; Merged AEE2010 HS1, HS2, EPS dbc files
VERSION "AEE2010_R3_HS1_HS2_EPS_merge"

NS_ :

BS_:

BU_: UTIL__Traminator CMM___Motor_SG CDS___Fahrdynamikregelung BVA___Automatikgetriebe BSI___Kombiinstrument AR2S_StartStop ABS___Antiblockiersystem AVAS RITCS PASS_HCU2 BVN EBB PASS_VCU BSI AAS PASS_BSI FAMILLE_DSG BV CAPT_ALG CAPT_VOL CMM CSS FSE OUTIL_DIAG PROJ SBW SCDT SUSP UC_DIRA UC_FREIN ASR ARTIV PASS_BSM CMF HCU1 HCU2 ECR MCM Tester PSCM
; #############################################################################
; ############################### HS1 B0 #####################################
; #############################################################################

BO_ 3221225472 VECTOR__INDEPENDENT_SIG_MSG: 0 Vector__XXX
 SG_ CURRENT_TIMER_YEAR : 0|8@0+ (1,0) [0|0] "" Vector__XXX
 # Description: Represents the current year used internally by the system timer.
 SG_ CURRENT_TIMER_DAY : 0|12@0+ (1,0) [0|0] "" Vector__XXX
 # Description: Represents the current day used internally by the system timer.
 SG_ CURRENT_TIMER_SECOND : 0|20@0+ (1,0) [0|0] "" Vector__XXX
 # Description: Represents the current second used internally by the system timer.
 SG_ TRANSMISSION_CHECKSUM : 0|4@1+ (1,0) [0|0] "" Vector__XXX
 # Description: Checksum used for verifying transmission data integrity.
 SG_ ENGINE_OFF_TIME_LSB : 0|16@1+ (1,0) [0|65535] "" Vector__XXX
 # Description: Lower 16 bits of engine-off time counter.
 SG_ ENGINE_OFF_TIME_MSB : 0|16@1+ (1,0) [0|65535] "" Vector__XXX
 # Description: Upper 16 bits of engine-off time counter.
 SG_ WAKEUP_REQUEST : 0|1@1+ (1,0) [0|1] "" Vector__XXX
 # Description: Indicates a request to wake up the vehicle’s electronic modules.
 SG_ IMPULSE_START_REQUEST : 0|2@1+ (1,0) [0|3] "" Vector__XXX
 # Description: Request for an impulse-based engine start.
 SG_ MAJOR_START_REQUEST : 0|2@1+ (1,0) [0|3] "" Vector__XXX
 # Description: Main request to start the engine under normal conditions.
 SG_ STARTER_STOP_REQUEST : 0|1@1+ (1,0) [0|1] "" Vector__XXX
 # Description: Indicates a request to stop the starter operation.
 SG_ EHR_CONTROL_STATUS : 0|1@1- (1,0) [0|1] "" Vector__XXX
 # Description: Status bit for Electric Heater Relay (EHR) control.
 SG_ BVM_CHECKSUM : 0|4@1+ (1,0) [0|15] "" Vector__XXX
 # Description: Checksum for manual gearbox message.
 SG_ BVM_COUNTER : 0|4@1+ (1,0) [0|15] "" Vector__XXX
 # Description: Counter for manual gearbox message transmissions.
 SG_ GEARBOX_TORQUE_REQUEST_STATUS : 0|1@1+ (1,0) [0|1] "" Vector__XXX
 # Description: Indicates if a torque request has been issued by the gearbox.
 SG_ TORQUE_SATURATION_ACTIVE : 0|1@1+ (1,0) [0|1] "-" Vector__XXX
 # Description: Indicates whether torque saturation is currently active.
 SG_ FORCED_GMV_ENGAGEMENT : 0|1@1+ (1,0) [0|1] "-" Vector__XXX
 # Description: Indicates forced engagement of the GMV (motorized valve) system.
 SG_ TOTAL_ADDITIONAL_PUMP_MASS : 0|16@0+ (0.05,0) [0|3276.5] "g" Vector__XXX
 # Description: Total mass of additional fluid pumped, measured in grams.
 SG_ LOCAL_IDENTIFIER : 0|8@1+ (1,0) [0|255] "" Vector__XXX
 # Description: Local identification value for internal usage.
 SG_ DIAGNOSTIC_ON_CAN : 0|8@1+ (1,0) [0|255] "" Vector__XXX
 # Description: Indicates a diagnostic session or request on the CAN bus.
 SG_ EOBD_READINESS : 0|1@1+ (1,0) [0|1] "" Vector__XXX
 # Description: Indicates EOBD (European On-Board Diagnostics) readiness status.
 SG_ MAX_TORQUE_STATUS : 0|1@1+ (1,0) [0|1] "" Vector__XXX
 # Description: Indicates whether the maximum torque status is reached.
 SG_ MAX_ENGINE_SPEED_STATUS : 0|1@1+ (1,0) [0|1] "" Vector__XXX
 # Description: Indicates whether the maximum engine speed status is reached.
 SG_ RTE_FUNCTION_ERROR_STATUS : 0|1@1+ (1,0) [0|1] "" Vector__XXX
 # Description: Indicates an error in the runtime environment function.
 SG_ ADDITIONAL_PUMP_VOLUME_INJECTION_STEP : 0|8@1+ (10,0) [0|255] "" Vector__XXX
 # Description: Represents the additional pump volume per injection step in increments of 10.
 SG_ GEARBOX_INPUT_SPEED_FILTERED : 0|12@0+ (2,0) [0|0] "rpm" Vector__XXX
 # Description: Filtered input speed of the gearbox, in revolutions per minute.
 SG_ CONVERTER_SLIP_REDUCED_TORQUE : 0|8@1- (3,-150) [0|0] "Nm" Vector__XXX
 # Description: Reduced converter torque used for slip control, in Newton-meters.
 SG_ TSC_ENGINE_DEMAND_TYPE : 0|1@1+ (1,0) [0|1] "" Vector__XXX
 # Description: Type of engine demand used by the TSC (Torque Security Calculation).
 SG_ CLUTCH_STATE : 0|2@1+ (1,0) [0|3] "" Vector__XXX
 # Description: Indicates the current clutch state or position.
 SG_ GLOW_AUTHORIZATION_STATUS : 0|1@1+ (1,0) [0|1] "" Vector__XXX
 # Description: Shows whether glow plugs are authorized to operate.
 SG_ AR2S_SYSTEM_STATUS : 0|2@1+ (1,0) [0|3] "" Vector__XXX
 # Description: Status of the AR2S start-stop system.
 SG_ STT_RELAUNCH_STATUS : 0|2@1+ (1,0) [0|3] "" Vector__XXX
 # Description: Indicates start-stop engine relaunch authorization.
 SG_ POWER_GENERATOR_SUPPORT_STATE : 0|1@1+ (1,0) [0|1] "" Vector__XXX
 # Description: Shows if the power generator is in a support state.
 SG_ REQUESTED_GEARBOX_TORQUE : 0|8@1+ (2,-100) [-100|408] "Nm" Vector__XXX
 # Description: Torque request that accounts for gearbox demands, in Nm.
 SG_ ACTUAL_ENGINE_TORQUE_NO_GEARBOX : 0|8@1+ (2,-100) [-100|408] "Nm" Vector__XXX
 # Description: Actual engine torque excluding gearbox influence, in Nm.
 SG_ PRODUCTION_STATUS : 0|3@1+ (1,0) [0|7] "" Vector__XXX
 # Description: Indicates the current production or assembly status of the system.
 SG_ ALTERNATOR_FAULT : 0|1@1+ (1,0) [0|1] "" Vector__XXX
 # Description: Signals a detected fault in the alternator.
 SG_ SECONDARY_START_REQUEST : 0|2@1+ (1,0) [0|3] "" Vector__XXX
 # Description: A secondary engine start request, possibly for backup or redundancy.
 SG_ ADDITIONAL_PUMP_LEVEL_STATUS : 0|2@1+ (1,0) [0|3] "" Vector__XXX
 # Description: Current level status of the additional pump.
 SG_ FAP_AVAILABLE_TEMPERATURE : 0|8@1+ (4,-40) [0|255] "°C" Vector__XXX
 # Description: Temperature measurement related to FAP (Diesel Particulate Filter) availability.
 SG_ RVV_COMMAND : 0|2@1+ (1,0) [0|3] "-" Vector__XXX
 # Description: Command bitfield for the RVV (valve or variable geometry) system.
 SG_ RVV_ACTIVATION : 0|1@1+ (1,0) [0|1] "-" Vector__XXX
 # Description: Indicates whether the RVV system is activated.
 SG_ ABS_DISTANCE : 0|16@0+ (0.1,0) [0|6553.5] "m" Vector__XXX
 # Description: Accumulated or measured distance from the ABS system, in meters.
 SG_ RELAY_2_DIAGNOSTIC_RAW : 0|3@1- (1,0) [-4|3] "" Vector__XXX
 # Description: Raw diagnostic value for relay 2.
 SG_ RELAY_1_DIAGNOSTIC_RAW : 0|3@1- (1,0) [0|7] "" Vector__XXX
 # Description: Raw diagnostic value for relay 1.
 SG_ PARTIAL_BYTE_8_STATUS : 0|4@1+ (1,0) [0|15] "" Vector__XXX
 # Description: 4-bit status stored in byte 8, used for partial checks.
 SG_ RESERVED_1 : 0|16@1+ (1,0) [0|255] "-" Vector__XXX
 # Description: Reserved placeholder for future use or alignment.
 SG_ START_STOP_CABIN_REQUEST_RAW : 0|1@1+ (1,0) [0|1] "" Vector__XXX
 # Description: Indicates a raw cabin request related to start-stop operation.
 SG_ INPUT_4 : 0|1@0+ (1,0) [0|0] "" Vector__XXX
 # Description: Generic input 4 placeholder signal for hardware or software usage.
 SG_ INPUT_3 : 0|1@0+ (1,0) [0|0] "" Vector__XXX
 # Description: Generic input 3 placeholder signal for hardware or software usage.
 SG_ INPUT_2 : 0|1@0+ (1,0) [0|0] "" Vector__XXX
 # Description: Generic input 2 placeholder signal for hardware or software usage.
 SG_ INPUT_1 : 0|1@0+ (1,0) [0|0] "" Vector__XXX
 # Description: Generic input 1 placeholder signal for hardware or software usage.
 SG_ CODE_VALUE : 0|8@0+ (1,0) [0|0] "" Vector__XXX
 # Description: Arbitrary code value used for internal processes.
 SG_ OUTPUT_NUMBER : 0|3@0+ (1,0) [0|0] "" Vector__XXX
 # Description: Indicates which output is currently being referenced.
 SG_ OUTPUT_3 : 0|1@0+ (1,0) [0|0] "" Vector__XXX
 # Description: Generic output 3 placeholder signal for hardware or software usage.
 SG_ OUTPUT_2 : 0|1@0+ (1,0) [0|0] "" Vector__XXX
 # Description: Generic output 2 placeholder signal for hardware or software usage.
 SG_ OUTPUT_1 : 0|1@0+ (1,0) [0|0] "" Vector__XXX
 # Description: Generic output 1 placeholder signal for hardware or software usage.
 SG_ OUTPUT_0 : 0|1@0+ (1,0) [0|0] "" Vector__XXX
 # Description: Generic output 0 placeholder signal for hardware or software usage.
 SG_ COMMAND : 0|5@0+ (1,0) [0|0] "" Vector__XXX
 # Description: Generic command signal used in various control processes.
 SG_ FANS_EHR_PUMP_REQUEST : 0|1@1+ (1,0) [0|1] "" Vector__XXX
 # Description: Request for the EHR (electric heater) pump to operate fans.
 SG_ FUEL_CONSUMPTION_STATUS : 0|1@1+ (1,0) [0|0] "" Vector__XXX
 # Description: Status indicating fuel consumption measurement progress.
 SG_ ENGINE_PROTECTION_OVERSPEED_STATUS : 0|2@1+ (1,0) [0|1] "-" Vector__XXX
 # Description: Signals overspeed protection status for the engine.
 SG_ ACCD_PRESSURE_STATUS : 0|2@1+ (1,0) [0|3] "-" Vector__XXX
 # Description: Status of the air conditioning compressor demand (ACCD) pressure.
 SG_ AC_CONTROL_HYSTERESIS_STATUS : 0|1@1+ (1,0) [0|1] "-" Vector__XXX
 # Description: Indicates hysteresis control activity in the air conditioning system.
 SG_ MIL_REQUEST : 0|1@1+ (1,0) [0|1] "-" Vector__XXX
 # Description: Malfunction Indicator Lamp request bit.
 SG_ VERSION_INPUT : 0|4@0+ (1,0) [0|0] "" Vector__XXX
 # Description: Input version number for calibration or firmware identification.
 SG_ DATA_1 : 0|8@0+ (1,0) [0|0] "" Vector__XXX
 # Description: Generic data byte 1 for internal usage.
 SG_ MASK_0 : 0|8@0+ (1,0) [0|0] "" Vector__XXX
 # Description: Mask register 0 used for data filtering or validation.
 SG_ MASK_1 : 0|8@0+ (1,0) [0|0] "" Vector__XXX
 # Description: Mask register 1 used for data filtering or validation.
 SG_ VERSION_MODE : 0|4@0+ (1,0) [0|0] "" Vector__XXX
 # Description: Operating mode version identifier.
 SG_ VERSION_ACTEL : 0|1@0+ (1,0) [0|0] "" Vector__XXX
 # Description: Indicates the version related to the Actel device or logic.
 SG_ VERSION_BAUD_RATE : 0|3@0+ (1,0) [0|0] "" Vector__XXX
 # Description: Baud rate setting version for the communication interface.
 SG_ DATA_0 : 0|8@0+ (1,0) [0|0] "" Vector__XXX
 # Description: Generic data byte 0 for internal usage.
 SG_ DATA_2 : 0|8@0+ (1,0) [0|0] "" Vector__XXX
 # Description: Generic data byte 2 for internal usage.
 SG_ MASK_2 : 0|8@0+ (1,0) [0|0] "" Vector__XXX
 # Description: Mask register 2 used for data filtering or validation.
 SG_ DATA_3 : 0|8@0+ (1,0) [0|0] "" Vector__XXX
 # Description: Generic data byte 3 for internal usage.
 SG_ MASK_3 : 0|8@0+ (1,0) [0|0] "" Vector__XXX
 # Description: Mask register 3 used for data filtering or validation.
 SG_ RATE_VALUE : 0|8@0+ (1,0) [0|0] "" Vector__XXX
 # Description: A rate value or index used for calibrations or internal computations.
 SG_ VERSION_YEAR : 0|8@0+ (1,0) [0|0] "" Vector__XXX
 # Description: Year component of version information.
 SG_ DATA_4 : 0|8@0+ (1,0) [0|0] "" Vector__XXX
 # Description: Generic data byte 4 for internal usage.
 SG_ MASK_4 : 0|8@0+ (1,0) [0|0] "" Vector__XXX
 # Description: Mask register 4 used for data filtering or validation.
 SG_ VERSION_MONTH : 0|8@0+ (1,0) [0|0] "" Vector__XXX
 # Description: Month component of version information.
 SG_ CONFIG_ID_STATUS : 0|11@0+ (1,0) [0|0] "" Vector__XXX
 # Description: Indicates the status of a configuration ID or coding routine.
 SG_ DATA_5 : 0|8@0+ (1,0) [0|0] "" Vector__XXX
 # Description: Generic data byte 5 for internal usage.
 SG_ GET_CONFIG_ID_STATUS : 0|11@0+ (1,0) [0|0] "" Vector__XXX
 # Description: Request or read-back status of the configuration ID.
 SG_ MASK_5 : 0|8@0+ (1,0) [0|0] "" Vector__XXX
 # Description: Mask register 5 used for data filtering or validation.
 SG_ MASK_ID_PERT : 0|11@0+ (1,0) [0|0] "" Vector__XXX
 # Description: Perturbation ID or mask used for debug or test scenarios.
 SG_ VERSION_DATE : 0|8@0+ (1,0) [0|0] "" Vector__XXX
 # Description: Day component of version information (date).
 SG_ DATA_6 : 0|8@0+ (1,0) [0|0] "" Vector__XXX
 # Description: Generic data byte 6 for internal usage.
 SG_ MASK_6 : 0|8@0+ (1,0) [0|0] "" Vector__XXX
 # Description: Mask register 6 used for data filtering or validation.
 SG_ VERSION_MINOR : 0|8@0+ (1,0) [0|0] "" Vector__XXX
 # Description: Minor version number for software or configuration.
 SG_ EDGE_VALUE : 0|2@0+ (1,0) [0|0] "" Vector__XXX
 # Description: Indicates the active edge or transition setting for a signal.
 SG_ CONFIG_ID_CODE : 0|11@0+ (1,0) [0|0] "" Vector__XXX
 # Description: Configuration ID code used for system setup or calibration.
 SG_ DATA_7 : 0|8@1+ (1,0) [0|0] "" Vector__XXX
 # Description: Generic data byte 7 for internal usage.
 SG_ GET_CONFIG_ID_CODE : 0|11@0+ (1,0) [0|0] "" Vector__XXX
 # Description: Request or read-back code for the configuration ID.
 SG_ PERT_ID : 0|11@0+ (1,0) [0|0] "" Vector__XXX
 # Description: Identifier for an internal or external perturbation or test.
 SG_ MASK_7 : 0|8@0+ (1,0) [0|0] "" Vector__XXX
 # Description: Mask register 7 used for data filtering or validation.
 SG_ VERSION_MAJOR : 0|8@0+ (1,0) [0|0] "" Vector__XXX
 # Description: Major version number for software or configuration.
 SG_ CODE_COMMAND : 0|5@0+ (1,0) [0|0] "" Vector__XXX
 # Description: Command code used for controlling or referencing a state machine.
 SG_ SCENARIO_NUMBER : 0|3@0+ (1,0) [0|0] "" Vector__XXX
 # Description: Scenario or case number for testing or logic branching.
 SG_ TCS_ABSOLUTE_TORQUE : 0|8@1+ (2,-100) [-100|408] "Nm" Vector__XXX
 # Description: Absolute torque value requested by TCS (Traction Control System).
 SG_ GEARBOX_EOBD_FAULT : 0|4@1+ (1,0) [0|15] "-" Vector__XXX
 # Description: Indicates the EOBD fault status of the gearbox.
 SG_ BATTERY_TYPE_ESTIMATION_RAW : 0|2@1+ (1,0) [0|3] "" Vector__XXX
 # Description: Raw estimation of the installed battery type.
 SG_ PREDICTED_VOLTAGE_START_RAW : 0|11@0+ (0.01,0) [0|13] "" Vector__XXX
 # Description: Raw predicted voltage level at engine start.
 SG_ PART_BYTE_6_STATUS : 0|4@0+ (1,0) [0|15] "" Vector__XXX
 # Description: 4-bit status stored in byte 6, used for partial checks.
 SG_ BRAKE_RAW_1 : 0|1@1+ (1,0) [0|1] "" Vector__XXX
 # Description: Raw brake signal status from brake switch 1.
 SG_ BRAKE_1 : 0|1@1+ (1,0) [0|1] "" Vector__XXX
 # Description: Processed brake status derived from brake switch 1.
;TODO
;BO_ 968 Dyn_STT_CMM: 2 Vector__XXX
; SG_ P412_Com_stDeadPnt : 2|2@1+ (1,0) [0|3] "" Vector__XXX
; SG_ P428_Com_stCDTReq : 6|2@1+ (1,0) [0|3] "" Vector__XXX

BO_ 2024 Rep_EOBD_On_Can_7E8: 8 Vector__XXX

BO_ 2016 Req_EOBD_On_Can_7E0: 8 Vector__XXX

BO_ 2015 Req_EOBD_On_Can_7DF: 8 Vector__XXX

BO_ 1672 Rep_Diag_On_CAN_688: 8 Vector__XXX

BO_ 1704 Req_Diag_On_CAN_6A8: 8 Vector__XXX
;TODO
;BO_ 1266 Dat3_BSI: 8 Vector__XXX
; SG_ P494_Com_stPrioVoltMax : 49|2@0+ (1,0) [0|0] "" Vector__XXX
; SG_ P493_Com_stPrioVoltMin : 41|2@0+ (1,0) [0|0] "" Vector__XXX
; SG_ P492_Com_uVarProdMax : 63|7@0+ (1,0) [0|0] "" Vector__XXX
; SG_ P491_Com_uVoltCtlProdMax : 55|6@0+ (1,0) [0|0] "" Vector__XXX
; SG_ P490_Com_uVoltCtlProdMin : 47|6@0+ (1,0) [0|0] "" Vector__XXX
; SG_ P437_Com_uBattOpnCir : 24|9@0+ (0.01,0) [0|14] "" Vector__XXX
; SG_ P438_Com_uBattIntRstnRaw : 23|10@0+ (0.01,0) [0|10.23] "" Vector__XXX
; SG_ P429_Com_stSOCInfoInvldRaw : 8|2@1+ (1,0) [0|3] "" Vector__XXX
; SG_ P435_Com_stUCAPRechCrntRaw : 10|2@1+ (1,0) [0|3] "" Vector__XXX
; SG_ P434_Com_rBattChHiRes : 7|10@0+ (0.1,0) [0|100] "" Vector__XXX
;TODO
;BO_ 1173 DAT_DIRA: 3 Vector__XXX
; SG_ P448_Com_bStrgWhlEngStopReqRaw : 21|1@1+ (1,0) [0|1] "" Vector__XXX
; SG_ P447_Com_bStrgWhlEngRstrtReqRaw : 23|1@1+ (1,0) [0|1] "" Vector__XXX
;TODO
;BO_ 809 Dyn_STT_BV: 4 BVA___Automatikgetriebe
; SG_ P340_Com_xChkSum3 : 7|4@0+ (1,0) [0|0] "" Vector__XXX
; SG_ P230_Com_ctGbxCnt3 : 3|4@0+ (1,0) [0|15] "" Vector__XXX
; SG_ P441_Com_bGbxAuthRstrtRaw : 12|1@1+ (1,0) [0|1] "" Vector__XXX
; SG_ P444_Com_bGbxSysFaultRaw : 13|1@1+ (1,0) [0|1] "" Vector__XXX
; SG_ P442_Com_bGbxAuthStopRaw : 15|1@1+ (1,0) [0|1] "" Vector__XXX
; SG_ P443_Com_bGbxRstrtReq : 14|1@1+ (1,0) [0|1] "" Vector__XXX

BO_ 488 DAT3_CMM: 3 Vector__XXX
 SG_ RESERVED_3 : 5|6@0+ (1,0) [0|0] "" Vector__XXX
 # Description: Reserved for future use or alignment in the data structure.
 SG_ RESTART_STSP_COUNTER : 15|16@0+ (1,0) [0|3276750] "" Vector__XXX
 # Description: Counter tracking the number of start-stop restarts.
 SG_ RESTART_STSP_PROGRESS_STATUS : 7|2@0+ (1,0) [0|3] "" Vector__XXX
 # Description: Indicates the current progress status of a start-stop restart sequence.
;TODO
;BO_ 1375 ACQ_NEW_JDD: 1 Vector__XXX
; SG_ P__JDD_Com_stFaultAck : 7|8@0+ (1,0) [0|255] "" Vector__XXX
;TODO
;BO_ 1554 Dat7_BSI: 8 Vector__XXX
; SG_ P409_Com_stRly3DiagRaw : 61|3@1+ (1,0) [0|7] "" Vector__XXX

BO_ 1458 Contexte1_5B2: 8 Vector__XXX
 SG_ EOBD_STATUS : 39|8@0+ (1,0) [0|255] "-" Vector__XXX
 # Description: Indicates the overall EOBD (European On-Board Diagnostics) status code.
 SG_ ADDITIONAL_PUMP_DEFECT_STATUS : 24|8@1+ (1,0) [0|255] "-" Vector__XXX
 # Description: Status code indicating a defect with the additional pump system.
 SG_ ENVIRONMENT_TEMPERATURE : 16|8@1+ (0.5,-40) [-40|87] "°C" Vector__XXX
 # Description: Ambient temperature measured around the environment sensor.
;TODO
;BO_ 1362 DAT4_BSI_AEE2010: 8 Vector__XXX
; SG_ P015_Com_lTotDst : 39|24@0+ (1,0) [0|16777215] "km" Vector__XXX
; SG_ P325_Com_tiEngOff : 7|32@0+ (1,0) [0|1000] "" Vector__XXX
; SG_ P326_Com_ctTmrRst : 63|8@0+ (1,0) [0|255] "" Vector__XXX

BO_ 1101 Vroues_ABR: 8 CDS___Fahrdynamikregelung
 SG_ WHEEL_SPEED_AVERAGE : 55|16@0+ (0.04,0) [0|0] "rpm" Vector__XXX
 # Description: Average wheel speed calculated by the ABS/ESP system, in rpm.
 SG_ REAR_RIGHT_WHEEL_SPEED : 39|16@0+ (0.01,0) [0|655.34] "km/h" Vector__XXX
 # Description: Speed of the rear-right wheel, in km/h.
 SG_ REAR_LEFT_WHEEL_SPEED : 23|16@0+ (0.01,0) [0|655.34] "km/h" Vector__XXX
 # Description: Speed of the rear-left wheel, in km/h.
;TODO
;BO_ 1293 Dat_ABR: 7 ABS___Antiblockiersystem
; SG_ P415_Com_stABSSTTReqRaw : 52|2@1+ (1,0) [0|3] "" Vector__XXX
; SG_ P351_Com_bABSIntvActv : 5|1@1+ (1,0) [0|1] "" Vector__XXX

BO_ 781 Dyn4_FRE: 8 CDS___Fahrdynamikregelung
 SG_ FRONT_LEFT_PASSIVE_WHEEL_SPEED : 7|16@0+ (0.01,0) [0|655.35] "km/h" Vector__XXX
 # Description: Passive measurement of the front-left wheel speed, in km/h.
 SG_ FRONT_RIGHT_PASSIVE_WHEEL_SPEED : 23|16@0+ (0.01,0) [0|655.35] "km/h" Vector__XXX
 # Description: Passive measurement of the front-right wheel speed, in km/h.
 SG_ REAR_LEFT_PASSIVE_WHEEL_SPEED : 39|16@0+ (0.01,0) [0|655.35] "km/h" Vector__XXX
 # Description: Passive measurement of the rear-left wheel speed, in km/h.
 SG_ REAR_RIGHT_PASSIVE_WHEEL_SPEED : 55|16@0+ (0.01,0) [0|655.35] "km/h" Vector__XXX
 # Description: Passive measurement of the rear-right wheel speed, in km/h.
;TODO
;BO_ 1426 Dat6_BSI: 8 CMM___Motor_SG
; SG_ P421_Com_xBattCrnt : 55|16@0+ (1,0) [0|0] "" Vector__XXX
; SG_ P420_Com_stBattCrntMeasRaw : 40|2@1+ (1,0) [0|3] "" Vector__XXX
; SG_ P418_Com_uBattRaw : 28|11@0+ (0.01,5) [5|25.47] "" Vector__XXX
; SG_ P419_Com_stSTTActvRaw : 44|2@1+ (1,0) [0|3] "" Vector__XXX
; SG_ P349_EEM_stAltCtlType : 29|3@1+ (1,0) [0|7] "" Vector__XXX
; SG_ P273_Com_tBatt : 8|8@1+ (0.5,-30) [-30|97.5] "deg C" Vector__XXX
; SG_ P272_Com_rBattCh : 0|8@1+ (1,0) [0|100] "%" Vector__XXX

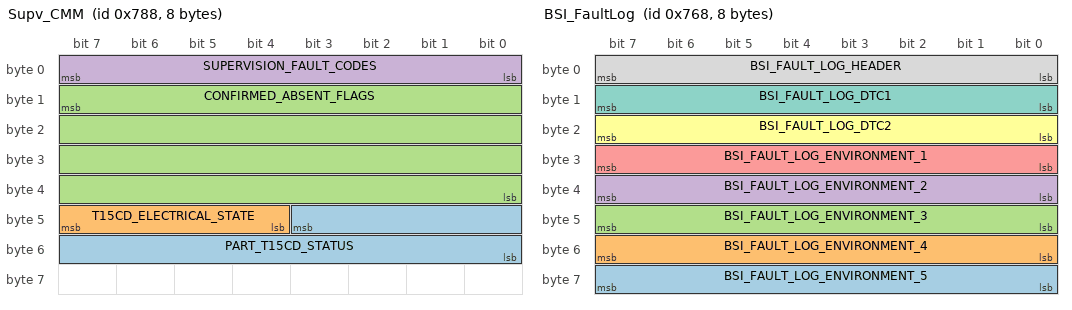
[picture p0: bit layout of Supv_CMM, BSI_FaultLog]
BO_ 1928 Supv_CMM: 8 CMM___Motor_SG
 SG_ PART_T15CD_STATUS : 43|12@0+ (1,0) [0|4095] "" Vector__XXX
 # Description: Status of partial T15CD signals (12-bit field) for supervision.
 SG_ T15CD_ELECTRICAL_STATE : 44|4@1+ (1,0) [0|15] "" Vector__XXX
 # Description: Electrical state representation for T15CD signal.
 SG_ CONFIRMED_ABSENT_FLAGS : 15|32@0+ (1,0) [0|4294967295] "-" Vector__XXX
 # Description: Bitmap flags indicating confirmed absent signals or components.
 SG_ SUPERVISION_FAULT_CODES : 7|8@0+ (1,0) [0|255] "-" Vector__XXX
 # Description: Fault codes used in supervision for diagnosing system issues.
;TODO
;BO_ 1906 FaultLog_Ack: 1 BSI___Kombiinstrument
; SG_ P__FaultLog_Ack : 0|8@1+ (1,0) [0|255] "" Vector__XXX

BO_ 1896 BSI_FaultLog: 8 CMM___Motor_SG
 SG_ BSI_FAULT_LOG_ENVIRONMENT_5 : 56|8@1+ (1,0) [0|255] "" Vector__XXX
 # Description: Environment data snapshot 5 for BSI fault logging.
 SG_ BSI_FAULT_LOG_ENVIRONMENT_4 : 48|8@1+ (1,0) [0|255] "" Vector__XXX
 # Description: Environment data snapshot 4 for BSI fault logging.
 SG_ BSI_FAULT_LOG_ENVIRONMENT_3 : 40|8@1+ (1,0) [0|255] "" Vector__XXX
 # Description: Environment data snapshot 3 for BSI fault logging.
 SG_ BSI_FAULT_LOG_ENVIRONMENT_2 : 32|8@1+ (1,0) [0|255] "" Vector__XXX
 # Description: Environment data snapshot 2 for BSI fault logging.
 SG_ BSI_FAULT_LOG_ENVIRONMENT_1 : 24|8@1+ (1,0) [0|255] "" Vector__XXX
 # Description: Environment data snapshot 1 for BSI fault logging.
 SG_ BSI_FAULT_LOG_DTC2 : 16|8@1+ (1,0) [0|255] "" Vector__XXX
 # Description: Second stored DTC (Diagnostic Trouble Code) value in the BSI fault log.
 SG_ BSI_FAULT_LOG_DTC1 : 8|8@1+ (1,0) [0|255] "" Vector__XXX
 # Description: First stored DTC (Diagnostic Trouble Code) value in the BSI fault log.
 SG_ BSI_FAULT_LOG_HEADER : 0|8@1+ (1,0) [0|255] "" Vector__XXX
 # Description: Header byte identifying the BSI fault log structure.

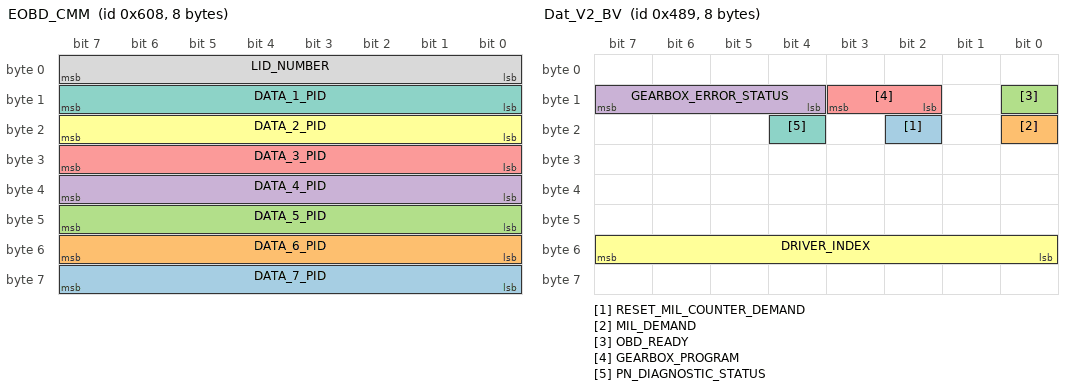
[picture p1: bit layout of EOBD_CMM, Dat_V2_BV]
BO_ 1544 EOBD_CMM: 8 CMM___Motor_SG
 SG_ DATA_7_PID : 56|8@1+ (1,0) [0|0] "" Vector__XXX
 # Description: Byte 7 PID data for EOBD requests or responses.
 SG_ DATA_6_PID : 48|8@1+ (1,0) [0|0] "" Vector__XXX
 # Description: Byte 6 PID data for EOBD requests or responses.
 SG_ DATA_5_PID : 40|8@1+ (1,0) [0|0] "" Vector__XXX
 # Description: Byte 5 PID data for EOBD requests or responses.
 SG_ DATA_4_PID : 32|8@1+ (1,0) [0|0] "" Vector__XXX
 # Description: Byte 4 PID data for EOBD requests or responses.
 SG_ DATA_3_PID : 24|8@1+ (1,0) [0|0] "" Vector__XXX
 # Description: Byte 3 PID data for EOBD requests or responses.
 SG_ DATA_2_PID : 16|8@1+ (1,0) [0|0] "" Vector__XXX
 # Description: Byte 2 PID data for EOBD requests or responses.
 SG_ DATA_1_PID : 8|8@1+ (1,0) [0|0] "" Vector__XXX
 # Description: Byte 1 PID data for EOBD requests or responses.
 SG_ LID_NUMBER : 0|8@1+ (1,0) [0|0] "" Vector__XXX
 # Description: Identifies the Logical ID used for EOBD communication.

BO_ 1416 Dat2_CMM: 8 CMM___Motor_SG
 SG_ AUTH_ADDITIONAL_PUMP : 52|1@1+ (1,0) [0|1] "" Vector__XXX
 # Description: Authorization bit for enabling the additional pump.
 SG_ SYSTEM_VOLTAGE_LOAD_STATUS : 53|1@1+ (1,0) [0|1] "" Vector__XXX
 # Description: Indicates significant load on the electrical system voltage.
 SG_ SYNC_DELAY_START_STOP : 54|1@1+ (1,0) [0|1] "" Vector__XXX
 # Description: Sync delay status for start-stop transitions.
 SG_ ENVIRONMENT_PRESSURE : 42|5@1+ (15,685) [0|1120] "" Vector__XXX
 # Description: Estimated ambient pressure in increments of 15, offset by 685.
 SG_ MMI_CLUTCH_REQUEST : 22|1@1+ (1,0) [0|1] "" Vector__XXX
 # Description: Indicates if the MMI (Man-Machine Interface) requests clutch operation.
 SG_ MMI_START_STOP_AVAILABILITY : 23|1@1+ (1,0) [0|1] "" Vector__XXX
 # Description: Availability status of start-stop from the MMI perspective.
 SG_ STT_FUNCTION_STATUS : 40|2@1+ (1,0) [0|3] "" Vector__XXX
 # Description: Status of the Start-Stop function logic.
 SG_ ENGINE_OPERATION_MODE : 48|4@1+ (1,0) [0|15] "" Vector__XXX
 # Description: Indicates current engine operation mode (e.g., normal, limp, etc.).
 SG_ ENGINE_OIL_LEVEL : 7|8@0- (3,0) [0|0] "" Vector__XXX
 # Description: Measurement of the engine oil level or sensor reading.
 SG_ TARGET_GEAR : 63|3@0+ (1,0) [0|7] "" Vector__XXX
 # Description: The next or target gear selection for manual or automated gearbox.
 SG_ GEAR_SHIFT_DIRECTION : 60|2@0+ (1,0) [0|3] "" Vector__XXX
 # Description: Indicates the direction of the requested gear shift.
 SG_ LIFE_SITUATION : 58|3@0+ (1,0) [0|7] "" Vector__XXX
 # Description: Represents a high-level ‘situation’ or usage mode the vehicle is in.
 SG_ ENGINE_TORQUE_PERCENT : 32|8@1+ (0.39215686275,0) [0|100] "%" Vector__XXX
 # Description: Percentage of engine torque output relative to maximum.
 SG_ OIL_PUMP_SWITCH_STATUS : 16|1@1- (1,0) [0|1] "" Vector__XXX
 # Description: Indicates the on/off status of the oil pump switch.
 SG_ SVS_LAMP_STATUS : 47|1@1+ (1,0) [0|1] "" Vector__XXX
 # Description: Status of the Service Vehicle Soon lamp request.
 SG_ VIRTUAL_FUEL_CONSUMPTION : 24|8@1+ (80,0) [0|20400] "mm^3" Vector__XXX
 # Description: Virtual or estimated fuel consumption volume, in cubic millimeters.
 SG_ ADD_INJECTION_STEP_VOLUME : 8|8@1+ (5,0) [0|255] "mm3" Vector__XXX
 # Description: Volume of injected fluid per additional injection step in mm³.
;TODO
;BO_ 1294 Dat_CLIM: 8 BSI___Kombiinstrument
; SG_ P050_Com_stAC : 0|1@1+ (1,0) [0|1] "-" Vector__XXX
; SG_ P433_Com_bCmptEngStopReqRaw : 2|1@1+ (1,0) [0|1] "" Vector__XXX
; SG_ P432_Com_bCmptEngRstrtReqRaw : 23|1@1+ (1,0) [0|1] "" Vector__XXX
; SG_ P417_Com_stDrvPrsRaw : 25|2@1+ (1,0) [0|3] "" Vector__XXX
; SG_ P220_Com_stPrpMsgRaw : 63|1@1+ (1,0) [0|1] "" Vector__XXX
; SG_ P221_Speed_setPoint_Typ : 61|2@1+ (1,0) [0|3] "" Vector__XXX
; SG_ P222_Typ_PrpCtl_Req : 60|1@1+ (1,0) [0|1] "" Vector__XXX
; SG_ P231_Com_ctBSIFrm : 56|4@1+ (1,0) [0|15] "" Vector__XXX
; SG_ P219_Com_xPrpReqRaw : 48|8@1+ (1,0) [0|255] "" Vector__XXX
; SG_ P208_Com_nACIdlDem : 40|8@1+ (8,0) [0|2032] "" Vector__XXX
; SG_ P210_Com_pwrACDem : 32|8@1+ (25,0) [0|6350] "W" Vector__XXX
; SG_ P189_Com_stEEMIdlDem : 19|1@1+ (1,0) [0|1] "" Vector__XXX
; SG_ P144_Com_bPFltGlw : 17|1@1+ (1,0) [0|1] "-" Vector__XXX
; SG_ P164_Com_stPFltFan : 14|2@1+ (1,0) [0|0] "" Vector__XXX
; SG_ P046_Com_rFanClgDes : 8|6@1+ (2,0) [0|110] "%" Vector__XXX
; SG_ P232_Com_stXVVChkSum : 4|2@1+ (1,0) [0|3] "" Vector__XXX
; SG_ P209_Com_stACRaw : 1|1@1+ (1,0) [0|0] "" Vector__XXX

BO_ 1224 Etat_Crash: 3 BSI___Kombiinstrument
 SG_ RESERVED_CRASH_2 : 23|8@0+ (1,0) [0|0] "-" Vector__XXX
 # Description: Reserved for crash data, placeholder byte 2.
 SG_ CRASH_INFO : 8|1@0+ (1,0) [0|0] "-" Vector__XXX
 # Description: Indicates the presence of crash-related data or status.
 SG_ RESERVED_CRASH_1 : 7|8@0+ (1,0) [0|0] "-" Vector__XXX
 # Description: Reserved for crash data, placeholder byte 1.

BO_ 1161 Dat_V2_BV: 8 BVA___Automatikgetriebe
 SG_ RESET_MIL_COUNTER_DEMAND : 18|1@0+ (1,0) [0|1] "" Vector__XXX
 # Description: Indicates a request to reset the MIL (Malfunction Indicator Lamp) counter.
 SG_ MIL_DEMAND : 16|1@0+ (1,0) [0|1] "" Vector__XXX
 # Description: Demand to illuminate or turn off the MIL.
 SG_ OBD_READY : 8|1@0+ (1,0) [0|1] "" Vector__XXX
 # Description: Indicates if the system is ready for OBD (On-Board Diagnostics).
 SG_ GEARBOX_ERROR_STATUS : 12|4@1+ (1,0) [0|15] "" Vector__XXX
 # Description: Shows the current error status of the automatic gearbox.
 SG_ GEARBOX_PROGRAM : 11|2@0+ (1,0) [0|0] "" Vector__XXX
 # Description: Identifies the selected gearbox program (e.g., sport, eco).
 SG_ DRIVER_INDEX : 48|8@1+ (1,0) [0|255] "" Vector__XXX
 # Description: Driver identifier or index used for personalization.
 SG_ PN_DIAGNOSTIC_STATUS : 20|1@1+ (1,0) [0|1] "" Vector__XXX
 # Description: Indicates whether park/neutral diagnostic logic is active.
;TODO
;BO_ 1160 Dat_CMM: 8 CMM___Motor_SG
; SG_ P056_ACCD_p : 48|8@1+ (25,0) [100|3100] "kPa" Vector__XXX
; SG_ P158_Air_tAFS : 56|8@1+ (1,-40) [-40|214] "°C" Vector__XXX
; SG_ P051_ACCD_stPres : 33|2@1+ (1,0) [0|3] "" Vector__XXX
; SG_ P053_ACCtl_stHys : 32|1@1+ (1,0) [0|1] "" Vector__XXX
; SG_ P011_Oil_tSwmp : 40|8@1+ (1,-40) [-40|213] "" Vector__XXX
; SG_ P154_PFlt_bPFltClnReq : 38|1@1+ (1,0) [0|0] "" Vector__XXX
; SG_ P233_Fid_PFltDef_mp : 31|1@1+ (1,0) [0|1] "" Vector__XXX
; SG_ P063_vehV_bXVVErr : 30|1@1+ (1,0) [0|1] "-" Vector__XXX
; SG_ P296_AOHt_stPmp : 29|1@1+ (1,0) [0|1] "" Vector__XXX
; SG_ P108_Fid_ComAddPmpLvl : 28|1@1+ (1,0) [0|1] "-" Vector__XXX
; SG_ P105_Com_bTtLmp : 27|1@1+ (1,0) [0|1] "-" Vector__XXX
; SG_ P031_GlwLmp_st : 25|1@1+ (1,0) [0|1] "-" Vector__XXX
; SG_ P032_Com_bEngStrt : 24|1@1+ (1,0) [0|1] "-" Vector__XXX
; SG_ P022_Com_nSetPLo : 16|8@1+ (8,0) [0|2032] "1/min" Vector__XXX
; SG_ P021_Com_volFlCons : 8|8@1+ (80,0) [0|20400] "mm^3" Vector__XXX
; SG_ P005_CEngDst_tSens : 0|8@1+ (1,-40) [-40|214] "°C" Vector__XXX

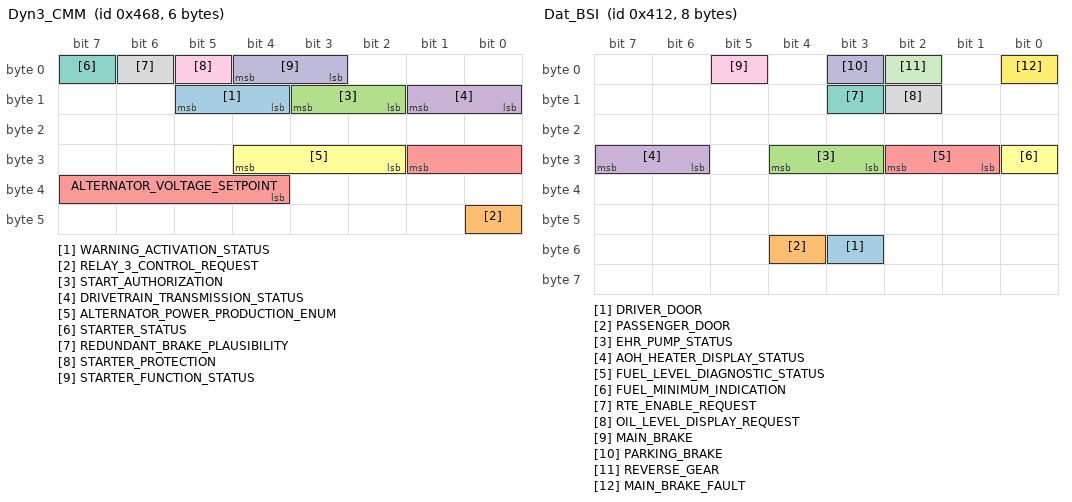
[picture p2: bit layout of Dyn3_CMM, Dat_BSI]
BO_ 1128 Dyn3_CMM: 6 CMM___Motor_SG
 SG_ WARNING_ACTIVATION_STATUS : 13|2@0+ (1,0) [0|0] "" Vector__XXX
 # Description: Indicates the status of any active warnings in the system.
 SG_ RELAY_3_CONTROL_REQUEST : 40|1@1+ (1,0) [0|1] "" Vector__XXX
 # Description: A request bit to control or activate relay 3.
 SG_ START_AUTHORIZATION : 10|2@1+ (1,0) [0|3] "" Vector__XXX
 # Description: Authorization state for engine start logic.
 SG_ DRIVETRAIN_TRANSMISSION_STATUS : 8|2@1+ (1,0) [0|3] "" Vector__XXX
 # Description: Overall status of the drivetrain’s transmission path.
 SG_ ALTERNATOR_VOLTAGE_SETPOINT : 25|6@0+ (1,0) [0|63] "" Vector__XXX
 # Description: Desired output voltage setpoint for the alternator.
 SG_ ALTERNATOR_POWER_PRODUCTION_ENUM : 26|3@1+ (1,0) [0|7] "-" Vector__XXX
 # Description: Enum representing different power production modes of the alternator.
 SG_ STARTER_STATUS : 7|1@1+ (1,0) [0|1] "" Vector__XXX
 # Description: Indicates if the starter is currently active.
 SG_ REDUNDANT_BRAKE_PLAUSIBILITY : 6|1@1+ (1,0) [0|1] "" Vector__XXX
 # Description: Plausibility check for redundant brake signals.
 SG_ STARTER_PROTECTION : 5|1@1+ (1,0) [0|1] "" Vector__XXX
 # Description: Indicates if protection logic is guarding the starter from misuse.
 SG_ STARTER_FUNCTION_STATUS : 3|2@1+ (1,0) [0|3] "" Vector__XXX
 # Description: General status of the starter function (off, requested, running, etc.).
;TODO
;BO_ 1074 Dat_BSI1: 8 BSI___Kombiinstrument
; SG_ P439_Com_bUCAPSWkUpReqRaw : 45|1@1+ (1,0) [0|1] "" Vector__XXX
; SG_ P369_Com_stElecNetRaw : 60|4@1+ (1,0) [0|15] "" Vector__XXX
; SG_ P368_Com_stMnSEVRaw : 48|2@1+ (1,0) [0|3] "" Vector__XXX
; SG_ P367_Com_stCtxJDDRaw : 50|6@1+ (1,0) [0|63] "" Vector__XXX
; SG_ P403_Com_stStaReq : 43|1@1+ (1,0) [0|1] "" Vector__XXX
; SG_ P402_Com_stStaDemActv : 12|2@1+ (1,0) [0|3] "" Vector__XXX
; SG_ P350_Com_bPstVtln : 46|1@1+ (1,0) [0|0] "" Vector__XXX
; SG_ P274_Exh_ctRefl : 40|3@1+ (1,0) [0|7] "" Vector__XXX
; SG_ P276_Com_bOilWkUp : 36|1@1+ (1,0) [0|1] "" Vector__XXX
; SG_ P267_Exh_volRefl : 24|8@1+ (0.5,0) [0|255] "l" Vector__XXX
; SG_ P253_Com_bEngPrepReq : 21|1@1+ (1,0) [0|1] "" Vector__XXX
; SG_ P214_Com_stMnWkUp : 6|2@1+ (1,0) [0|3] "" Vector__XXX
; SG_ P216_Com_bSiaWkUp : 4|1@1+ (1,0) [0|1] "" Vector__XXX
; SG_ P249_Com_stEngStopReq : 0|2@1+ (1,0) [0|3] "" Vector__XXX

BO_ 1042 Dat_BSI: 8 BSI___Kombiinstrument
 SG_ DRIVER_DOOR : 51|1@0+ (1,0) [0|1] "" Vector__XXX
 # Description: Indicates whether the driver door is open (1) or closed (0).
 SG_ PASSENGER_DOOR : 52|1@0+ (1,0) [0|1] "" Vector__XXX
 # Description: Indicates whether the passenger door is open (1) or closed (0).
 SG_ EHR_PUMP_STATUS : 27|2@1+ (1,0) [0|3] "" Vector__XXX
 # Description: Current status of the Electric Heater Relay pump system.
 SG_ AOH_HEATER_DISPLAY_STATUS : 30|2@1+ (1,0) [0|3] "-"  CMM___Motor_SG
 # Description: Display status for the auxiliary heater system.
 SG_ FUEL_LEVEL_DIAGNOSTIC_STATUS : 25|2@1+ (1,0) [0|3] "-" Vector__XXX
 # Description: Diagnostic status for the fuel level sensor.
 SG_ FUEL_MINIMUM_INDICATION : 24|1@1+ (1,0) [0|0] "-" Vector__XXX
 # Description: Indicates low fuel level status.
 SG_ RTE_ENABLE_REQUEST : 11|1@1+ (1,0) [0|1] "" Vector__XXX
 # Description: Request to enable certain runtime environment features.
 SG_ OIL_LEVEL_DISPLAY_REQUEST : 10|1@1+ (1,0) [0|0] "" Vector__XXX
 # Description: Request to display the engine oil level on the instrument cluster.
 SG_ MAIN_BRAKE : 5|1@1+ (1,0) [0|0] "" Vector__XXX
 # Description: Primary brake switch signal for brake pedal position.
 SG_ PARKING_BRAKE : 3|1@0+ (1,0) [0|1] "" Vector__XXX
 # Description: Indicates if the parking brake is engaged.
 SG_ REVERSE_GEAR : 2|1@1+ (1,0) [0|1] "" Vector__XXX
 # Description: Shows if reverse gear is selected.
 SG_ MAIN_BRAKE_FAULT : 0|1@1+ (1,0) [0|1] "-" Vector__XXX
 # Description: Fault status for the main brake system.

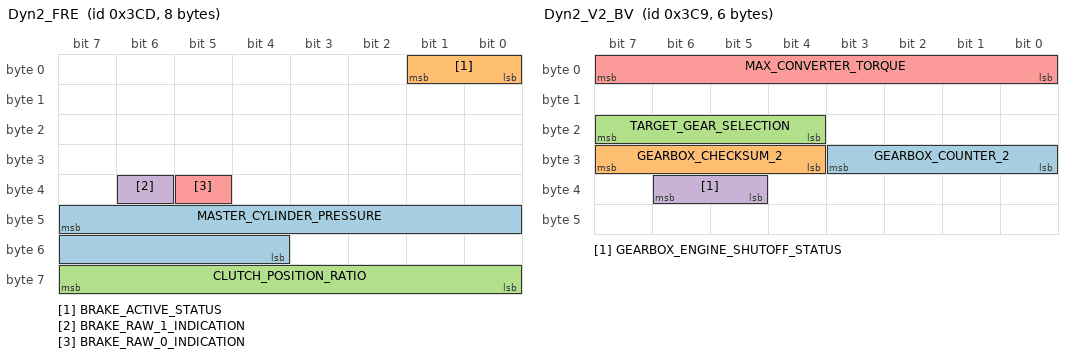
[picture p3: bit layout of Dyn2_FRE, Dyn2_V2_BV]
BO_ 973 Dyn2_FRE: 8 ABS___Antiblockiersystem
 SG_ MASTER_CYLINDER_PRESSURE : 47|12@0+ (1,0) [0|0] "" Vector__XXX
 # Description: Measured pressure in the master cylinder.
 SG_ BRAKE_ACTIVE_STATUS : 0|2@1+ (1,0) [0|4] "" Vector__XXX
 # Description: Indicates the brake activation status as determined by ABS logic.
 SG_ CLUTCH_POSITION_RATIO : 56|8@1+ (0.5,0) [0|255] "%" Vector__XXX
 # Description: Percentage ratio indicating clutch pedal position.
 SG_ BRAKE_RAW_1_INDICATION : 38|1@1+ (1,0) [0|0] "" Vector__XXX
 # Description: Raw indication from brake switch 1.
 SG_ BRAKE_RAW_0_INDICATION : 37|1@1+ (1,0) [0|0] "" Vector__XXX
 # Description: Raw indication from brake switch 0.

BO_ 969 Dyn2_V2_BV: 6 BVA___Automatikgetriebe
 SG_ GEARBOX_COUNTER_2 : 27|4@0+ (1,0) [0|0] "" Vector__XXX
 # Description: Secondary counter for automatic gearbox messages.
 SG_ GEARBOX_CHECKSUM_2 : 31|4@0+ (1,0) [0|15] "" Vector__XXX
 # Description: Checksum used to validate the second gearbox message set.
 SG_ TARGET_GEAR_SELECTION : 23|4@0+ (1,0) [0|0] "" Vector__XXX
 # Description: Desired target gear used by the transmission control.
 SG_ GEARBOX_ENGINE_SHUTOFF_STATUS : 38|2@0+ (1,0) [0|3] "" Vector__XXX
 # Description: Status indicating if the gearbox requests engine shutoff.
 SG_ MAX_CONVERTER_TORQUE : 7|8@0+ (3,-150) [-150|615] "" Vector__XXX
 # Description: Maximum allowable torque through the torque converter.

BO_ 941 Dyn_EasyMove: 8 CDS___Fahrdynamikregelung
 SG_ PARKING_BRAKE_STATUS : 24|3@1+ (1,0) [0|0] "" Vector__XXX
 # Description: Status of the parking brake system.
 SG_ CRUISE_CONTROL_INHIBIT : 17|1@1+ (1,0) [0|1] "" Vector__XXX
 # Description: Inhibits cruise control engagement under certain conditions.
;TODO
;BO_ 909 Dyn_ABR: 8 ABS___Antiblockiersystem
; SG_ P688_Com_bAuthHllAsstStop : 54|1@0+ (1,0) [0|0] "" Vector__XXX
; SG_ P052_Com_aLng : 32|8@1+ (0.08,-14) [-14|6.32] "m/s**2" Vector__XXX
; SG_ P010_Com_v : 7|16@0+ (0.01,0) [0|655.34] "km/h" Vector__XXX

BO_ 904 Dyn_Veh: 7 CMM___Motor_SG
 SG_ LONGITUDINAL_ACCELERATION_ECU : 32|8@1+ (0.08,-14) [-14|6.32] "m/s**2" Vector__XXX
 # Description: Longitudinal acceleration measured or estimated by the ECU.
 SG_ ECU_DISTANCE : 23|16@0+ (0.1,0) [0|6553.5] "m" Vector__XXX
 # Description: Distance measurement or accumulation managed by the ECU, in meters.
 SG_ ECU_VEHICLE_SPEED : 7|16@0+ (0.01,0) [0|655.34] "km/h" Vector__XXX
 # Description: Current vehicle speed as determined by the ECU, in km/h.
;TODO
;BO_ 845 Dyn_CDS: 8 CDS___Fahrdynamikregelung
; SG_ P353_StbIntv_bESPExclvIntvActv : 52|1@1+ (1,0) [0|1] "" Vector__XXX
; SG_ P352_StbIntv_bTCSIntvActv : 50|1@1+ (1,0) [0|1] "" Vector__XXX
; SG_ P157_Com_ctESP : 40|4@1+ (1,0) [0|15] "" Vector__XXX
; SG_ P045_Com_trqDCSRaw : 32|8@1+ (2,-100) [-100|410] "Nm" Vector__XXX
; SG_ P044_Com_trqTCSRaw : 24|8@1+ (2,-100) [-100|410] "Nm" Vector__XXX
; SG_ P043_Com_xTCSStatRaw : 16|8@1+ (3,-150) [-150|612] "Nm" Vector__XXX
; SG_ P147_Com_bESPIntvActv : 6|1@1+ (1,0) [0|0] "" Vector__XXX
; SG_ P088_CutOffForbidden : 3|1@1+ (1,0) [0|1] "-" Vector__XXX
; SG_ P047_Com_stESPIntv : 0|3@1+ (1,0) [0|7] "-"  CMM___Motor_SG

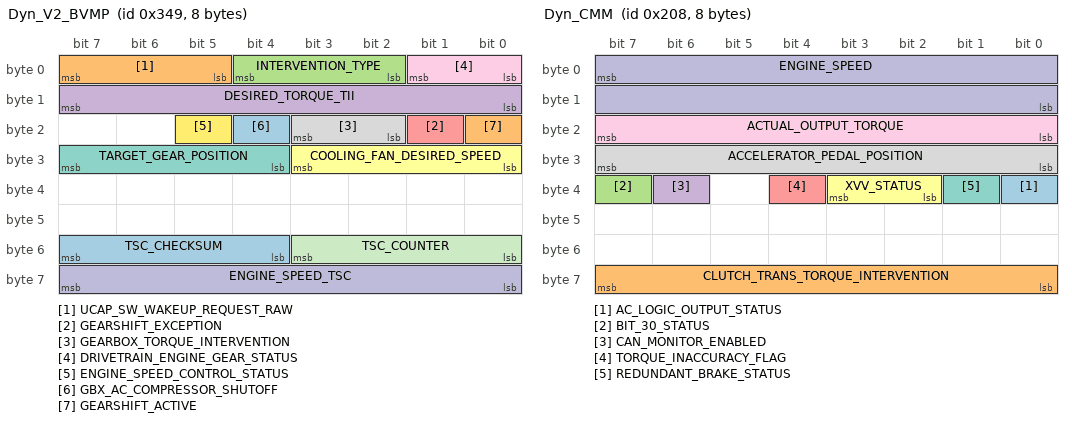
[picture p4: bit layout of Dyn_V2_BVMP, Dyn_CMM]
BO_ 841 Dyn_V2_BVMP: 8 BVA___Automatikgetriebe
 SG_ TSC_CHECKSUM : 55|4@0+ (1,0) [0|15] "-" Vector__XXX
 # Description: Checksum for TSC (Torque Security Calculation) data.
 SG_ UCAP_SW_WAKEUP_REQUEST_RAW : 5|3@1+ (1,0) [0|7] "" Vector__XXX
 # Description: Raw request signal for UCAP (Ultracapacitor) module wakeup.
 SG_ INTERVENTION_TYPE : 2|3@1+ (1,0) [0|7] "" Vector__XXX
 # Description: Type of intervention requested by the gearbox or torque system.
 SG_ DESIRED_TORQUE_TII : 8|8@1+ (1,0) [0|255] "" Vector__XXX
 # Description: Desired torque value for TII (Torque-Integrated Intervention).
 SG_ GEARSHIFT_EXCEPTION : 17|1@1+ (1,0) [0|1] "" Vector__XXX
 # Description: Indicates an exceptional condition during gear shifting.
 SG_ COOLING_FAN_DESIRED_SPEED : 24|4@1+ (1,0) [0|15] "-" Vector__XXX
 # Description: Desired speed setting for the cooling fan.
 SG_ TARGET_GEAR_POSITION : 28|4@1+ (1,0) [0|15] "-" Vector__XXX
 # Description: The intended gear position commanded by the transmission.
 SG_ GEARBOX_TORQUE_INTERVENTION : 18|2@1+ (1,0) [0|3] "" Vector__XXX
 # Description: State of torque intervention in the gearbox.
 SG_ DRIVETRAIN_ENGINE_GEAR_STATUS : 0|2@1+ (1,0) [0|3] "" Vector__XXX
 # Description: High-level status of engine-gear coupling in the drivetrain.
 SG_ ENGINE_SPEED_TSC : 56|8@1+ (25,750) [750|7075] "RPM" Vector__XXX
 # Description: Engine speed used by TSC, offset by 750, in RPM.
 SG_ TSC_COUNTER : 51|4@0+ (1,0) [0|15] "-" Vector__XXX
 # Description: Counter for TSC-related message transmissions.
 SG_ ENGINE_SPEED_CONTROL_STATUS : 21|1@1+ (1,0) [0|1] "-" Vector__XXX
 # Description: Indicates if engine speed control is active.
 SG_ GBX_AC_COMPRESSOR_SHUTOFF : 20|1@1+ (1,0) [0|1] "-" Vector__XXX
 # Description: Gearbox-based AC compressor shutoff condition.
 SG_ GEARSHIFT_ACTIVE : 16|1@1+ (1,0) [0|1] "" Vector__XXX
 # Description: Indicates if a gear shift process is actively happening.

BO_ 840 Dyn2_CMM: 8 CMM___Motor_SG
 SG_ CONVERTER_VALIDATION_STATUS : 35|2@1+ (1,0) [0|3] "-" Vector__XXX
 # Description: Validation status for the torque converter or lockup.
 SG_ T15_STATUS : 54|1@1- (1,0) [0|0] "" Vector__XXX
 # Description: Indicates whether T15 (ignition-run) is active or not.
 SG_ DRIVING_CYCLE_STATUS : 53|1@1- (1,0) [0|0] "" Vector__XXX
 # Description: Shows if the vehicle is in a valid driving cycle.
 SG_ WAKEUP_CONDITION : 52|1@1- (1,0) [0|0] "" Vector__XXX
 # Description: Indicates the condition that triggered a wakeup.
 SG_ MIL_BLINK : 51|1@1- (1,0) [0|0] "" Vector__XXX
 # Description: State of the MIL blink function.
 SG_ MIL_ON : 50|1@1- (1,0) [0|0] "" Vector__XXX
 # Description: State of the MIL on function.
 SG_ OBD_ERROR_PRESENT : 49|1@1- (1,0) [0|0] "" Vector__XXX
 # Description: Indicates the presence of an OBD fault code.
 SG_ STRT_BVMP_AUTH_STATUS : 62|1@1+ (1,0) [0|1] "" Vector__XXX
 # Description: Start authorization status from BVMP (gearbox module).
 SG_ FAN_ACTUAL_RATE : 56|6@1+ (2,0) [0|100] "" Vector__XXX
 # Description: Actual fan rate or speed in percentage.
 SG_ ENGINE_STATUS : 40|4@1+ (1,0) [0|0] "-" Vector__XXX
 # Description: Current engine state (e.g., off, running, cranking).
 SG_ COMPONENT_LOAD_SHEDDING : 37|3@1+ (1,0) [0|7] "" Vector__XXX
 # Description: Indicates load-shedding events for certain components.
 SG_ ESP_ERROR_STATUS : 33|2@1+ (1,0) [0|0] "-" Vector__XXX
 # Description: Shows if an ESP (Electronic Stability Program) error is active.
 SG_ ESP_ACKNOWLEDGMENT : 32|1@1+ (1,0) [0|0] "-" Vector__XXX
 # Description: Acknowledgment flag for ESP requests or errors.
 SG_ FORCED_TORQUE : 24|8@1+ (2,-100) [-100|408] "Nm" Vector__XXX
 # Description: Engine torque forced by certain conditions (e.g., limp mode).
 SG_ AIR_CONDITIONING_PRESSURE : 16|8@1+ (1,110) [110|2904] "kpa" Vector__XXX
 # Description: Measured or estimated AC refrigerant pressure, in kPa.
 SG_ PROPORTIONAL_TORQUE : 8|8@1+ (2,-100) [-100|410] "Nm" Vector__XXX
 # Description: Proportional torque used in certain dynamic controls.
 SG_ GEARBOX_GEAR_STATE : 4|4@1+ (1,0) [0|15] "-" Vector__XXX
 # Description: Current gear in use by the gearbox.
 SG_ FUEL_LEVEL_SENSOR_DEB_STATUS : 0|1@1+ (1,0) [0|1] "" Vector__XXX
 # Description: Debounce status for the fuel level sensor reading.
;TODO
;BO_ 552 Dyn5_CMM: 5 CMM___Motor_SG
; SG_ P388_Com_rClthPedPos : 39|8@0+ (0.5,0) [0|100] "" Vector__XXX
; SG_ P411_Com_stTrqAvlStSp : 12|1@1+ (1,0) [0|0] "" Vector__XXX
; SG_ P410_Com_stEngTrqStSp : 13|1@1+ (1,0) [0|0] "" Vector__XXX
; SG_ P335_Com_ctDyn5CMMCntr : 28|4@1+ (1,0) [0|15] "" Vector__XXX
; SG_ P336_Com_xDyn5CMMChkSum : 24|4@1+ (1,0) [0|15] "" Vector__XXX
; SG_ P334_ACCPed_Position : 16|8@1+ (0.5,0) [0|100] "%" Vector__XXX
; SG_ P321_StatusOfEasyMvTrq : 14|2@1+ (1,0) [0|3] "" Vector__XXX
; SG_ P320_EasyMvTrqInfo : 0|8@1+ (3,-150) [-150|615] "Nm" Vector__XXX

BO_ 520 Dyn_CMM: 8 CMM___Motor_SG
 SG_ AC_LOGIC_OUTPUT_STATUS : 32|1@1+ (1,0) [0|1] "-" Vector__XXX
 # Description: Indicates the current status of AC control logic output.
 SG_ CLUTCH_TRANS_TORQUE_INTERVENTION : 56|8@1+ (2,-100) [-100|410] "Nm" Vector__XXX
 # Description: Torque intervention value used for clutch transitions.
 SG_ BIT_30_STATUS : 39|1@1+ (1,0) [0|0] "-" Vector__XXX
 # Description: Generic bit status, possibly for extension or debugging.
 SG_ CAN_MONITOR_ENABLED : 38|1@1+ (1,0) [0|1] "-" Vector__XXX
 # Description: Indicates if CAN monitoring is currently active.
 SG_ TORQUE_INACCURACY_FLAG : 36|1@1+ (1,0) [0|0] "" Vector__XXX
 # Description: Flag set if the calculated torque is deemed inaccurate.
 SG_ XVV_STATUS : 34|2@1+ (1,0) [0|2] "-" Vector__XXX
 # Description: Status bits for the XVV (variable valve or geometry) system.
 SG_ REDUNDANT_BRAKE_STATUS : 33|1@1+ (1,0) [0|1] "-" Vector__XXX
 # Description: Redundant check for brake activation or readiness.
 SG_ ACCELERATOR_PEDAL_POSITION : 24|8@1+ (0.5,0) [0|100] "%" Vector__XXX
 # Description: Percentage of the accelerator pedal pressed by the driver.
 SG_ ACTUAL_OUTPUT_TORQUE : 16|8@1+ (3,-150) [-150|615] "Nm" Vector__XXX
 # Description: Current actual output torque from the engine in Nm.
 SG_ ENGINE_SPEED : 7|16@0+ (0.125,0) [0|8191.75] "1/min" Vector__XXX
 # Description: Engine speed in increments of 0.125 RPM.

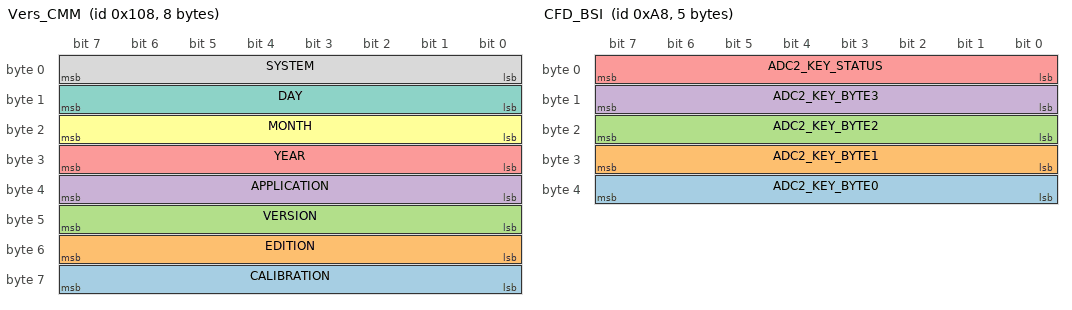
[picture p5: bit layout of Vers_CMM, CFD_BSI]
BO_ 264 Vers_CMM: 8 CMM___Motor_SG
 SG_ CALIBRATION : 56|8@1+ (1,0) [0|255] "-" Vector__XXX
 # Description: Calibration index identifying software calibration variations.
 SG_ EDITION : 48|8@1+ (1,0) [0|255] "-" Vector__XXX
 # Description: Edition number for software or firmware release.
 SG_ VERSION : 40|8@1+ (1,0) [0|255] "-" Vector__XXX
 # Description: Version number indicating major or minor software iteration.
 SG_ APPLICATION : 32|8@1+ (1,0) [0|255] "-" Vector__XXX
 # Description: Application ID or name associated with this software build.
 SG_ YEAR : 24|8@1+ (1,0) [0|255] "-" Vector__XXX
 # Description: Year of build or release for the software.
 SG_ MONTH : 16|8@1+ (1,0) [0|255] "-" Vector__XXX
 # Description: Month of build or release for the software.
 SG_ DAY : 8|8@1+ (1,0) [0|255] "-" Vector__XXX
 # Description: Day of build or release for the software.
 SG_ SYSTEM : 0|8@1+ (1,0) [0|255] "-" Vector__XXX
 # Description: System identifier for high-level software grouping.

BO_ 168 CFD_BSI: 5 BSI___Kombiinstrument
 SG_ ADC2_KEY_BYTE0 : 32|8@1+ (1,0) [0|255] "-" Vector__XXX
 # Description: Byte 0 from the ADC2 key data set.
 SG_ ADC2_KEY_BYTE1 : 24|8@1+ (1,0) [0|255] "-" Vector__XXX
 # Description: Byte 1 from the ADC2 key data set.
 SG_ ADC2_KEY_BYTE2 : 16|8@1+ (1,0) [0|255] "-" Vector__XXX
 # Description: Byte 2 from the ADC2 key data set.
 SG_ ADC2_KEY_BYTE3 : 8|8@1+ (1,0) [0|255] "-"  CMM___Motor_SG
 # Description: Byte 3 from the ADC2 key data set.
 SG_ ADC2_KEY_STATUS : 0|8@1+ (1,0) [0|0] "-" Vector__XXX
 # Description: Status byte for the ADC2 key data set.
;TODO
;BO_ 146 Elec_Int: 1 BSI___Kombiinstrument
; SG_ P__Elec_Int_Cntrl_Word : 7|8@0+ (1,0) [0|255] "" Vector__XXX

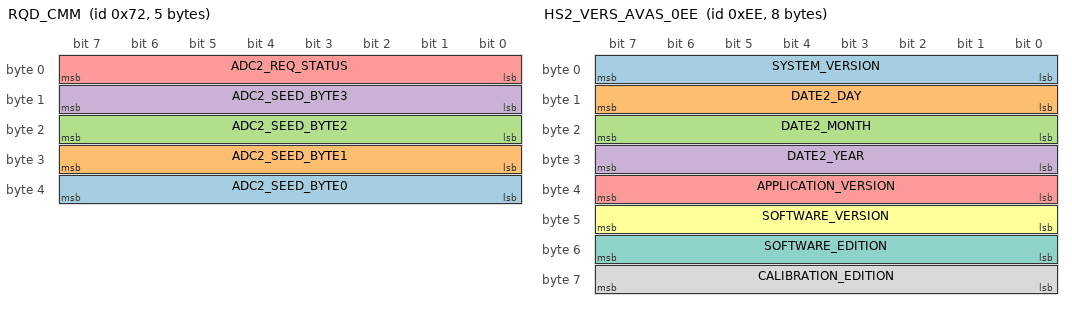
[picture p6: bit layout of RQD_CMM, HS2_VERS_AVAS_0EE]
BO_ 114 RQD_CMM: 5 CMM___Motor_SG
 SG_ ADC2_SEED_BYTE0 : 32|8@1+ (1,0) [0|255] "-"  BSI___Kombiinstrument
 # Description: Seed byte 0 for ADC2-based security or authentication challenge.
 SG_ ADC2_SEED_BYTE1 : 24|8@1+ (1,0) [0|255] "-" Vector__XXX
 # Description: Seed byte 1 for ADC2-based security or authentication challenge.
 SG_ ADC2_SEED_BYTE2 : 16|8@1+ (1,0) [0|255] "-" Vector__XXX
 # Description: Seed byte 2 for ADC2-based security or authentication challenge.
 SG_ ADC2_SEED_BYTE3 : 8|8@1+ (1,0) [0|255] "-" Vector__XXX
 # Description: Seed byte 3 for ADC2-based security or authentication challenge.
 SG_ ADC2_REQ_STATUS : 0|8@1+ (1,0) [0|255] "-" Vector__XXX
 # Description: Status request or result for ADC2-based security operations.
; #############################################################################
; ############################### HS2 B0 #####################################
; #############################################################################
;TODO
;BO_ 146 HS2_INTE_ELECTRON_BSI_092: 1 BSI
; SG_ EFFAC_DEFAUT_DIAG : 0|1@0+ (1,0) [0|0] "" BVN,ARTIV,EBB,AVAS
; SG_ MODE_DIAG : 6|1@0+ (1,0) [0|0] "" BVN,ARTIV,EBB,AVAS
; SG_ DIAG_INTEGRA_ELEC : 7|1@0+ (1,0) [0|0] "" BVN,ARTIV,EBB,AVAS

BO_ 238 HS2_VERS_AVAS_0EE: 8 AVAS
 SG_ SYSTEM_VERSION : 7|8@0+ (1,0) [0|255] "" Vector__XXX
 # Description: System version number for AVAS.
 SG_ DATE2_DAY : 15|8@0+ (1,0) [0|31] "" Vector__XXX
 # Description: Day part of the secondary date reference.
 SG_ DATE2_MONTH : 23|8@0+ (1,0) [0|12] "" Vector__XXX
 # Description: Month part of the secondary date reference.
 SG_ DATE2_YEAR : 31|8@0+ (1,0) [0|99] "" Vector__XXX
 # Description: Year part of the secondary date reference.
 SG_ APPLICATION_VERSION : 39|8@0+ (1,0) [0|255] "" Vector__XXX
 # Description: Application version for AVAS.
 SG_ SOFTWARE_VERSION : 47|8@0+ (1,0) [0|255] "" Vector__XXX
 # Description: Software version number for AVAS system.
 SG_ SOFTWARE_EDITION : 55|8@0+ (1,0) [0|255] "" Vector__XXX
 # Description: Edition identifier for the AVAS software release.
 SG_ CALIBRATION_EDITION : 63|8@0+ (1,0) [0|255] "" Vector__XXX
 # Description: Edition identifier for AVAS calibration data.

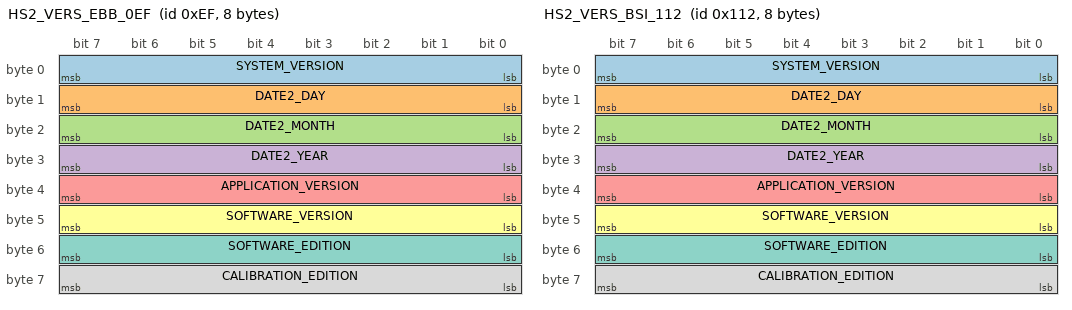
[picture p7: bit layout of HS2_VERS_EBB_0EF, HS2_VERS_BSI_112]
BO_ 239 HS2_VERS_EBB_0EF: 8 EBB
 SG_ SYSTEM_VERSION : 7|8@0+ (1,0) [0|255] "" Vector__XXX
 # Description: System version number for EBB.
 SG_ DATE2_DAY : 15|8@0+ (1,0) [0|31] "" Vector__XXX
 # Description: Day part of the secondary date reference.
 SG_ DATE2_MONTH : 23|8@0+ (1,0) [0|12] "" Vector__XXX
 # Description: Month part of the secondary date reference.
 SG_ DATE2_YEAR : 31|8@0+ (1,0) [0|99] "" Vector__XXX
 # Description: Year part of the secondary date reference.
 SG_ APPLICATION_VERSION : 39|8@0+ (1,0) [0|255] "" Vector__XXX
 # Description: Application version for EBB.
 SG_ SOFTWARE_VERSION : 47|8@0+ (1,0) [0|255] "" Vector__XXX
 # Description: Software version number for EBB system.
 SG_ SOFTWARE_EDITION : 55|8@0+ (1,0) [0|255] "" Vector__XXX
 # Description: Edition identifier for the EBB software release.
 SG_ CALIBRATION_EDITION : 63|8@0+ (1,0) [0|255] "" Vector__XXX
 # Description: Edition identifier for EBB calibration data.

BO_ 274 HS2_VERS_BSI_112: 8 BSI
 SG_ SYSTEM_VERSION : 7|8@0+ (1,0) [0|255] "" Vector__XXX
 # Description: System version number for BSI.
 SG_ DATE2_DAY : 15|8@0+ (1,0) [0|31] "" Vector__XXX
 # Description: Day part of the secondary date reference.
 SG_ DATE2_MONTH : 23|8@0+ (1,0) [0|12] "" Vector__XXX
 # Description: Month part of the secondary date reference.
 SG_ DATE2_YEAR : 31|8@0+ (1,0) [0|99] "" Vector__XXX
 # Description: Year part of the secondary date reference.
 SG_ APPLICATION_VERSION : 39|8@0+ (1,0) [0|255] "" Vector__XXX
 # Description: Application version for BSI.
 SG_ SOFTWARE_VERSION : 47|8@0+ (1,0) [0|255] "" Vector__XXX
 # Description: Software version number for BSI system.
 SG_ SOFTWARE_EDITION : 55|8@0+ (1,0) [0|255] "" Vector__XXX
 # Description: Edition identifier for the BSI software release.
 SG_ CALIBRATION_EDITION : 63|8@0+ (1,0) [0|255] "" Vector__XXX
 # Description: Edition identifier for BSI calibration data.

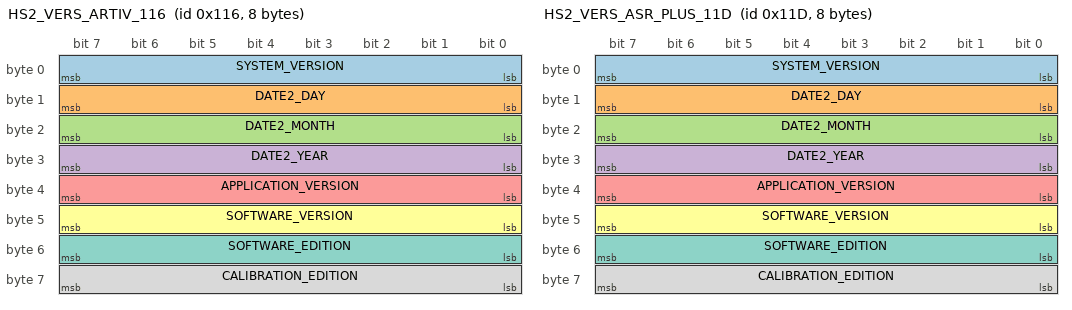
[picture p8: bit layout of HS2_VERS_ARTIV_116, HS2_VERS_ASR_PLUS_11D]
BO_ 278 HS2_VERS_ARTIV_116: 8 ARTIV
 SG_ SYSTEM_VERSION : 7|8@0+ (1,0) [0|255] "" Vector__XXX
 # Description: System version number for ARTIV.
 SG_ DATE2_DAY : 15|8@0+ (1,0) [0|31] "" Vector__XXX
 # Description: Day part of the secondary date reference.
 SG_ DATE2_MONTH : 23|8@0+ (1,0) [0|12] "" Vector__XXX
 # Description: Month part of the secondary date reference.
 SG_ DATE2_YEAR : 31|8@0+ (1,0) [0|99] "" Vector__XXX
 # Description: Year part of the secondary date reference.
 SG_ APPLICATION_VERSION : 39|8@0+ (1,0) [0|255] "" Vector__XXX
 # Description: Application version for ARTIV.
 SG_ SOFTWARE_VERSION : 47|8@0+ (1,0) [0|255] "" Vector__XXX
 # Description: Software version number for ARTIV system.
 SG_ SOFTWARE_EDITION : 55|8@0+ (1,0) [0|255] "" Vector__XXX
 # Description: Edition identifier for the ARTIV software release.
 SG_ CALIBRATION_EDITION : 63|8@0+ (1,0) [0|255] "" Vector__XXX
 # Description: Edition identifier for ARTIV calibration data.

BO_ 285 HS2_VERS_ASR_PLUS_11D: 8 MCM
 SG_ SYSTEM_VERSION : 7|8@0+ (1,0) [0|255] "" Vector__XXX
 # Description: System version number for MCM (ASR Plus).
 SG_ DATE2_DAY : 15|8@0+ (1,0) [0|31] "" Vector__XXX
 # Description: Day part of the secondary date reference.
 SG_ DATE2_MONTH : 23|8@0+ (1,0) [0|12] "" Vector__XXX
 # Description: Month part of the secondary date reference.
 SG_ DATE2_YEAR : 31|8@0+ (1,0) [0|99] "" Vector__XXX
 # Description: Year part of the secondary date reference.
 SG_ APPLICATION_VERSION : 39|8@0+ (1,0) [0|255] "" Vector__XXX
 # Description: Application version for the ASR Plus module.
 SG_ SOFTWARE_VERSION : 47|8@0+ (1,0) [0|255] "" Vector__XXX
 # Description: Software version number for the ASR Plus system.
 SG_ SOFTWARE_EDITION : 55|8@0+ (1,0) [0|255] "" Vector__XXX
 # Description: Edition identifier for the ASR Plus software release.
 SG_ CALIBRATION_EDITION : 63|8@0+ (1,0) [0|255] "" Vector__XXX
 # Description: Edition identifier for ASR Plus calibration data.

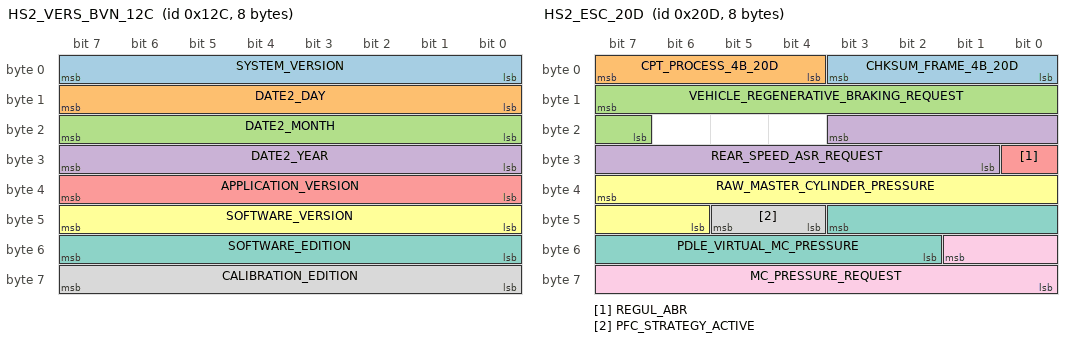
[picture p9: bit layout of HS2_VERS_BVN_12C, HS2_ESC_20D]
BO_ 300 HS2_VERS_BVN_12C: 8 BVN
 SG_ SYSTEM_VERSION : 7|8@0+ (1,0) [0|255] "" Vector__XXX
 # Description: System version number for BVN.
 SG_ DATE2_DAY : 15|8@0+ (1,0) [0|31] "" Vector__XXX
 # Description: Day part of the secondary date reference.
 SG_ DATE2_MONTH : 23|8@0+ (1,0) [0|12] "" Vector__XXX
 # Description: Month part of the secondary date reference.
 SG_ DATE2_YEAR : 31|8@0+ (1,0) [0|99] "" Vector__XXX
 # Description: Year part of the secondary date reference.
 SG_ APPLICATION_VERSION : 39|8@0+ (1,0) [0|255] "" Vector__XXX
 # Description: Application version for the BVN module.
 SG_ SOFTWARE_VERSION : 47|8@0+ (1,0) [0|255] "" Vector__XXX
 # Description: Software version number for BVN system.
 SG_ SOFTWARE_EDITION : 55|8@0+ (1,0) [0|255] "" Vector__XXX
 # Description: Edition identifier for the BVN software release.
 SG_ CALIBRATION_EDITION : 63|8@0+ (1,0) [0|255] "" Vector__XXX
 # Description: Edition identifier for BVN calibration data.

BO_ 525 HS2_ESC_20D: 8 UC_FREIN
 SG_ CHKSUM_FRAME_4B_20D : 3|4@0+ (1,0) [0|0] "" EBB,CMM
 # Description: 4-bit checksum for the 20D frame.
 SG_ CPT_PROCESS_4B_20D : 7|4@0+ (1,0) [0|15] "" EBB,CMM
 # Description: Process counter for the 20D frame data.
 SG_ VEHICLE_REGENERATIVE_BRAKING_REQUEST : 15|9@0+ (1,-2500) [-2500|0] "N.m" EBB,CMM
 # Description: Regenerative braking torque request for the vehicle, in Nm.
 SG_ REAR_SPEED_ASR_REQUEST : 19|11@0+ (1,10) [0|18000] "tr/min" EBB,CMM
 # Description: Rear wheel speed request for ASR in revolutions per minute.
 SG_ REGUL_ABR : 24|1@0+ (1,0) [0|0] "" EBB,CMM
 # Description: Indicates if Anti-Block Regulator is active or required.
 SG_ RAW_MASTER_CYLINDER_PRESSURE : 39|10@0+ (0.3,-30) [-30|276.3] "bar" EBB,CMM
 # Description: Unfiltered master cylinder pressure reading, in bar.
 SG_ PDLE_VIRTUAL_MC_PRESSURE : 43|10@0+ (0.25,0) [0|250] "bar" EBB,CMM
 # Description: Virtual pedal pressure for the master cylinder, in bar.
 SG_ PFC_STRATEGY_ACTIVE : 45|2@0+ (1,0) [0|0] "" EBB,CMM
 # Description: Indicates if the Pressure Flow Control strategy is active.
 SG_ MC_PRESSURE_REQUEST : 49|10@0+ (0.25,0) [0|250] "bar" EBB,CMM
 # Description: Requested master cylinder pressure, in bar.

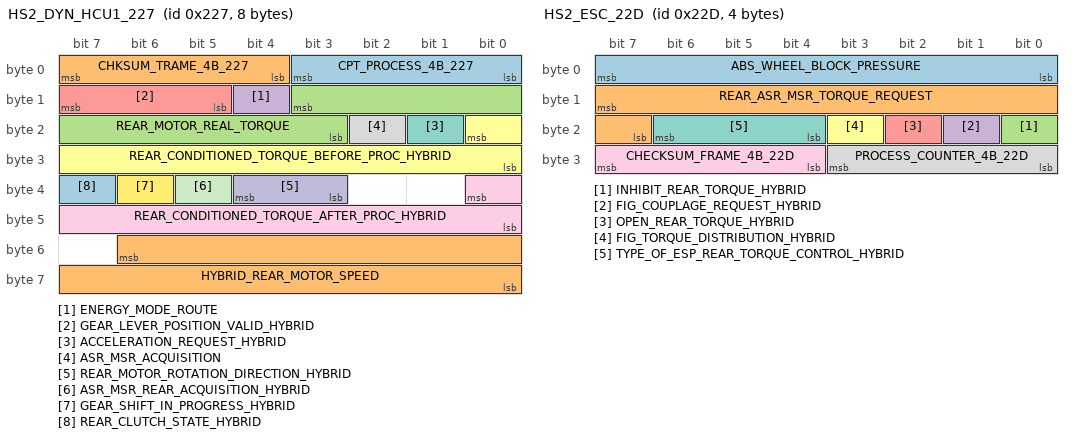
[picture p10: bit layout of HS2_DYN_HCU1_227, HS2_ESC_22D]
BO_ 551 HS2_DYN_HCU1_227: 8 PASS_HCU2
 SG_ CPT_PROCESS_4B_227 : 3|4@0+ (1,0) [0|15] "" BSI,UC_FREIN
 # Description: Process counter for frame 227 data.
 SG_ CHKSUM_TRAME_4B_227 : 7|4@0+ (1,0) [0|0] "" BSI,UC_FREIN
 # Description: 4-bit checksum for frame 227 data.
 SG_ REAR_MOTOR_REAL_TORQUE : 11|9@0- (2,0) [-250|250] "N.m" BSI,UC_FREIN
 # Description: Actual measured torque of the rear motor in Nm.
 SG_ ENERGY_MODE_ROUTE : 12|1@0+ (1,0) [0|0] "" BSI,UC_FREIN
 # Description: Indicates the route-based energy management mode.
 SG_ GEAR_LEVER_POSITION_VALID_HYBRID : 15|3@0+ (1,0) [0|0] "" BSI,UC_FREIN
 # Description: Valid gear lever positions for a hybrid system.
 SG_ REAR_CONDITIONED_TORQUE_BEFORE_PROC_HYBRID : 16|9@0+ (2,-500) [-500|500] "N.m" BSI,UC_FREIN
 # Description: Conditioned rear axle torque (before processing) in a hybrid setup.
 SG_ ACCELERATION_REQUEST_HYBRID : 17|1@0+ (1,0) [0|0] "" BSI,UC_FREIN
 # Description: Indicates an acceleration request in a hybrid scenario.
 SG_ ASR_MSR_ACQUISITION : 18|1@0+ (1,0) [0|0] "" BSI,UC_FREIN
 # Description: Captures anti-slip regulation or motor slip regulation data.
 SG_ REAR_CONDITIONED_TORQUE_AFTER_PROC_HYBRID : 32|9@0+ (2,-500) [-500|500] "N.m" BSI,UC_FREIN
 # Description: Conditioned rear axle torque (after processing) in a hybrid setup.
 SG_ REAR_MOTOR_ROTATION_DIRECTION_HYBRID : 36|2@0+ (1,0) [0|0] "" BSI,UC_FREIN
 # Description: Direction of rotation for the rear hybrid motor.
 SG_ ASR_MSR_REAR_ACQUISITION_HYBRID : 37|1@0+ (1,0) [0|0] "" BSI,UC_FREIN
 # Description: Captures anti-slip or motor slip regulation data for the rear hybrid axle.
 SG_ GEAR_SHIFT_IN_PROGRESS_HYBRID : 38|1@0+ (1,0) [0|0] "" BSI,UC_FREIN
 # Description: Indicates a gear shift is in progress in a hybrid context.
 SG_ REAR_CLUTCH_STATE_HYBRID : 39|1@0+ (1,0) [0|0] "" BSI,UC_FREIN
 # Description: State of the rear clutch in hybrid mode.
 SG_ HYBRID_REAR_MOTOR_SPEED : 54|15@0+ (1,-16000) [-16000|16000] "tr/min" BSI,UC_FREIN
 # Description: Speed of the rear motor in a hybrid configuration, in revolutions per minute.

BO_ 552 HS2_BGE_DYN5_CMM_228: 8 PASS_BSI
 SG_ EASY_MOVE_TORQUE_INFO : 7|8@0+ (2,-100) [-100|408] "N.m" CMF,RITCS,UC_FREIN,BV,ARTIV,HCU2
 # Description: Torque value for easy-move functionality (creep, hill-hold, etc.).
 SG_ ENGINE_SPEED_OVERFLOW_INDICATOR : 10|2@0+ (1,0) [0|0] "" CMF,RITCS,UC_FREIN,BV,ARTIV,HCU2
 # Description: Indicates an overflow or invalid state for engine speed monitoring.
 SG_ SECURITY_HARD_POINT : 11|1@0+ (1,0) [0|0] "" CMF,RITCS,UC_FREIN,BV,ARTIV,HCU2
 # Description: Hard point in software ensuring a secure reference or fallback.
 SG_ HILL_ASSIST_TORQUE_AVAILABLE : 12|1@0+ (1,0) [0|0] "" CMF,RITCS,UC_FREIN,BV,ARTIV,HCU2
 # Description: Indicates that hill assist torque is available to the driver.
 SG_ PRECISE_MOTOR_TORQUE : 13|1@0+ (1,0) [0|0] "" CMF,RITCS,UC_FREIN,BV,ARTIV,HCU2
 # Description: Indicates a precise torque measurement is available or used.
 SG_ UNCERTAIN_EASY_MOVE_TORQUE : 15|2@0+ (1,0) [0|0] "" CMF,RITCS,UC_FREIN,BV,ARTIV,HCU2
 # Description: Indicates an uncertainty or fallback in easy-move torque calculation.
 SG_ ACCELERATOR_PEDAL_EFFECT : 23|8@0+ (0.5,0) [0|100] "%" CMF,RITCS,UC_FREIN,BV,ARTIV,HCU2
 # Description: Effect of accelerator pedal input on a specific function or torque.
 SG_ CHECKSUM_DYN5_CMM : 27|4@0+ (1,0) [0|0] "" CMF,RITCS,UC_FREIN,BV,ARTIV,HCU2
 # Description: Checksum for the Dyn5 CMM frame to ensure data integrity.
 SG_ PROCESS_COUNTER_4B_228 : 31|4@0+ (1,0) [0|15] "" CMF,RITCS,UC_FREIN,BV,ARTIV,HCU2
 # Description: Process counter for frame 228 data.
 SG_ CLUTCH_PEDAL_POSITION_CMM : 39|8@0+ (0.5,0) [0|100] "%" CMF,RITCS,UC_FREIN,BV,ARTIV,HCU2
 # Description: Clutch pedal position as measured or interpreted by CMM.
 SG_ HYBRID_PRESSURE_MASTER_2 : 47|8@0+ (5,0) [0|1200] "hPa" CMF,RITCS,UC_FREIN,BV,ARTIV,HCU2
 # Description: Hybrid brake circuit or master pressure reading 2 in hPa.
 SG_ MASTER_PRESSURE_RELATIVE_CMM : 47|8@0+ (5,0) [0|1200] "hPa" CMF,RITCS,UC_FREIN,BV,ARTIV,HCU2
 # Description: Master cylinder relative pressure used by CMM, in hPa.
 SG_ RDT_AUTHORIZATION : 53|1@0+ (1,0) [0|0] "" CMF,RITCS,UC_FREIN,BV,ARTIV,HCU2
 # Description: Authorization bit for RDT (possibly real driving torque or test).
 SG_ FREEWHEELING_REQUEST : 55|2@0+ (1,0) [0|0] "" CMF,RITCS,UC_FREIN,BV,ARTIV,HCU2
 # Description: Indicates a driver or system request for freewheeling.
 SG_ MAX_INSTANTANEOUS_POTENTIAL_TORQUE : 63|8@0+ (2,-100) [-100|408] "N.m" CMF,RITCS,UC_FREIN,BV,ARTIV,HCU2
 # Description: Maximum instantaneous potential torque available to the driver.

BO_ 557 HS2_ESC_22D: 4 UC_FREIN
 SG_ ABS_WHEEL_BLOCK_PRESSURE : 7|8@0+ (1,0) [0|250] "bar" CMM,EBB
 # Description: Pressure level indicating wheel block threshold for ABS.
 SG_ REAR_ASR_MSR_TORQUE_REQUEST : 15|9@0+ (1,-250) [-250|250] "N.m" CMM,EBB
 # Description: Torque request for anti-slip or motor slip regulation on rear axle.
 SG_ INHIBIT_REAR_TORQUE_HYBRID : 16|1@0+ (1,0) [0|0] "" CMM,EBB
 # Description: Signal to inhibit rear axle torque in hybrid setup.
 SG_ FIG_COUPLAGE_REQUEST_HYBRID : 17|1@0+ (1,0) [0|0] "" CMM,EBB
 # Description: Request to figure or set up rear axle coupling in hybrid mode.
 SG_ OPEN_REAR_TORQUE_HYBRID : 18|1@0+ (1,0) [0|0] "" CMM,EBB
 # Description: Signal to open or free rear axle torque path in hybrid.
 SG_ FIG_TORQUE_DISTRIBUTION_HYBRID : 19|1@0+ (1,0) [0|0] "" CMM,EBB
 # Description: Requests the distribution of torque in a hybrid context.
 SG_ TYPE_OF_ESP_REAR_TORQUE_CONTROL_HYBRID : 22|3@0+ (1,0) [0|0] "" CMM,EBB
 # Description: Specifies the type of rear torque control used by ESP in hybrid.
 SG_ PROCESS_COUNTER_4B_22D : 27|4@0+ (1,0) [0|15] "" CMM,EBB
 # Description: Process counter for frame 22D data.
 SG_ CHECKSUM_FRAME_4B_22D : 31|4@0+ (1,0) [0|0] "" CMM,EBB
 # Description: 4-bit checksum for frame 22D data.

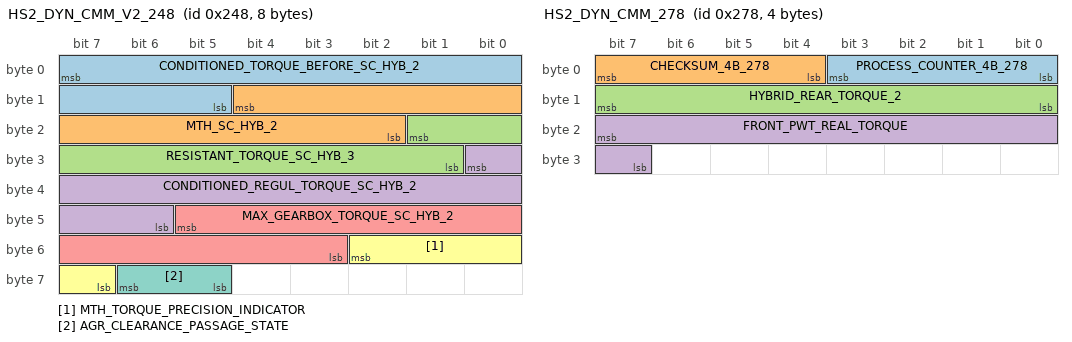
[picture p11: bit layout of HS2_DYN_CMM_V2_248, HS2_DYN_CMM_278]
BO_ 584 HS2_DYN_CMM_V2_248: 8 CMM
 SG_ CONDITIONED_TORQUE_BEFORE_SC_HYB_2 : 7|11@0+ (0.5,-500) [-500|500] "N.m" UC_FREIN
 # Description: Torque conditioned before SC processing in hybrid mode.
 SG_ MTH_SC_HYB_2 : 12|11@0+ (0.5,-500) [-500|500] "N.m" UC_FREIN
 # Description: Motor torque in a hybrid SC scenario.
 SG_ RESISTANT_TORQUE_SC_HYB_3 : 17|9@0+ (0.5,0) [0|255] "N.m" UC_FREIN
 # Description: Resistant torque in a hybrid SC scenario, possibly friction or load.
 SG_ CONDITIONED_REGUL_TORQUE_SC_HYB_2 : 24|11@0+ (0.5,-500) [-500|500] "N.m" UC_FREIN
 # Description: Regulated torque after SC in hybrid mode.
 SG_ MAX_GEARBOX_TORQUE_SC_HYB_2 : 45|11@0+ (0.5,-500) [-500|500] "N.m" UC_FREIN
 # Description: Maximum gearbox torque for SC in hybrid mode.
 SG_ MTH_TORQUE_PRECISION_INDICATOR : 50|4@0+ (1,0) [1|10] "Sans unité" UC_FREIN
 # Description: Indicates the precision level of the measured motor torque.
 SG_ AGR_CLEARANCE_PASSAGE_STATE : 62|2@0+ (1,0) [0|0] "" UC_FREIN
 # Description: State indicating the clearance passage in the aggregator logic.

BO_ 632 HS2_DYN_CMM_278: 4 CMM
 SG_ PROCESS_COUNTER_4B_278 : 3|4@0+ (1,0) [0|15] "" UC_FREIN
 # Description: Process counter for frame 278 data.
 SG_ CHECKSUM_4B_278 : 7|4@0+ (1,0) [0|0] "" UC_FREIN
 # Description: 4-bit checksum for frame 278 data.
 SG_ HYBRID_REAR_TORQUE_2 : 15|8@0+ (2,-250) [-250|250] "N.m" UC_FREIN
 # Description: Rear torque for hybrid system reference 2 in Nm.
 SG_ FRONT_PWT_REAL_TORQUE : 23|9@0- (2,0) [-400|400] "N.m" UC_FREIN
 # Description: Actual front powertrain torque in Nm.

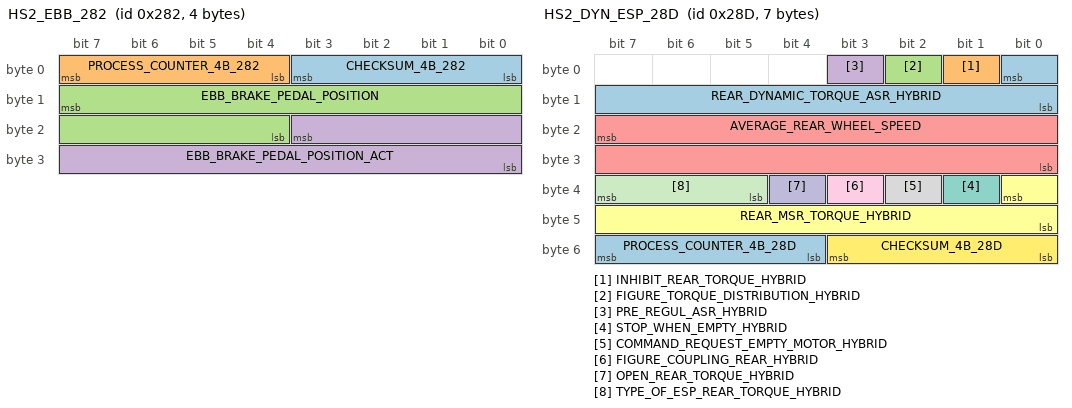
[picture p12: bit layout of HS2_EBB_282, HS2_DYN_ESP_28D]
BO_ 642 HS2_EBB_282: 4 EBB
 SG_ CHECKSUM_4B_282 : 3|4@0+ (1,0) [0|0] "" UC_FREIN
 # Description: 4-bit checksum for frame 282 data.
 SG_ PROCESS_COUNTER_4B_282 : 7|4@0+ (1,0) [0|15] "" UC_FREIN
 # Description: Process counter for frame 282 data.
 SG_ EBB_BRAKE_PEDAL_POSITION : 15|12@0+ (0.015625,-5) [-5|47] "mm" UC_FREIN
 # Description: Measured brake pedal position in mm from the EBB system.
 SG_ EBB_BRAKE_PEDAL_POSITION_ACT : 19|12@0+ (0.015625,-5) [-5|47] "mm" UC_FREIN
 # Description: Actual verified brake pedal position reading from EBB.

BO_ 653 HS2_DYN_ESP_28D: 7 UC_FREIN
 SG_ REAR_DYNAMIC_TORQUE_ASR_HYBRID : 0|9@0+ (2,-500) [-500|500] "N.m" BSI,HCU2
 # Description: Represents the dynamic torque applied to the rear axle for anti-slip regulation (ASR) in a hybrid configuration. Measured in Newton-meters (N.m).
 SG_ INHIBIT_REAR_TORQUE_HYBRID : 1|1@0+ (1,0) [0|0] "" BSI,HCU2
 # Description: Signal to inhibit rear axle torque in hybrid setup.
 SG_ FIGURE_TORQUE_DISTRIBUTION_HYBRID : 2|1@0+ (1,0) [0|0] "" BSI,HCU2
 # Description: Requests the distribution of rear torque in a hybrid context.
 SG_ PRE_REGUL_ASR_HYBRID : 3|1@0+ (1,0) [0|0] "" BSI,HCU2
 # Description: Indicates a pre-regulation step for ASR in hybrid mode.
 SG_ AVERAGE_REAR_WHEEL_SPEED : 23|16@0+ (0.04,0) [0|2621] "tr/min" BSI,HCU2
 # Description: Average rotational speed of rear wheels, in revolutions per minute.
 SG_ REAR_MSR_TORQUE_HYBRID : 32|9@0+ (2,-500) [-500|500] "N.m" BSI,HCU2
 # Description: Motor slip regulation torque for the rear axle in a hybrid system.
 SG_ STOP_WHEN_EMPTY_HYBRID : 33|1@0+ (1,0) [0|0] "" BSI,HCU2
 # Description: Indicates if the system can stop when certain conditions (empty) are met.
 SG_ COMMAND_REQUEST_EMPTY_MOTOR_HYBRID : 34|1@0+ (1,0) [0|0] "" BSI,HCU2
 # Description: Requests an empty or 0 torque command from the rear hybrid motor.
 SG_ FIGURE_COUPLING_REAR_HYBRID : 35|1@0+ (1,0) [0|0] "" BSI,HCU2
 # Description: Requests coupling logic for the rear hybrid system.
 SG_ OPEN_REAR_TORQUE_HYBRID : 36|1@0+ (1,0) [0|0] "" BSI,HCU2
 # Description: Signals opening or freeing the rear torque path in hybrid.
 SG_ TYPE_OF_ESP_REAR_TORQUE_HYBRID : 39|3@0+ (1,0) [0|0] "" BSI,HCU2
 # Description: Specifies the type of rear torque control used by ESP in hybrid mode.
 SG_ CHECKSUM_4B_28D : 51|4@0+ (1,0) [0|0] "" BSI,HCU2
 # Description: 4-bit checksum for frame 28D data.
 SG_ PROCESS_COUNTER_4B_28D : 55|4@0+ (1,0) [0|15] "" BSI,HCU2
 # Description: Process counter for frame 28D data.

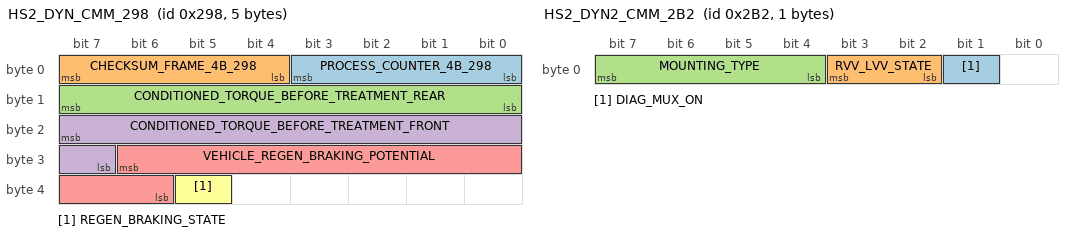
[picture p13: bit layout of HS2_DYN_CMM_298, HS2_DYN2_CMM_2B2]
BO_ 664 HS2_DYN_CMM_298: 5 CMM
 SG_ PROCESS_COUNTER_4B_298 : 3|4@0+ (1,0) [0|15] "" UC_FREIN
 # Description: Process counter for frame 298 data.
 SG_ CHECKSUM_FRAME_4B_298 : 7|4@0+ (1,0) [0|0] "" UC_FREIN
 # Description: 4-bit checksum for frame 298 data.
 SG_ CONDITIONED_TORQUE_BEFORE_TREATMENT_REAR : 15|8@0+ (2,-250) [-250|250] "N.m" UC_FREIN
 # Description: Conditioned rear torque before further treatment, in Nm.
 SG_ CONDITIONED_TORQUE_BEFORE_TREATMENT_FRONT : 23|9@0+ (2,-400) [-400|400] "N.m" UC_FREIN
 # Description: Conditioned front torque before further treatment, in Nm.
 SG_ VEHICLE_REGEN_BRAKING_POTENTIAL : 30|9@0+ (5,-2500) [-2500|0] "N.m" UC_FREIN
 # Description: Potential regenerative braking torque for the vehicle in Nm.
 SG_ REGEN_BRAKING_STATE : 37|1@0+ (1,0) [0|0] "" UC_FREIN
 # Description: Indicates the active state of regenerative braking.

BO_ 690 HS2_DYN2_CMM_2B2: 1 BSI
 SG_ DIAG_MUX_ON : 1|1@0+ (1,0) [0|0] "" BVN,ARTIV,CAPT_VOL,ECR,CMF,AVAS
 # Description: Indicates whether diagnostic multiplexer is enabled.
 SG_ RVV_LVV_STATE : 3|2@0+ (1,0) [0|0] "" BVN,ARTIV,CAPT_VOL,ECR,CMF,AVAS
 # Description: State of RVV/LVV functions.
 SG_ MOUNTING_TYPE : 7|4@0+ (1,0) [0|0] "" BVN,ARTIV,CAPT_VOL,ECR,CMF,AVAS
 # Description: Represents a particular mounting or configuration type.

BO_ 694 HS2_DYN1_MDD_ETAT_2B6: 8 ARTIV
 SG_ GEAR_TYPE : 54|1@0+ (1,0) [0|0] "" CMM,UC_FREIN,BSI,PASS_HCU2,CMF
 # Description: Indicates the gearbox type or ratio type being used.
 SG_ MIN_TIME_FOR_DESIRED_GEAR : 15|6@0+ (0.1,0) [0|6.2] "s" CMM,UC_FREIN,BSI,PASS_HCU2,CMF
 # Description: Minimum time required for achieving the desired gear shift.
 SG_ MIN_TIME_FOR_MONITORED_GEAR : 15|6@0+ (0.1,0) [0|6.2] "s" CMM,UC_FREIN,BSI,PASS_HCU2,CMF
 # Description: Minimum time required for achieving the monitored gear shift.
 SG_ MDD_DESIRED_DECELERATION : 7|8@0+ (0.05,-10.65) [-10.65|2] "m/s2" CMM,UC_FREIN,BSI,PASS_HCU2,CMF
 # Description: Desired deceleration from the MDD system.
 SG_ POTENTIAL_TORQUE_WHEEL_REQUEST : 9|2@0+ (1,0) [0|0] "" CMM,UC_FREIN,BSI,PASS_HCU2,CMF
 # Description: Request to apply a certain wheel torque potential in MDD.
 SG_ GMP_POTENTIAL_WHEEL_TORQUE : 23|12@0+ (4,-4000) [-4000|11000] "N.m" CMM,UC_FREIN,BSI,PASS_HCU2,CMF
 # Description: Potential wheel torque from the powertrain (GMP).
 SG_ ACC_STATUS : 27|4@0+ (1,0) [0|0] "" CMM,UC_FREIN,BSI,PASS_HCU2,CMF
 # Description: Current status of ACC (Adaptive Cruise Control) logic.
 SG_ GMP_WHEEL_TORQUE : 39|14@0+ (1,-4000) [-4000|11000] "N.m" CMM,UC_FREIN,BSI,PASS_HCU2,CMF
 # Description: Actual wheel torque provided by the powertrain.
 SG_ WHEEL_TORQUE_REQUEST : 41|2@0+ (1,0) [0|0] "" CMM,UC_FREIN,BSI,PASS_HCU2,CMF
 # Description: Request to apply or remove a specific wheel torque.
 SG_ FA_SYSTEM_STATE : 50|3@0+ (1,0) [0|0] "" CMM,UC_FREIN,BSI,PASS_HCU2,CMF
 # Description: State of the FA (Forward Assist) or fallback function.
 SG_ MDD_DECEL_TYPE : 52|2@0+ (1,0) [0|0] "" CMM,UC_FREIN,BSI,PASS_HCU2,CMF
 # Description: Type of deceleration used by the MDD system.
 SG_ MDD_PLT_DECEL_REQUEST : 53|1@0+ (1,0) [0|0] "" CMM,UC_FREIN,BSI,PASS_HCU2,CMF
 # Description: Indicates a request for deceleration from the MDD system.
 SG_ PREFILL_REQUEST : 55|1@0+ (1,0) [0|0] "" CMM,UC_FREIN,BSI,PASS_HCU2,CMF
 # Description: Requests prefill of brake or system pressures.
 SG_ DYN_ACC_CHECKSUM : 59|4@0+ (1,0) [0|0] "" CMM,UC_FREIN,BSI,PASS_HCU2,CMF
 # Description: 4-bit checksum for the dynamic ACC data.
 SG_ DYN_ACC_PROCESS_COUNTER : 63|4@0+ (1,0) [0|15] "" CMM,UC_FREIN,BSI,PASS_HCU2,CMF
 # Description: Process counter for the dynamic ACC data.

BO_ 696 HS2_DYN_CMM_2B8: 1 CMM
 SG_ MINIMUM_TORQUE : 7|8@0+ (2,-100) [-100|408] "N.m" UC_FREIN,BV
 # Description: The minimum torque output currently available or set.

BO_ 717 HS2_DYN_UCF_2CD: 3 UC_FREIN
 SG_ AUTOMATIC_BRAKING_PRESSURE : 7|8@0+ (0.2,0) [0|50.6] "bar" BV,BVN
 # Description: Automatically applied brake pressure in bar for safety or ADAS.
 SG_ YAW_RATE : 15|16@0- (0.1,0) [-100|100] "Degré/s" BV,BVN
 # Description: Measured yaw rate of the vehicle, in degrees per second.

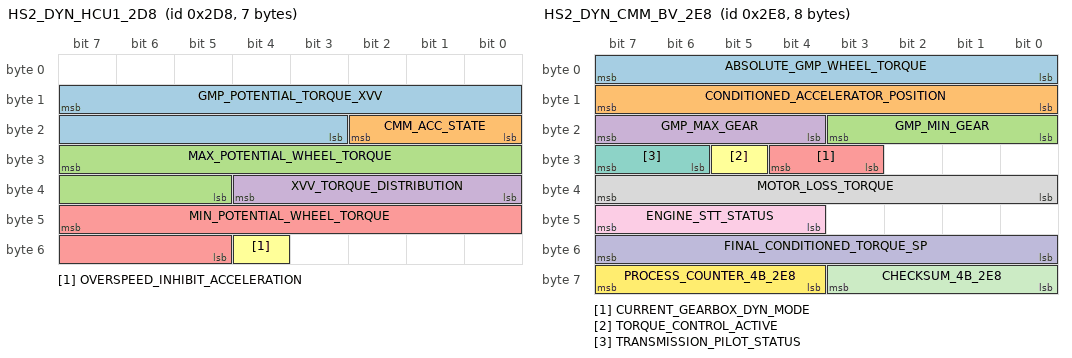
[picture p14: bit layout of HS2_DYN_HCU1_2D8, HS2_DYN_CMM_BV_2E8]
BO_ 728 HS2_DYN_HCU1_2D8: 7 PASS_HCU2
 SG_ GMP_POTENTIAL_TORQUE_XVV : 15|13@0+ (2,-4000) [-4000|11000] "N.m" ARTIV
 # Description: Potential torque from the powertrain in an XVV context.
 SG_ CMM_ACC_STATE : 18|3@0+ (1,0) [0|0] "" ARTIV
 # Description: State of the ACC logic as interpreted by the CMM in a hybrid system.
 SG_ MAX_POTENTIAL_WHEEL_TORQUE : 31|11@0+ (8,-4000) [-4000|11000] "N.m" ARTIV
 # Description: Maximum wheel torque potential in a hybrid scenario.
 SG_ XVV_TORQUE_DISTRIBUTION : 36|5@0+ (5,0) [0|100] "%" ARTIV
 # Description: Distribution percentage of torque for XVV system (front-rear).
 SG_ MIN_POTENTIAL_WHEEL_TORQUE : 47|11@0+ (8,-4000) [-4000|11000] "N.m" ARTIV
 # Description: Minimum wheel torque potential in a hybrid scenario.
 SG_ OVERSPEED_INHIBIT_ACCELERATION : 52|1@0+ (1,0) [0|0] "" ARTIV
 # Description: Inhibits acceleration if overspeed condition is met.

BO_ 744 HS2_DYN_CMM_BV_2E8: 8 CMM
 SG_ ABSOLUTE_GMP_WHEEL_TORQUE : 7|8@0+ (20,-1000) [-1000|4000] "N.m" BV
 # Description: Absolute wheel torque available from the powertrain.
 SG_ CONDITIONED_ACCELERATOR_POSITION : 15|8@0+ (0.5,0) [0|100] "%" BV
 # Description: Accelerator pedal position after conditioning or filtering.
 SG_ GMP_MIN_GEAR : 19|4@0+ (1,0) [0|0] "" BV
 # Description: Indicates the minimum gear ratio allowed by GMP logic.
 SG_ GMP_MAX_GEAR : 23|4@0+ (1,0) [0|0] "" BV
 # Description: Indicates the maximum gear ratio allowed by GMP logic.
 SG_ CURRENT_GEARBOX_DYN_MODE : 28|2@0+ (1,0) [0|0] "" BV
 # Description: Shows the dynamic mode of the gearbox (normal, sport, etc.).
 SG_ TORQUE_CONTROL_ACTIVE : 29|1@0+ (1,0) [0|0] "" BV
 # Description: Indicates if the torque control function is active.
 SG_ TRANSMISSION_PILOT_STATUS : 31|2@0+ (1,0) [0|0] "" BV
 # Description: Status of the transmission pilot or actuator logic.
 SG_ MOTOR_LOSS_TORQUE : 39|8@0+ (2,-100) [-100|408] "N.m" BV
 # Description: Estimated torque loss due to mechanical or electrical losses.
 SG_ ENGINE_STT_STATUS : 47|4@0+ (1,0) [0|0] "" BV
 # Description: Engine start-stop status from the gearbox perspective.
 SG_ FINAL_CONDITIONED_TORQUE_SP : 55|8@0+ (2,-100) [-100|408] "" BV
 # Description: Final conditioned torque setpoint for the powertrain.
 SG_ CHECKSUM_4B_2E8 : 59|4@0+ (1,0) [0|0] "" BV
 # Description: 4-bit checksum for frame 2E8 data.
 SG_ PROCESS_COUNTER_4B_2E8 : 63|4@0+ (1,0) [0|15] "" BV
 # Description: Process counter for frame 2E8 data.

BO_ 758 HS2_DYN_MDD_ETAT_2F6: 8 ARTIV
 SG_ DETECTED_TARGET : 0|1@0+ (1,0) [0|0] "" BSI,CMM,UC_FREIN,CMF
 # Description: Indicates if a target object or vehicle has been detected.
 SG_ RESUME_CONDITION_REQUEST : 2|2@0+ (1,0) [0|0] "" BSI,CMM,UC_FREIN,CMF
 # Description: Request to resume normal conditions after deceleration or stop.
 SG_ BLIND_SPOT_SENSOR : 4|1@0+ (1,0) [0|0] "" BSI,CMM,UC_FREIN,CMF
 # Description: Indicates an active or faulty blind spot sensor reading.
 SG_ ARC_VISUAL_COLLISION_ALERT : 5|1@0+ (1,0) [0|0] "" BSI,CMM,UC_FREIN,CMF
 # Description: Requests a visual collision alert for the ARC system.
 SG_ ARC_AUDIO_COLLISION_ALERT : 6|1@0+ (1,0) [0|0] "" BSI,CMM,UC_FREIN,CMF
 # Description: Requests an audio collision alert for the ARC system.
 SG_ ARC_HAPTIC_COLLISION_ALERT : 7|1@0+ (1,0) [0|0] "" BSI,CMM,UC_FREIN,CMF
 # Description: Requests a haptic collision alert (e.g., seat vibration).
 SG_ INTER_VEHICLE_DISTANCE : 15|10@0+ (0.25,0) [0|255.5] "m" BSI,CMM,UC_FREIN,CMF
 # Description: Calculated distance to the preceding vehicle in meters.
 SG_ ARC_STATE : 19|4@0+ (1,0) [0|0] "" BSI,CMM,UC_FREIN,CMF
 # Description: Current state of the ARC system logic.
 SG_ FA_INFO_IN_PROGRESS : 20|1@0+ (1,0) [0|0] "" BSI,CMM,UC_FREIN,CMF
 # Description: Indicates that a forward assist (FA) event is in progress.
 SG_ AEB_ENABLED : 21|1@0+ (1,0) [0|0] "" BSI,CMM,UC_FREIN,CMF
 # Description: Automatic Emergency Braking enable status.
 SG_ DRIVER_AWAY_REQUEST : 33|1@0+ (1,0) [0|0] "" BSI,CMM,UC_FREIN,CMF
 # Description: Indicates a driver request to move away from a standstill.
 SG_ DISPLAY_INTERVEHICLE_TIME : 39|6@0+ (0.1,0) [0|6.1] "s" BSI,CMM,UC_FREIN,CMF
 # Description: Displays the measured time gap to the vehicle ahead in seconds.
 SG_ MDD_PLT_DECEL_REQUEST : 42|1@0+ (1,0) [0|0] "" BSI,CMM,UC_FREIN,CMF
 # Description: MDD system requests deceleration from the driver or vehicle.
 SG_ FA_STATE : 47|3@0+ (1,0) [0|0] "" BSI,CMM,UC_FREIN,CMF
 # Description: Forward assist state machine status.
 SG_ DYN_ACC2_CHECKSUM : 51|4@0+ (1,0) [0|0] "" BSI,CMM,UC_FREIN,CMF
 # Description: 4-bit checksum for the dynamic ACC2 data.
 SG_ DYN_ACC2_PROCESS_COUNTER : 55|4@0+ (1,0) [0|15] "" BSI,CMM,UC_FREIN,CMF
 # Description: Process counter for the dynamic ACC2 data.
 SG_ TARGET_POSITION : 63|3@0+ (1,0) [0|0] "" BSI,CMM,UC_FREIN,CMF
 # Description: Position of the tracked target (e.g., lane index, lateral offset).

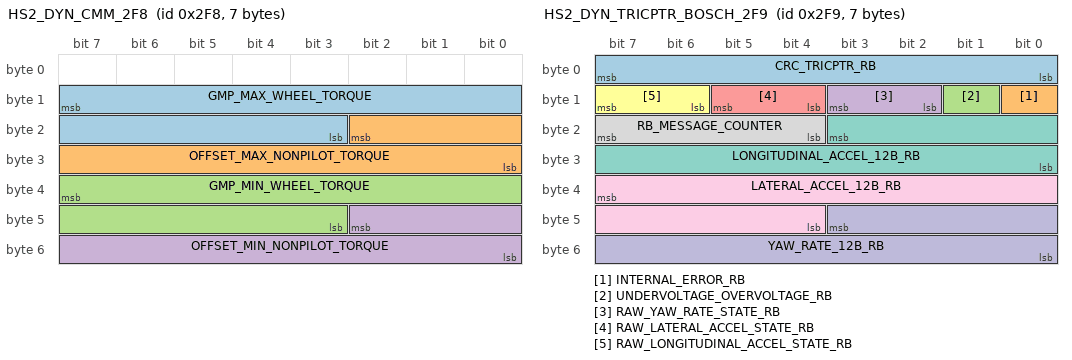
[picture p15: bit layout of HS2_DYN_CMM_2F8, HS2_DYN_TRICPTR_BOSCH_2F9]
BO_ 760 HS2_DYN_CMM_2F8: 7 CMM
 SG_ GMP_MAX_WHEEL_TORQUE : 15|13@0+ (2,-4000) [-4000|11000] "N.m" CMF,ARTIV,UC_FREIN
 # Description: Maximum wheel torque available from the powertrain.
 SG_ OFFSET_MAX_NONPILOT_TORQUE : 18|11@0+ (2,0) [0|4000] "N.m" CMF,ARTIV,UC_FREIN
 # Description: Offset or additional margin for max torque in non-pilot mode.
 SG_ GMP_MIN_WHEEL_TORQUE : 39|13@0+ (2,-4000) [-4000|11000] "N.m" CMF,ARTIV,UC_FREIN
 # Description: Minimum wheel torque possible from the powertrain.
 SG_ OFFSET_MIN_NONPILOT_TORQUE : 42|11@0+ (2,0) [0|4000] "N.m" CMF,ARTIV,UC_FREIN
 # Description: Offset or additional margin for min torque in non-pilot mode.

BO_ 761 HS2_DYN_TRICPTR_BOSCH_2F9: 7 CAPT_ALG
 SG_ CRC_TRICPTR_RB : 7|8@0+ (1,0) [0|255] "" RITCS,UC_FREIN
 # Description: CRC for the TRICPTR_RB sensor data from Bosch.
 SG_ INTERNAL_ERROR_RB : 8|1@0+ (1,0) [0|0] "" RITCS,UC_FREIN
 # Description: Indicates an internal sensor or system error.
 SG_ UNDERVOLTAGE_OVERVOLTAGE_RB : 9|1@0+ (1,0) [0|0] "" RITCS,UC_FREIN
 # Description: Voltage supply outside valid range for the sensor.
 SG_ RAW_YAW_RATE_STATE_RB : 11|2@0+ (1,0) [0|0] "" RITCS,UC_FREIN
 # Description: Raw state bits for the yaw rate sensor reading.
 SG_ RAW_LATERAL_ACCEL_STATE_RB : 13|2@0+ (1,0) [0|0] "" RITCS,UC_FREIN
 # Description: Raw state bits for the lateral acceleration sensor reading.
 SG_ RAW_LONGITUDINAL_ACCEL_STATE_RB : 15|2@0+ (1,0) [0|0] "" RITCS,UC_FREIN
 # Description: Raw state bits for the longitudinal acceleration sensor reading.
 SG_ LONGITUDINAL_ACCEL_12B_RB : 19|12@0+ (0.02,-40.96) [-40.96|40.92] "m/s2" RITCS,UC_FREIN
 # Description: Longitudinal acceleration in 12-bit format from the Bosch sensor.
 SG_ RB_MESSAGE_COUNTER : 23|4@0+ (1,0) [0|15] "" RITCS,UC_FREIN
 # Description: Counter to track the number of RB sensor messages sent.
 SG_ LATERAL_ACCEL_12B_RB : 39|12@0+ (0.02,-40.96) [-40.96|40.92] "m/s2" RITCS,UC_FREIN
 # Description: Lateral acceleration in 12-bit format from the Bosch sensor.
 SG_ YAW_RATE_12B_RB : 43|12@0+ (0.08,-163.84) [-163.84|163.68] "Degré/s" RITCS,UC_FREIN
 # Description: Yaw rate in 12-bit format from the Bosch sensor.

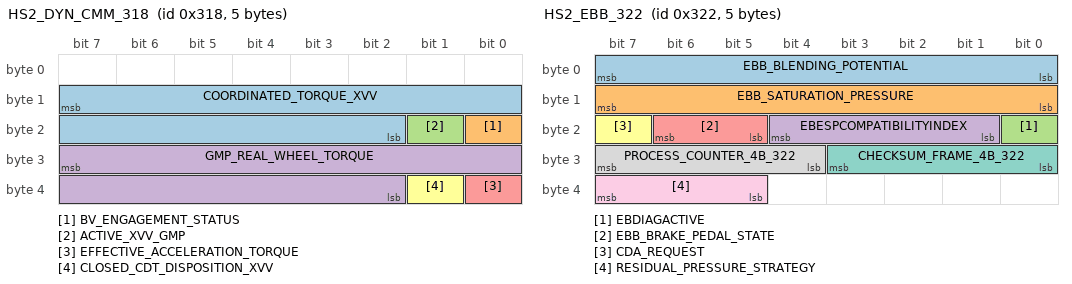
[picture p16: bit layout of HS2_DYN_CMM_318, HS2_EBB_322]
BO_ 792 HS2_DYN_CMM_318: 5 CMM
 SG_ COORDINATED_TORQUE_XVV : 15|14@0+ (1,-4000) [-4000|11000] "N.m" CMF,ARTIV,UC_FREIN
 # Description: Coordinated torque for the XVV (extended variable valve) system.
 SG_ BV_ENGAGEMENT_STATUS : 16|1@0+ (1,0) [0|0] "" CMF,ARTIV,UC_FREIN
 # Description: Shows if the gearbox is actively engaged with the engine.
 SG_ ACTIVE_XVV_GMP : 17|1@0+ (1,0) [0|0] "" CMF,ARTIV,UC_FREIN
 # Description: Indicates if the extended variable valve or GMP feature is active.
 SG_ GMP_REAL_WHEEL_TORQUE : 31|14@0+ (1,-4000) [-4000|11000] "N.m" CMF,ARTIV,UC_FREIN
 # Description: Actual wheel torque provided by the GMP (powertrain).
 SG_ EFFECTIVE_ACCELERATION_TORQUE : 32|1@0+ (1,0) [0|0] "" CMF,ARTIV,UC_FREIN
 # Description: Indicates the effective torque used for acceleration.
 SG_ CLOSED_CDT_DISPOSITION_XVV : 33|1@0+ (1,0) [0|0] "" CMF,ARTIV,UC_FREIN
 # Description: Indicates a closed conduction state in the XVV context.

BO_ 802 HS2_EBB_322: 5 EBB
 SG_ EBB_BLENDING_POTENTIAL : 7|8@0+ (0.5,0) [0|125] "bar" UC_FREIN
 # Description: Potential brake blending pressure offered by the EBB system, in bar.
 SG_ EBB_SATURATION_PRESSURE : 15|8@0+ (1,0) [0|250] "bar" UC_FREIN
 # Description: Maximum saturation pressure limit used by EBB, in bar.
 SG_ EBDIAGACTIVE : 16|1@0+ (1,0) [0|0] "" UC_FREIN
 # Description: Indicates if EBB diagnosis is active.
 SG_ EBESPCOMPATIBILITYINDEX : 20|4@0+ (1,0) [0|15] "Sans unité" UC_FREIN
 # Description: Compatibility index between EBB and ESP system.
 SG_ EBB_BRAKE_PEDAL_STATE : 22|2@0+ (1,0) [0|0] "" UC_FREIN
 # Description: State of the brake pedal from EBB's perspective.
 SG_ CDA_REQUEST : 23|1@0+ (1,0) [0|0] "" UC_FREIN
 # Description: Request for Coasting/Deceleration Aid from EBB logic.
 SG_ CHECKSUM_FRAME_4B_322 : 27|4@0+ (1,0) [0|0] "" UC_FREIN
 # Description: 4-bit checksum for frame 322 data.
 SG_ PROCESS_COUNTER_4B_322 : 31|4@0+ (1,0) [0|15] "" UC_FREIN
 # Description: Process counter for frame 322 data.
 SG_ RESIDUAL_PRESSURE_STRATEGY : 39|3@0+ (1,0) [0|0] "" UC_FREIN
 # Description: Strategy controlling how residual pressure is handled in EBB.

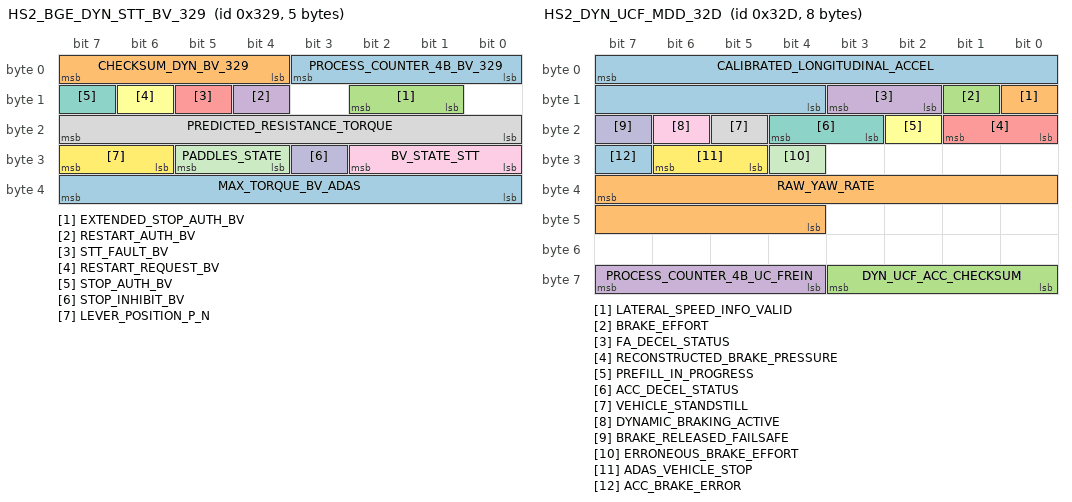
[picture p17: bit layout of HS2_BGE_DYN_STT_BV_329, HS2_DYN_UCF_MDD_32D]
BO_ 809 HS2_BGE_DYN_STT_BV_329: 5 BV
 SG_ PROCESS_COUNTER_4B_BV_329 : 3|4@0+ (1,0) [0|15] "" PASS_BSI
 # Description: Process counter for frame 329 data in the BV system.
 SG_ CHECKSUM_DYN_BV_329 : 7|4@0+ (1,0) [0|0] "" PASS_BSI
 # Description: 4-bit checksum for the BV 329 data frame.
 SG_ EXTENDED_STOP_AUTH_BV : 10|2@0+ (1,0) [0|0] "" PASS_BSI
 # Description: Authorization for extended engine stop from the BV system.
 SG_ RESTART_AUTH_BV : 12|1@0+ (1,0) [0|0] "" PASS_BSI
 # Description: Indicates if a restart is authorized by the BV system.
 SG_ STT_FAULT_BV : 13|1@0+ (1,0) [0|0] "" PASS_BSI
 # Description: Fault bit for the start-stop system recognized by the BV module.
 SG_ RESTART_REQUEST_BV : 14|1@0+ (1,0) [0|0] "" PASS_BSI
 # Description: Requests an engine restart from the BV system.
 SG_ STOP_AUTH_BV : 15|1@0+ (1,0) [0|0] "" PASS_BSI
 # Description: Authorization to stop the engine from the BV system.
 SG_ PREDICTED_RESISTANCE_TORQUE : 23|8@0+ (1,0) [0|200] "N.m" PASS_BSI
 # Description: Estimated resistance torque that might influence start-stop logic.
 SG_ BV_STATE_STT : 26|3@0+ (1,0) [0|0] "" PASS_BSI
 # Description: Current state of the BV start-stop system.
 SG_ STOP_INHIBIT_BV : 27|1@0+ (1,0) [0|0] "" PASS_BSI
 # Description: Inhibits engine stop if set.
 SG_ PADDLES_STATE : 29|2@0+ (1,0) [0|0] "" PASS_BSI
 # Description: State or position of shift paddles, if applicable.
 SG_ LEVER_POSITION_P_N : 31|2@0+ (1,0) [0|0] "" PASS_BSI
 # Description: Position of the gear lever between Park and Neutral.
 SG_ MAX_TORQUE_BV_ADAS : 39|8@0+ (2,-100) [-100|408] "N.m" PASS_BSI
 # Description: Maximum torque for BV in ADAS scenarios (e.g., ACC, AEBS).

BO_ 813 HS2_DYN_UCF_MDD_32D: 8 UC_FREIN
 SG_ CALIBRATED_LONGITUDINAL_ACCEL : 7|12@0+ (0.02,-40.96) [-40.96|40.92] "m/s2" CMM,BSI,PASS_HCU2,CMF,ARTIV
 # Description: Calibrated measurement of longitudinal acceleration for MDD logic.
 SG_ LATERAL_SPEED_INFO_VALID : 8|1@0+ (1,0) [0|1] "" CMM,BSI,PASS_HCU2,CMF,ARTIV
 # Description: Indicates if the lateral speed/yaw info is valid.
 SG_ BRAKE_EFFORT : 9|1@0+ (1,0) [0|1] "" CMM,BSI,PASS_HCU2,CMF,ARTIV
 # Description: Binary indication that brake effort is applied or recognized.
 SG_ FA_DECEL_STATUS : 11|2@0+ (1,0) [0|3] "" CMM,BSI,PASS_HCU2,CMF,ARTIV
 # Description: Status code for forward assist deceleration requests.
 SG_ RECONSTRUCTED_BRAKE_PRESSURE : 17|2@0+ (1,0) [0|3] "" CMM,BSI,PASS_HCU2,CMF,ARTIV
 # Description: Indicates that brake pressure has been reconstructed or estimated.
 SG_ PREFILL_IN_PROGRESS : 18|1@0+ (1,0) [0|1] "" CMM,BSI,PASS_HCU2,CMF,ARTIV
 # Description: Indicates an active prefill operation for the brake system.
 SG_ ACC_DECEL_STATUS : 20|2@0+ (1,0) [0|3] "" CMM,BSI,PASS_HCU2,CMF,ARTIV
 # Description: Status code for ACC deceleration requests.
 SG_ VEHICLE_STANDSTILL : 21|1@0+ (1,0) [0|1] "" CMM,BSI,PASS_HCU2,CMF,ARTIV
 # Description: Indicates that the vehicle is at a complete stop.
 SG_ DYNAMIC_BRAKING_ACTIVE : 22|1@0+ (1,0) [0|1] "" CMM,BSI,PASS_HCU2,CMF,ARTIV
 # Description: States whether dynamic braking intervention is active.
 SG_ BRAKE_RELEASED_FAILSAFE : 23|1@0+ (1,0) [0|1] "" CMM,BSI,PASS_HCU2,CMF,ARTIV
 # Description: Indicates the brake was released under failsafe conditions.
 SG_ ERRONEOUS_BRAKE_EFFORT : 28|1@0+ (1,0) [0|1] "" CMM,BSI,PASS_HCU2,CMF,ARTIV
 # Description: Flag indicating a detected error in brake effort measurement.
 SG_ ADAS_VEHICLE_STOP : 30|2@0+ (1,0) [0|3] "" CMM,BSI,PASS_HCU2,CMF,ARTIV
 # Description: ADAS-induced vehicle stop status code.
 SG_ ACC_BRAKE_ERROR : 31|1@0+ (1,0) [0|1] "" CMM,BSI,PASS_HCU2,CMF,ARTIV
 # Description: Indicates an error related to ACC braking demands.
 SG_ RAW_YAW_RATE : 39|12@0+ (0.08,-163.84) [-163.84|163.68] "Degré/s" CMM,BSI,PASS_HCU2,CMF,ARTIV
 # Description: Raw yaw rate measurement for stability or ADAS logic.
 SG_ DYN_UCF_ACC_CHECKSUM : 59|4@0+ (1,0) [0|7] "" CMM,BSI,PASS_HCU2,CMF,ARTIV
 # Description: 4-bit checksum for the UCF ACC data.
 SG_ PROCESS_COUNTER_4B_UC_FREIN : 63|4@0+ (1,0) [0|15] "" CMM,BSI,PASS_HCU2,CMF,ARTIV
 # Description: Process counter for the UC_FREIN frame.

BO_ 845 HS2_DYN_CDS_34D: 8 UC_FREIN
 SG_ TYPE_OF_ESP_TORQUE_CONTROL : 2|3@0+ (1,0) [0|7] "" ARTIV,ASR
 # Description: Specifies the type of torque control used by the ESP system.
 SG_ TCS_DISCONNECTED : 3|1@0+ (1,0) [0|1] "" ARTIV,ASR
 # Description: Indicates traction control system is disconnected or off.
 SG_ ESP_WARNING_LAMP_REQUEST : 4|1@0+ (1,0) [0|1] "" ARTIV,ASR
 # Description: Requests the ESP warning lamp to be illuminated.
 SG_ VDC_GEARBOX_REQUEST : 5|1@0+ (1,0) [0|1] "" ARTIV,ASR
 # Description: A request from VDC (vehicle dynamics control) regarding gearbox logic.
 SG_ ESP_REGULATION_ACTIVE : 6|1@0+ (1,0) [0|1] "" ARTIV,ASR
 # Description: Indicates that ESP regulation is currently active.
 SG_ ESP_DISCONNECTED : 7|1@0+ (1,0) [0|1] "" ARTIV,ASR
 # Description: Indicates if ESP is completely disconnected or disabled.
 SG_ AUTHORIZED_GEARSHIFT : 9|2@0+ (1,0) [0|3] "" ARTIV,ASR
 # Description: Indicates if a gear shift is authorized while ESP is active.
 SG_ PREFILL_ACTIVE : 10|1@0+ (1,0) [0|1] "" ARTIV,ASR
 # Description: Indicates the system is performing a brake prefill.
 SG_ DECELERATION_STATE_FA : 12|2@0+ (1,0) [0|3] "" ARTIV,ASR
 # Description: State of deceleration as recognized by a forward assist function.
 SG_ ASR_PLUS_STATE : 15|3@0+ (1,0) [0|7] "" ARTIV,ASR
 # Description: High-level state of the advanced ASR+ system.
 SG_ STATIC_ASR_TORQUE : 23|8@0+ (2,-100) [-100|400] "N.m" ARTIV,ASR
 # Description: Static portion of the ASR torque request.
 SG_ DYNAMIC_ASR_TORQUE : 31|8@0+ (2,-100) [-100|400] "N.m" ARTIV,ASR
 # Description: Dynamic portion of the ASR torque request.
 SG_ MSR_TORQUE : 39|8@0+ (2,-100) [-100|400] "N.m" ARTIV,ASR
 # Description: Torque request for MSR (engine drag torque control).
 SG_ PROCESS_COUNTER_4B_ESP : 43|4@0+ (1,0) [0|15] "" ARTIV,ASR
 # Description: Process counter for the ESP data frame.
 SG_ HILL_ASSIST_FUNCTION_STATUS : 46|2@0+ (1,0) [0|3] "" ARTIV,ASR
 # Description: Status of the hill assist function within ESP.
 SG_ BASR_REGULATION : 49|1@0+ (1,0) [0|1] "" ARTIV,ASR
 # Description: Indicates brake assist regulation activity (BASR).
 SG_ ASR_REGULATION : 50|1@0+ (1,0) [0|1] "" ARTIV,ASR
 # Description: Indicates traction control regulation activity (ASR).
 SG_ MSR_REGULATION : 51|1@0+ (1,0) [0|1] "" ARTIV,ASR
 # Description: Indicates engine drag torque regulation activity (MSR).
 SG_ ESP_ONLY_REGULATION : 52|1@0+ (1,0) [0|1] "" ARTIV,ASR
 # Description: Indicates that only ESP regulation is active.
 SG_ AFU_REGULATION : 53|1@0+ (1,0) [0|1] "" ARTIV,ASR
 # Description: Shows if emergency brake assist (AFU) is regulating.
 SG_ ASR_ESP_WARNING_LAMP_REQUEST : 55|1@0+ (1,0) [0|1] "" ARTIV,ASR
 # Description: Requests illumination of the traction/stability control lamp.
 SG_ STATIC_SLOPE : 61|6@0+ (1,-30) [-30|30] "%" ARTIV,ASR
 # Description: Indicates the slope percentage of the road, from -30% to +30%.

BO_ 905 HS2_BGE_DYN_BV_389: 5 BV
 SG_ VEHICLE_SPEED : 7|16@0+ (0.01,0) [0|655.34] "km/h" PASS_BSI
 # Description: Represents the current speed of the vehicle in kilometers per hour. Measured by the transmission unit.
 SG_ DISTANCE : 23|16@0+ (0.1,0) [0|6553.5] "m" PASS_BSI
 # Description: Accumulated distance measured by the gearbox or related sensor, in meters.
 SG_ LONGITUDINAL_ACCELERATION : 39|8@0+ (0.08,-14) [-14|6.32] "m/s2" PASS_BSI
 # Description: Measured or calculated longitudinal acceleration, in m/s².

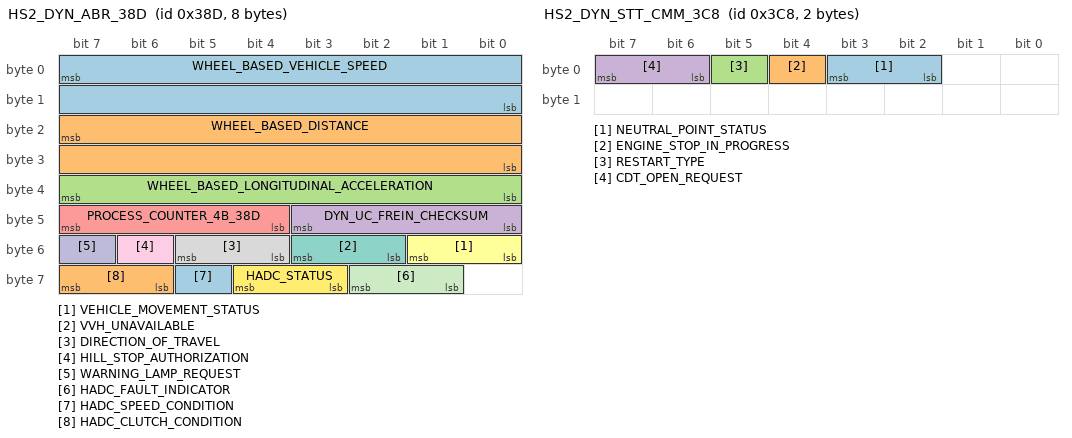
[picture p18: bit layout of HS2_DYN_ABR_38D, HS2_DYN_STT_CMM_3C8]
BO_ 909 HS2_DYN_ABR_38D: 8 UC_FREIN
 SG_ WHEEL_BASED_VEHICLE_SPEED : 7|16@0+ (0.01,0) [0|655.34] "km/h" CMF,CMM,BV,BSI,HCU1,ARTIV,BVN,AVAS
 # Description: Vehicle speed estimated from wheel rotations, in km/h.
 SG_ WHEEL_BASED_DISTANCE : 23|16@0+ (0.1,0) [0|6553.5] "m" CMF,CMM,BV,BSI,HCU1,ARTIV,BVN,AVAS
 # Description: Distance measured or accumulated from wheel-based sensors, in meters.
 SG_ WHEEL_BASED_LONGITUDINAL_ACCELERATION : 39|8@0+ (0.08,-14) [-14|6.32] "m/s2" CMF,CMM,BV,BSI,HCU1,ARTIV,BVN,AVAS
 # Description: Longitudinal acceleration derived from wheel-based signals.
 SG_ DYN_UC_FREIN_CHECKSUM : 43|4@0+ (1,0) [0|7] "" CMF,CMM,BV,BSI,HCU1,ARTIV,BVN,AVAS
 # Description: 4-bit checksum for the UC_FREIN dynamic data.
 SG_ PROCESS_COUNTER_4B_38D : 47|4@0+ (1,0) [0|15] "" CMF,CMM,BV,BSI,HCU1,ARTIV,BVN,AVAS
 # Description: Process counter for frame 38D data.
 SG_ VEHICLE_MOVEMENT_STATUS : 49|2@0+ (1,0) [0|3] "" CMF,CMM,BV,BSI,HCU1,ARTIV,BVN,AVAS
 # Description: Indicates if the vehicle is moving, stationary, or uncertain.
 SG_ VVH_UNAVAILABLE : 51|2@0+ (1,0) [0|3] "" CMF,CMM,BV,BSI,HCU1,ARTIV,BVN,AVAS
 # Description: Indicates if wheel-based speed/accel measurement is unavailable.
 SG_ DIRECTION_OF_TRAVEL : 53|2@0+ (1,0) [0|3] "" CMF,CMM,BV,BSI,HCU1,ARTIV,BVN,AVAS
 # Description: Vehicle travel direction (forward, reverse, unknown).
 SG_ HILL_STOP_AUTHORIZATION : 54|1@0+ (1,0) [0|1] "" CMF,CMM,BV,BSI,HCU1,ARTIV,BVN,AVAS
 # Description: Indicates if the system is allowed to hold the vehicle on a hill.
 SG_ WARNING_LAMP_REQUEST : 55|1@0+ (1,0) [0|1] "" CMF,CMM,BV,BSI,HCU1,ARTIV,BVN,AVAS
 # Description: Requests illumination of a general warning lamp.
 SG_ HADC_FAULT_INDICATOR : 58|2@0+ (1,0) [0|3] "" CMF,CMM,BV,BSI,HCU1,ARTIV,BVN,AVAS
 # Description: Fault indicator for the Hill Assist or Descent Control system.
 SG_ HADC_STATUS : 60|2@0+ (1,0) [0|3] "" CMF,CMM,BV,BSI,HCU1,ARTIV,BVN,AVAS
 # Description: Status code for the Hill Assist or Descent Control system.
 SG_ HADC_SPEED_CONDITION : 61|1@0+ (1,0) [0|1] "" CMF,CMM,BV,BSI,HCU1,ARTIV,BVN,AVAS
 # Description: Indicates if the vehicle meets speed conditions for HADC usage.
 SG_ HADC_CLUTCH_CONDITION : 63|2@0+ (1,0) [0|3] "" CMF,CMM,BV,BSI,HCU1,ARTIV,BVN,AVAS
 # Description: Indicates if the clutch condition is suitable for HADC operation.

BO_ 946 HS2_DYN_BSI_3B2: 2 BSI
 SG_ VEHICLE_PITCH_ANGLE : 7|10@0- (0.006,0) [-3|3] "Degré" BVN
 # Description: Measured or estimated pitch angle of the vehicle in degrees.

BO_ 952 HS2_BGE_DYN_CMM_3B8: 8 PASS_BSI
 SG_ EXT_RPM_COMPLEMENT : 7|16@0+ (1,0) [1|65535] "" BV
 # Description: Extended or complementary engine RPM value for dynamic calculations.
 SG_ EXT_REAL_TORQUE_COMPLEMENT : 23|8@0+ (1,0) [1|255] "" BV
 # Description: Extended or complementary torque value for dynamic calculations.
 SG_ DRIVER_DEMAND_COMPLEMENT : 31|8@0+ (1,0) [55|255] "" BV
 # Description: Complementary driver demand data for advanced calculations.
 SG_ COMPLEMENTARY_POTENTIAL_TORQUE_BEFORE_PROC : 39|8@0+ (1,0) [1|255] "" BV
 # Description: Potential torque complement measured before further processing.
 SG_ COMPLEMENTARY_CONDITIONED_TORQUE_BEFORE_PROC : 47|8@0+ (1,0) [1|255] "" BV
 # Description: Conditioned torque complement for more precise control.
 SG_ COASTING_STATE_OPTIPMI : 48|1@0+ (1,0) [0|1] "" BV
 # Description: Indicates if coasting is active based on OptiPMI logic.
 SG_ COASTING_STATE_DPT : 49|1@0+ (1,0) [0|1] "" BV
 # Description: Indicates if coasting is active based on DPT logic.
 SG_ COASTING_STATE_OPEN : 50|1@0+ (1,0) [0|1] "" BV
 # Description: Indicates an open coasting state with no torque coupling.
 SG_ COASTING_STATE : 51|8@0+ (1,0) [0|0] "" BV
 # Description: General coasting state indicator (reserved).
 SG_ COASTING_STATE_SAILING : 51|1@0+ (1,0) [0|1] "" BV
 # Description: Specific coasting/sailing mode indicator.
 SG_ PROCESS_COUNTER_4B_3B8 : 55|4@0+ (1,0) [0|15] "" BV
 # Description: Process counter for frame 3B8 data.
 SG_ CURRENT_POWERTRAIN_DYNAMIC_CAPABILITY : 59|2@0+ (1,0) [0|3] "" BV
 # Description: Indicates the powertrain dynamic capability (e.g., normal, reduced).
 SG_ COASTING_STATE_RES_7 : 60|1@0+ (1,0) [0|1] "" BV
 # Description: Reserved bit 7 for coasting state definition.
 SG_ COASTING_STATE_RES_6 : 61|1@0+ (1,0) [0|1] "" BV
 # Description: Reserved bit 6 for coasting state definition.
 SG_ COASTING_STATE_RES_5 : 62|1@0+ (1,0) [0|1] "" BV
 # Description: Reserved bit 5 for coasting state definition.
 SG_ COASTING_STATE_RES_4 : 63|1@0+ (1,0) [0|1] "" BV
 # Description: Reserved bit 4 for coasting state definition.

BO_ 968 HS2_DYN_STT_CMM_3C8: 2 CMM
 SG_ NEUTRAL_POINT_STATUS : 3|2@0+ (1,0) [0|3] "" RITCS,BV,UC_FREIN,BSI
 # Description: Indicates whether the gearbox is in neutral point or mid-shift.
 SG_ ENGINE_STOP_IN_PROGRESS : 4|1@0+ (1,0) [0|1] "" RITCS,BV,UC_FREIN,BSI
 # Description: Shows if an engine stop procedure is ongoing.
 SG_ RESTART_TYPE : 5|1@0+ (1,0) [0|1] "" RITCS,BV,UC_FREIN,BSI
 # Description: Type of engine restart (standard, forced, etc.).
 SG_ CDT_OPEN_REQUEST : 7|2@0+ (1,0) [0|3] "" RITCS,BV,UC_FREIN,BSI
 # Description: Request to open conduction path in the STT or CDT context.

BO_ 1001 HS2_DAT_BV_3E9: 2 BV
 SG_ DISPLAYED_ENGINE_SPEED_BV : 7|8@0+ (50,0) [0|8200] "tr/min" BSI
 # Description: Engine speed value displayed or used by the gearbox for user feedback.

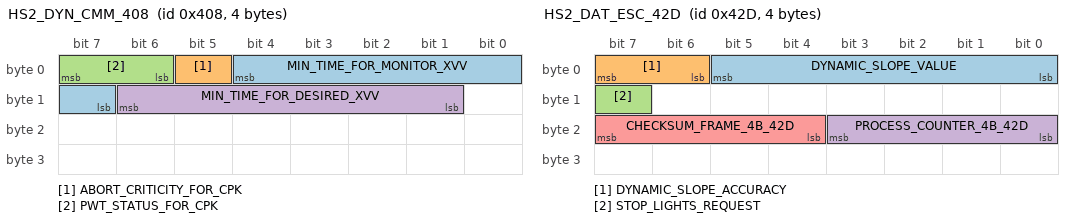
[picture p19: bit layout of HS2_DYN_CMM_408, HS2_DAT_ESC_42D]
BO_ 1032 HS2_DYN_CMM_408: 4 CMM
 SG_ MIN_TIME_FOR_MONITOR_XVV : 4|6@0+ (0.1,0) [0|6.2] "s" BV,UC_FREIN
 # Description: Minimum confirmation time for monitoring the XVV function.
 SG_ ABORT_CRITICITY_FOR_CPK : 5|1@0+ (1,0) [0|1] "" BV,UC_FREIN
 # Description: Indicates if a critical condition triggers CPK function abort.
 SG_ PWT_STATUS_FOR_CPK : 7|2@0+ (1,0) [0|3] "" BV,UC_FREIN
 # Description: Powertrain status relevant to the CPK logic.
 SG_ MIN_TIME_FOR_DESIRED_XVV : 14|6@0+ (0.1,0) [0|6.2] "s" BV,UC_FREIN
 # Description: Minimum confirmation time for achieving the desired XVV condition.

BO_ 1069 HS2_DAT_ESC_42D: 4 UC_FREIN
 SG_ DYNAMIC_SLOPE_VALUE : 5|6@0+ (1,-30) [-30|30] "%" CMF,ARTIV,AAS,PASS_HCU2,CMM,BV,BSI
 # Description: Current slope or gradient measurement used by ESC logic.
 SG_ DYNAMIC_SLOPE_ACCURACY : 7|2@0+ (1,0) [0|3] "" CMF,ARTIV,AAS,PASS_HCU2,CMM,BV,BSI
 # Description: Accuracy level of the slope measurement.
 SG_ STOP_LIGHTS_REQUEST : 15|1@0+ (1,0) [0|1] "" CMF,ARTIV,AAS,PASS_HCU2,CMM,BV,BSI
 # Description: Requests the stop lights to activate (e.g., if deceleration is high).
 SG_ PROCESS_COUNTER_4B_42D : 19|4@0+ (1,0) [0|15] "" CMF,ARTIV,AAS,PASS_HCU2,CMM,BV,BSI
 # Description: Process counter for frame 42D data.
 SG_ CHECKSUM_FRAME_4B_42D : 23|4@0+ (1,0) [0|7] "" CMF,ARTIV,AAS,PASS_HCU2,CMM,BV,BSI
 # Description: 4-bit checksum for frame 42D data.

BO_ 1070 HS2_DAT_BSI_42E: 4 BSI
 SG_ ESP_MODE_REQUEST : 7|3@0+ (1,0) [0|1] "" UC_FREIN
 # Description: Request to set or change the mode of the ESP system.

BO_TX_BU_ 694 : ARTIV,CMF;
BO_TX_BU_ 758 : ARTIV,CMF;
CM_ "EDC17 CAN data base for DT20C C10
-Sharath Tengse (RBIN/EDR2)";
CM_ BU_ UTIL__Traminator "Control of Traminator by CAN2 of CANalyzer";
CM_ BU_ AR2S_StartStop "This node is for start stop function. For DV4E4";
CM_ BO_ 3221225472 "This is a message for not used signals, created by Vector CANdb++ DBC OLE DB Provider.";
CM_ SG_ 3221225472 P252_ImpluseStart "Momentary starting request";
CM_ SG_ 3221225472 P250_MajorStartRequest "Main latch starting request";
CM_ SG_ 3221225472 P248_StarterStopReq "starter stop request";
CM_ SG_ 3221225472 P107_Com_stAddPmpLvl "P107 Minimum of FAP additive exeeded";
CM_ SG_ 3221225472 P101_Com_mAddPmpTot "P101: absolute Menge des eingespritztem Additivs (Cerium)";
CM_ SG_ 3221225472 P087_Com_stClth "Clutch signal for AM6";
CM_ SG_ 3221225472 P227_Pwr_Gen_Support_state "P165: Water in fuel indication (1 = water in fueel detected / 0 = no water in fuel)";
CM_ SG_ 3221225472 P084_CoDT_trqGearbxDes "P084  Vorweggenommenes Drehmoment";
CM_ SG_ 3221225472 P004_ActualTorqueNoGearbox "P004  Actual torque before torque intervention by automatic gearbox";
CM_ SG_ 3221225472 P251_Com_stScndStrtReq "Secondary latched starting request";
CM_ SG_ 3221225472 P093_Temp_aval_FAP "P093  FAP-Temperatur";
CM_ SG_ 3221225472 P041_Cde_RVV "P041  FGR-Bedienteilinfo";
CM_ SG_ 3221225472 P069_Act_RVV "P069  FGR-Hauptschalter";
CM_ SG_ 3221225472 P033_sABS "P033 odometer";
CM_ SG_ 3221225472 P284_T15CD_stPart_byte8 "ECU electronic state";
CM_ SG_ 3221225472 Reserved_1 "P074  Number of BusOff in driving cycle";
CM_ SG_ 3221225472 P243_FrmMng_stFlCnsmp_mp "P155: Preparation of glow activation.";
CM_ SG_ 3221225472 P051_ACCD_stPres "P051  Abschaltung Klimakompressor wegen Ueber- oder
Unterdruck im Kaeltemittelkreislauf";
CM_ SG_ 3221225472 P053_ACCtl_stHys "P053  Abschaltung Klimakompressor aus Sicherheitsgruenden
oder wegen Komfortfunktionen";
CM_ SG_ 3221225472 P049_Com_bMIL "P049  Ansteuerung DIA-Lampe";
CM_ SG_ 3221225472 P028_Gbx_stEOBDFault "P028  MIL request gearbox";
CM_ SG_ 3221225472 P284_T15CD_stPart_byte6 "ECU electronic state";
CM_ BO_ 2024 "Le mécanisme d'émission utilisé est événementiel du CMM vers l'outil branché sur le réseau Can

Trame réponse EOBD On Can du CMM";
CM_ BO_ 2016 "Le mécanisme d'émission utilisé est événementiel de l'outil branché sur le réseau Can vers le CMM

Trame question EOBD On Can adresse au CMM";
CM_ BO_ 2015 "Le mécanisme d'émission utilisé est événementiel de l'outil branché sur le réseau Can vers les calculateurs.

Trame question EOBD On Can adresse a tous les calculateurs";
CM_ BO_ 1704 "Le mécanisme d'émission utilisé est événementiel de l'outil vers le calculateur via la BSI
Trame question pour le téléchargement et le Diag On CAN.";
CM_ BO_ 1458 "trame utilisable uniquement sur véhicules en archi EE 2010";
CM_ SG_ 1458 P__Com_stEOBD "Pxxx: EOBD relevant errors in the network";
CM_ SG_ 1458 P100_Com_stAddPmpDef "P100: Status of additive for FAP";
CM_ SG_ 1458 P146_Com_tEnvT "P146: Environment air temperature";
CM_ BO_ 1101 "ID 44D: Rear unfiltered wheel speeds, used for EasyMove";
CM_ SG_ 1101 P331_VehV_vWhlRrR "P010  vehicle speed of ABS. This signal is loaded into VSSCD_v";
CM_ SG_ 1101 P330_VehV_vWhlRrL "P010  vehicle speed of ABS. This signal is loaded into VSSCD_v";
CM_ BO_ 1928 "ID 788:  CMM Supervision Frame (Period time 1000 ms)";
CM_ SG_ 1928 P284_T15CD_stPart "ECU electronic state";
CM_ SG_ 1928 P242_T15CD_stElec "ECU electronic state";
CM_ SG_ 1928 P071_ConfirmedAbsentFlags "P071  confirmed absent status flags of the ECU";
CM_ SG_ 1928 P073_SupervisionFaultCodes "P073  Supervision fault codes";
CM_ BO_ 1224 "ID 4C8: Crash status by Airbag Control (Event triggered / Period time 50 ms)";
CM_ SG_ 1224 P223_CrashInfo "Crash Information";
CM_ SG_ 1128 P244_Com_bSta "Starter state";
CM_ SG_ 1128 P245_Com_stRedBrkPlaus "Uncertain redendant brake contact";
CM_ SG_ 1128 P246_Com_bStaPrt "Starter protection";
CM_ SG_ 1128 P247_Com_stStaFunc "CMM DAMP function state";
CM_ 1074 P253_Com_bEngPrepReq "Engine preparation request";
CM_ 1074 P214_Com_stMnWkUp "Main wake-up (RCD )";
CM_ 1074 P216_Com_bSiaWkUp "Immobilizer anticipation with wake up";
CM_ 1074 P249_Com_stEngStopReq "Engine stop request";
CM_ BO_ 1042 "ID 412: Body Car Data Frame (Period time 50 ms)";
CM_ SG_ 1042 P104_Dspl_stAOHt "P104  Ansteuerung Zusatzheizer";
CM_ SG_ 1042 P086_Com_stFlLvlDia "P086 Minimum fuel level diagnosis status. (00 Minimum fuel is valid / 01 Minimum fuel is not valid / others are not defined)";
CM_ SG_ 1042 P012_Com_bFlMin "P012 Minimum fuel level detected. If fuel level < 15 % signal P012 will be set to one.";
CM_ SG_ 1042 P013_MainBrake "P013 main brake signal";
CM_ SG_ 1042 P103_Com_bRevGear "P013 main brake signal";
CM_ SG_ 1042 P040_MainBrakeFault "P040  Main brake switch is defect.";
CM_ BO_ 969 "Pour application MCP SSTG";
CM_ BO_ 909 "ID 38D: ABS Vehicle Dynamic Frame (Period time 40 ms)";
CM_ SG_ 909 P052_Com_aLng "P052 longitudinal acceleration (FrmMng_a)";
CM_ SG_ 909 P010_Com_v "P010  vehicle speed of ABS. This signal is loaded into VSSCD_v";
CM_ BO_ 904 "ID 388: Engine Dynamic Frame 3 (Period time 40ms)";
CM_ SG_ 904 P066_aECU "P066 longitudinal acceleration by engine ECU";
CM_ SG_ 904 P062_sECU "P062 odometer by engine ECU";
CM_ SG_ 904 P060_vECU "P060 velocity by engine ECU";
CM_ BO_ 845 "ID 34D: ESP Synchronisation frame (Period time 20 ms)";
CM_ SG_ 845 P157_Com_ctESP "P157 Check counter";
CM_ SG_ 845 P045_Com_trqDCSRaw "P045 DCS (MSR) torque request = min. threshold";
CM_ SG_ 845 P044_Com_trqTCSRaw "P044 TCS (ASR) dynamic torque request";
CM_ SG_ 845 P043_Com_xTCSStatRaw "P043 TCS (ASR) static torque request = max. threshold";
CM_ SG_ 845 P147_Com_bESPIntvActv "P147 ESP-TCS (ASR) in regulation";
CM_ SG_ 845 P088_CutOffForbidden "P088 Cut off of injection is forbidden.";
CM_ SG_ 845 P047_Com_stESPIntv "P047 ESP torque request status";
CM_ BO_ 841 "ID 349: Gearbox Synchronisation Frame (Period time 20 ms)";
CM_ SG_ 841 P340_Com_xTSCChkSum "P097  request to increase the idle speed";
CM_ SG_ 841 P287_Com_stGearRat "P008  transmission range engaged";
CM_ SG_ 841 P283_Com_stGearTrgtPos "P087 gearbox converter state";
CM_ SG_ 841 P166_Com_nEngTSC "P055 torque limitation for gearbox";
CM_ SG_ 841 P230_Com_ctTSCCntr "P048  fan request for gearbox";
CM_ SG_ 841 P167_Com_stEngSpdCtl "P009  shift in progress";
CM_ SG_ 841 P085_Com_bGbxACCmprShOff "P085  AC compressor inhibit";
CM_ SG_ 841 P009_Com_bGearShftActv "P057  Gearbox torque request";
CM_ BO_ 840 "ID 348:  Engine Dynamic Frame 2 (Period time 20 ms)";
CM_ SG_ 840 P091_ConvCD_stDebVal "P091 clutch pedal switch and status";
CM_ SG_ 840 P134_Com_stEng "Engine status";
CM_ SG_ 840 P212_Comp_load_shed "Compressor load shedding command";
CM_ SG_ 840 P025_Com_stESPErr "P025 TCS/DCS (ASR/MSR) request state";
CM_ SG_ 840 P026_Com_bESPAck "P026 TCS/DCS (ASR/MSR) acknowledgement by engine ECU
(1 = communication correct)";
CM_ SG_ 840 P017_Com_trqFrc "P017 Torque lost by AC, friction, high pressure pump and accessories.";
CM_ SG_ 840 P211_AirC_pClnt "P084  Vorweggenommenes Drehmoment";
CM_ SG_ 840 P019_Com_trqPrp "P019 Requested torque before processing.";
CM_ SG_ 840 P152_Gearbx_stGear "P152: Gear detected by ratio vehicule speed to engine speed";
CM_ SG_ 840 P165_FlFCD_stWtLvlSensDebVal "P165: Water in fuel indication (1 = water in fuel detected / 0 = no water in fuel)";
CM_ BO_ 520 "ID 208:  Engine Dynamic Frame (Period time 10 ms)";
CM_ SG_ 520 P027_ACCtl_stLogicOut "P027  Klimakompressor Status ein/aus";
CM_ SG_ 520 P198_ActMod_trqClthTraIntv "P084  Vorweggenommenes Drehmoment";
CM_ SG_ 520 P127_EGT_st_Bit30 "P127: Regeneration aid by electric consumers (engine load increase).";
CM_ SG_ 520 P042_Inm_bCanMon "P042  CAN-Fehlerbehandlung im Startfall mit Hilfe der
          Startendekennung unterdrücken";
CM_ SG_ 520 P153_Com_bTrqInacc "P153: Indicates to the torque consumers that the accuracy of the
torque data output is not guaranteed by the CMM.";
CM_ SG_ 520 P037_VehV_stXVV "P037  Zustand des FGR (Ein/Aus,Ueberdruecken)";
CM_ SG_ 520 P014_Brk_stRed "P014  Redundanter Bremskontakt";
CM_ SG_ 520 P002_Com_rAPP "P002  rueckgerechnete PWG-Stellung";
CM_ SG_ 520 P003_Com_trqActOut "P003  Actual torque ";
CM_ SG_ 520 P000_Com_nEng "P000  Motordrehzahl";
CM_ BO_ 264 "ID 108:  ECM Version Frame - Vers_CMM (Period: Single shot)

Le contenu de la trame est une recopie d'un sous-ensemble de la zone d'identification de la Flash Eprom définie dans le document Application flash EPROM 2000 ref. 96.285.582.9.

";
CM_ SG_ 264 P083_Calibration "P083  Calibration issue";
CM_ SG_ 264 P082_Edition "P082  Software issue";
CM_ SG_ 264 P081_Version "P081  Software version";
CM_ SG_ 264 P080_Application "P080  supplier application";
CM_ SG_ 264 P079_Year "P079  Date: year of the version";
CM_ SG_ 264 P078_Month "P078  Date: month of the version";
CM_ SG_ 264 P077_Day "P077  Date: day of the version";
CM_ SG_ 264 P076_System "P076  system version";
CM_ BO_ 168 "ID A8: Unlock Permission Frame Code (Period time 10 ms)";
CM_ SG_ 168 ADC2_Key_Byte0 "KEY4 of CFD_BSI (lowest byte)";
CM_ SG_ 168 ADC2_Key_Byte1 "KEY3 of CFD_BSI (low byte)";
CM_ SG_ 168 ADC2_Key_Byte2 "KEY2 of CFD_BSI (high byte)";
CM_ SG_ 168 ADC2_Key_Byte3 "KEY1 of CFD_BSI (highest byte)";
CM_ SG_ 168 ADC2_Key_Status "Unlock permission";
CM_ BO_ 114 "ID 072: Unlock Request Frame or LockingStatus (Event triggered)";
CM_ SG_ 114 ADC2_Seed_Byte0 "SEED4 of RQD_CMM (lowest byte)";
CM_ SG_ 114 ADC2_Seed_Byte1 "SEED3 of RQD_CMM (low byte)";
CM_ SG_ 114 ADC2_Seed_Byte2 "SEED2 of RQD_CMM (high byte)";
CM_ SG_ 114 ADC2_Seed_Byte3 "SEED1 of RQD_CMM (highest byte)";
CM_ SG_ 114 ADC2_Req_Status "Unlock request";
; #############################################################################
; ############################### HS2 CM ######################################
; #############################################################################
CM_ BO_ 238 "The content definition depends on the type of Electronic Control Unit (ECU):
- Downloadable (software and calibration) in Flash Eeprom: the content of the frame is a copy of a subset of the identification area of the Flash Eeprom defined in the document 'Application Flash EPROM 2000 ref. 96.285.582.99'.
- Downloadable (calibration) in Eeprom: the content of the frame is a copy of a subset of the identification area of the Eeprom defined in the document 'Calibration Download for ECUs without Flash Eeprom ref. 96.401.797.9A'.
- Non-downloadable: the content of the frame is a copy of a subset of the electronic label defined in the document 'Keyword Protocol 2000 - 3F ref. 96.253.521.99'.";

CM_ SG_ 238 SYSTEM_VERSION "Identifies the ECU type. This number is defined in the identification area of the flash Eeprom and in the system version frame.";
CM_ SG_ 238 VERSION_DATE2_DAY "If there is no day for the version, this data must be set to 0xFF. Indicates the day component of the second version date.";
CM_ SG_ 238 VERSION_DATE2_MONTH "If there is no month for the version, this data must be set to 0xFF. Indicates the month component of the second version date.";
CM_ SG_ 238 VERSION_DATE2_YEAR "Software version date coded on 1 byte: from 00 to 99. If there is no year for the version, this data must be set to 0xFF.";
CM_ SG_ 238 APPLICATION_VERSION "Defines a type of application corresponding to a different hardware version for the given system. If there is no supplier application, this data must be set to 0xFF. This data is set by the supplier.";
CM_ SG_ 238 SOFTWARE_VERSION "Characterizes the version of the software.";
CM_ SG_ 238 SOFTWARE_EDITION "Characterizes the evolution of the software version.";
CM_ SG_ 238 CALIBRATION_EDITION "Characterizes the calibration evolutions. If there is no calibration index, this data must be set to zero.";

CM_ BO_ 239 "The content definition depends on the type of Electronic Control Unit (ECU):
- Downloadable (software and calibration) in Flash Eeprom: the content of the frame is a copy of a subset of the identification area of the Flash Eeprom defined in the document 'Application Flash EPROM 2000 ref. 96.285.582.99'.
- Downloadable (calibration) in Eeprom: the content of the frame is a copy of a subset of the identification area of the Eeprom defined in the document 'Calibration Download for ECUs without Flash Eeprom ref. 96.401.797.9A'.
- Non-downloadable: the content of the frame is a copy of a subset of the electronic label defined in the document 'Keyword Protocol 2000 - 3F ref. 96.253.521.99'.";

CM_ SG_ 239 SYSTEM_VERSION "Identifies the ECU type. This number is defined in the identification area of the flash Eeprom and in the system version frame.";
CM_ SG_ 239 VERSION_DATE2_DAY "If there is no day for the version, this data must be set to 0xFF. Indicates the day component of the second version date.";
CM_ SG_ 239 VERSION_DATE2_MONTH "If there is no month for the version, this data must be set to 0xFF. Indicates the month component of the second version date.";
CM_ SG_ 239 VERSION_DATE2_YEAR "Software version date coded on 1 byte: from 00 to 99. If there is no year for the version, this data must be set to 0xFF.";
CM_ SG_ 239 APPLICATION_VERSION "Defines a type of application corresponding to a different hardware version for the given system. If there is no supplier application, this data must be set to 0xFF. This data is set by the supplier.";
CM_ SG_ 239 SOFTWARE_VERSION "Characterizes the version of the software.";
CM_ SG_ 239 SOFTWARE_EDITION "Characterizes the evolution of the software version.";
CM_ SG_ 239 CALIBRATION_EDITION "Characterizes the calibration evolutions. If there is no calibration index, this data must be set to zero.";

CM_ BO_ 274 "The content definition depends on the type of Electronic Control Unit (ECU):
- Downloadable (software and calibration) in Flash Eeprom: the content of the frame is a copy of a subset of the identification area of the Flash Eeprom defined in the document 'Application Flash EPROM 2000 ref. 96.285.582.99'.
- Downloadable (calibration) in Eeprom: the content of the frame is a copy of a subset of the identification area of the Eeprom defined in the document 'Calibration Download for ECUs without Flash Eeprom ref. 96.401.797.9A'.
- Non-downloadable: the content of the frame is a copy of a subset of the electronic label defined in the document 'Keyword Protocol 2000 - 3F ref. 96.253.521.99'.";

CM_ SG_ 274 SYSTEM_VERSION "Identifies the ECU type. This number is defined in the identification area of the flash Eeprom and in the system version frame.";
CM_ SG_ 274 VERSION_DATE2_DAY "If there is no day for the version, this data must be set to 0xFF. Indicates the day component of the second version date.";
CM_ SG_ 274 VERSION_DATE2_MONTH "If there is no month for the version, this data must be set to 0xFF. Indicates the month component of the second version date.";
CM_ SG_ 274 VERSION_DATE2_YEAR "Software version date coded on 1 byte: from 00 to 99. If there is no year for the version, this data must be set to 0xFF.";
CM_ SG_ 274 APPLICATION_VERSION "Defines a type of application corresponding to a different hardware version for the given system. If there is no supplier application, this data must be set to 0xFF. This data is set by the supplier.";
CM_ SG_ 274 SOFTWARE_VERSION "Characterizes the version of the software.";
CM_ SG_ 274 SOFTWARE_EDITION "Characterizes the evolution of the software version.";
CM_ SG_ 274 CALIBRATION_EDITION "Characterizes the calibration evolutions. If there is no calibration index, this data must be set to zero.";

CM_ BO_ 278 "The content definition depends on the type of Electronic Control Unit (ECU):
- Downloadable (software and calibration) in Flash Eeprom: the content of the frame is a copy of a subset of the identification area of the Flash Eeprom defined in the document 'Application Flash EPROM 2000 ref. 96.285.582.99'.
- Downloadable (calibration) in Eeprom: the content of the frame is a copy of a subset of the identification area of the Eeprom defined in the document 'Calibration Download for ECUs without Flash Eeprom ref. 96.401.797.9A'.
- Non-downloadable: the content of the frame is a copy of a subset of the electronic label defined in the document 'Keyword Protocol 2000 - 3F ref. 96.253.521.99'.";

CM_ SG_ 278 SYSTEM_VERSION "Identifies the ECU type. This number is defined in the identification area of the flash Eeprom and in the system version frame.";
CM_ SG_ 278 VERSION_DATE2_DAY "If there is no day for the version, this data must be set to 0xFF. Indicates the day component of the second version date.";
CM_ SG_ 278 VERSION_DATE2_MONTH "If there is no month for the version, this data must be set to 0xFF. Indicates the month component of the second version date.";
CM_ SG_ 278 VERSION_DATE2_YEAR "Software version date coded on 1 byte: from 00 to 99. If there is no year for the version, this data must be set to 0xFF.";
CM_ SG_ 278 APPLICATION_VERSION "Defines a type of application corresponding to a different hardware version for the given system. If there is no supplier application, this data must be set to 0xFF. This data is set by the supplier.";
CM_ SG_ 278 SOFTWARE_VERSION "Characterizes the version of the software.";
CM_ SG_ 278 SOFTWARE_EDITION "Characterizes the evolution of the software version.";
CM_ SG_ 278 CALIBRATION_EDITION "Characterizes the calibration evolutions. If there is no calibration index, this data must be set to zero.";

CM_ SG_ 285 SYSTEM_VERSION "Identifies the ECU type. This number is defined in the identification area of the flash Eeprom and in the system version frame.";
CM_ SG_ 285 VERSION_DATE2_DAY "If there is no day for the version, this data must be set to 0xFF. Indicates the day component of the second version date.";
CM_ SG_ 285 VERSION_DATE2_MONTH "If there is no month for the version, this data must be set to 0xFF. Indicates the month component of the second version date.";
CM_ SG_ 285 VERSION_DATE2_YEAR "Software version date coded on 1 byte: from 00 to 99. If there is no year for the version, this data must be set to 0xFF.";
CM_ SG_ 285 APPLICATION_VERSION "Defines a type of application corresponding to a different hardware version for the given system. If there is no supplier application, this data must be set to 0xFF. This data is set by the supplier.";
CM_ SG_ 285 SOFTWARE_VERSION "Characterizes the version of the software.";
CM_ SG_ 285 SOFTWARE_EDITION "Characterizes the evolution of the software version.";
CM_ SG_ 285 CALIBRATION_EDITION "Characterizes the calibration evolutions. If there is no calibration index, this data must be set to zero.";

CM_ BO_ 300 "The content definition depends on the type of Electronic Control Unit (ECU):
- Downloadable (software and calibration) in Flash Eeprom: the content of the frame is a copy of a subset of the identification area of the Flash Eeprom defined in the document 'Application Flash EPROM 2000 ref. 96.285.582.99'.
- Downloadable (calibration) in Eeprom: the content of the frame is a copy of a subset of the identification area of the Eeprom defined in the document 'Calibration Download for ECUs without Flash Eeprom ref. 96.401.797.9A'.
- Non-downloadable: the content of the frame is a copy of a subset of the electronic label defined in the document 'Keyword Protocol 2000 - 3F ref. 96.253.521.99'.";

CM_ SG_ 300 SYSTEM_VERSION "Identifies the ECU type. This number is defined in the identification area of the flash Eeprom and in the system version frame.";
CM_ SG_ 300 VERSION_DATE2_DAY "If there is no day for the version, this data must be set to 0xFF. Indicates the day component of the second version date.";
CM_ SG_ 300 VERSION_DATE2_MONTH "If there is no month for the version, this data must be set to 0xFF. Indicates the month component of the second version date.";
CM_ SG_ 300 VERSION_DATE2_YEAR "Software version date coded on 1 byte: from 00 to 99. If there is no year for the version, this data must be set to 0xFF.";
CM_ SG_ 300 APPLICATION_VERSION "Defines a type of application corresponding to a different hardware version for the given system. If there is no supplier application, this data must be set to 0xFF. This data is set by the supplier.";
CM_ SG_ 300 SOFTWARE_VERSION "Characterizes the version of the software.";
CM_ SG_ 300 SOFTWARE_EDITION "Characterizes the evolution of the software version.";
CM_ SG_ 300 CALIBRATION_EDITION "Characterizes the calibration evolutions. If there is no calibration index, this data must be set to zero.";

CM_ SG_ 525 CHECKSUM_FRAME_4B_20D "CHK_INI = 0xD";

CM_ BO_ 552 "Emitted for the Easy Move function";

CM_ SG_ 557 CHECKSUM_FRAME_4B_22D "CHK_INI = 0x3";

CM_ SG_ 642 CHECKSUM_FRAME_4B_282 "CHK_INI = 0xD";

CM_ SG_ 664 CHECKSUM_FRAME_4B_298 "CHK_INI = 0x3";

CM_ SG_ 690 STATE_RVV_LVV "State of the RVV2 or LVV function.";
CM_ SG_ 690 STATE_THERMAL_ENGINE "Operating state of the internal combustion engine.";

CM_ SG_ 694 STATE_ACC "Indicates the operating state of the Adaptive Cruise Control (ACC) system.";
CM_ SG_ 694 CHECKSUM_DYNAMIC_ACC_FRAME "CHK_INI = 0x3";
CM_ SG_ 694 PROCESS_COUNTER_4B_ACC "This counter increments from 0 to 15 at each activation of the calculation process.";

CM_ SG_ 744 WHEEL_TORQUE_REQUEST_ABS "Represents requested wheel torque (Cns_cple_MSR = N * 20 - 1000).";
CM_ SG_ 744 ACCELERATOR_POSITION_REQUEST "Represents the incoming flow to the IVC (inlet valve control) for torque request calculations.";

CM_ SG_ 758 CHECKSUM_DYNAMIC_ACC2_FRAME "CHK_INI = 0x7";
CM_ SG_ 758 PROCESS_COUNTER_4B_ACC2 "This counter increments from 0 to 15 at each activation of the calculation process.";

CM_ SG_ 802 CHECKSUM_FRAME_4B_322 "CHK_INI = 0xD";

CM_ SG_ 809 CHECKSUM_DYNAMIC_GEARBOX_329_FRAME "For the 0x349 v2 frame, CHK_INI = 0x9. (For the 0x349 v1 frame, CHK_INI = 0xF.) For the 0x329 frame, CHK_INI = 0x2. For the 0x3C9 frame, CHK_INI = 0x1.";
CM_ SG_ 809 PREDICTED_RESISTIVE_TORQUE "Predicted resistive torque = N * 1";

CM_ SG_ 813 CHECKSUM_DYNAMIC_UCF_ACC_FRAME "CHK_INI = 0x2";
CM_ SG_ 813 PROCESS_COUNTER_4B_UC_BRAKE "This counter increments from 0 to 15 at each activation of the calculation process.";

CM_ SG_ 845 PROCESS_COUNTER_4B_ESP "This counter increments from 0 to 15 at each activation of the calculation process.";

CM_ SG_ 909 WHEEL_DISTANCE "Distance measured by the wheel sensors.";
CM_ SG_ 909 LONGITUDINAL_ACCELERATION_WHEEL "Longitudinal acceleration measured by the wheel sensors.";
CM_ SG_ 909 CHECKSUM_DYNAMIC_UC_BRAKE_FRAME "CHK_INI = 0x8";

CM_ SG_ 952 COMPLEMENT1_ENGINE_SPEED "Two's complement representation of the engine speed for SDF needs.";
CM_ SG_ 952 COMPLEMENT1_ACTUAL_TORQUE "Two's complement representation of the actual torque (COUPLE_REEL) for SDF needs.";
CM_ SG_ 952 COMPLEMENT1_DRIVER_REQUEST "Two's complement representation of the driver request (VOLONTE_COND) for SDF needs.";
CM_ SG_ 952 COMPLEMENT1_POTENTIAL_TORQUE_AFTER_TREATMENT "Two's complement representation of the potential torque requested by the driver after treatment (CPLE_POT_APR_TRT) for SDF needs.";
CM_ SG_ 952 COMPLEMENT1_TORQUE_DRIVER_AFTER_TREATMENT "Two's complement representation of the torque requested by the driver after treatment (CPLE_COND_APR_TRT) for SDF needs.";

CM_ SG_ 1069 CHECKSUM_FRAME_4B_42D "CHK_INI = 0x6";
CM_ BO_ 3221225472 "This is a message for unused signals, created by Vector CANdb++ DBC OLE DB Provider.";
; #############################################################################
; ############################### HS1 BA ######################################
; #############################################################################
BA_DEF_ BO_  "???" HEX 0 0;
BA_DEF_DEF_  "???" 0;
; #############################################################################
; ############################### HS2 BA ######################################
; #############################################################################
BA_DEF_ BO_  "ModeTransmission" ENUM  "P","E","P+E";
BA_DEF_ BO_  "Période" INT 0 0;
BA_DEF_DEF_  "ModeTransmission" "P";
BA_DEF_DEF_  "Période" 100;
BA_ "Période" BO_ 238 0;
BA_ "ModeTransmission" BO_ 238 1;
BA_ "Période" BO_ 239 0;
BA_ "ModeTransmission" BO_ 239 1;
BA_ "Période" BO_ 274 0;
BA_ "ModeTransmission" BO_ 274 1;
BA_ "Période" BO_ 278 0;
BA_ "ModeTransmission" BO_ 278 1;
BA_ "Période" BO_ 285 0;
BA_ "ModeTransmission" BO_ 285 1;
BA_ "Période" BO_ 300 0;
BA_ "ModeTransmission" BO_ 300 1;
BA_ "Période" BO_ 525 10;
BA_ "Période" BO_ 551 10;
BA_ "Période" BO_ 552 10;
BA_ "Période" BO_ 557 20;
BA_ "Période" BO_ 584 10;
BA_ "Période" BO_ 632 10;
BA_ "Période" BO_ 642 10;
BA_ "Période" BO_ 653 10;
BA_ "Période" BO_ 664 20;
BA_ "Période" BO_ 690 20;
BA_ "Période" BO_ 694 20;
BA_ "Période" BO_ 696 20;
BA_ "Période" BO_ 717 20;
BA_ "Période" BO_ 728 20;
BA_ "Période" BO_ 744 20;
BA_ "Période" BO_ 758 20;
BA_ "Période" BO_ 760 20;
BA_ "Période" BO_ 761 10;
BA_ "Période" BO_ 792 20;
BA_ "Période" BO_ 802 20;
BA_ "Période" BO_ 809 20;
BA_ "Période" BO_ 813 20;
BA_ "Période" BO_ 845 20;
BA_ "Période" BO_ 905 40;
BA_ "Période" BO_ 909 40;
BA_ "Période" BO_ 946 40;
BA_ "Période" BO_ 952 40;
BA_ "Période" BO_ 968 20;
BA_ "Période" BO_ 1001 50;
BA_ "Période" BO_ 1032 40;
BA_ "Période" BO_ 1069 50;
BA_DEF_ BO_  "GenMsgStartDelayTime" INT 0 65535;
BA_DEF_ BO_  "GenMsgMinAcceptLength" INT -1 8;
BA_DEF_ BO_  "DiagState" ENUM  "No","Yes";
BA_DEF_ BO_  "GenMsgDelayTime" INT 0 65535;
BA_DEF_ SG_  "GenSigSendType" ENUM  "Cyclic","OnWrite","OnWriteWithRepetition","OnChange","OnChangeWithRepetition","IfActive","IfActiveWithRepetition","NoSigSendType","OnChangeAndIfActive","OnChangeAndIfActiveWithRepetition";
BA_DEF_ BU_  "ILUsed" ENUM  "No","Yes";
BA_DEF_  "Manufacturer" STRING ;
BA_DEF_ BO_  "GenMsgILSupport" ENUM  "No","Yes";
BA_DEF_ BO_  "DiagResponse" ENUM  "No","Yes";
BA_DEF_ BO_  "DiagRequest" ENUM  "No","Yes";
BA_DEF_  "BusType" STRING ;
BA_DEF_  "DBName" STRING ;
BA_DEF_ BO_  "GenMsgCycleTime" INT 0 65535;
BA_DEF_ BO_  "GenMsgSendType" ENUM  "Cyclic","NotUsed","NotUsed","NotUsed","NotUsed","NotUsed","NotUsed","IfActive","NoMsgSendType";
BA_DEF_ SG_  "GenSigStartValue" INT 0 1000000000;
BA_DEF_DEF_  "GenMsgStartDelayTime" 0;
BA_DEF_DEF_  "GenMsgMinAcceptLength" -1;
BA_DEF_DEF_  "DiagState" "No";
BA_DEF_DEF_  "GenMsgDelayTime" 0;
BA_DEF_DEF_  "GenSigSendType" "NoSigSendType";
BA_DEF_DEF_  "ILUsed" "No";
BA_DEF_DEF_  "Manufacturer" "PSA";
BA_DEF_DEF_  "GenMsgILSupport" "No";
BA_DEF_DEF_  "DiagResponse" "No";
BA_DEF_DEF_  "DiagRequest" "No";
BA_DEF_DEF_  "BusType" "";
BA_DEF_DEF_  "DBName" "";
BA_DEF_DEF_  "GenMsgCycleTime" 0;
BA_DEF_DEF_  "GenMsgSendType" "NoMsgSendType";
BA_DEF_DEF_  "GenSigStartValue" 0;
BA_ "BusType" "CAN";
BA_ "DBName" "PSA_BMPV";
BA_ "ILUsed" BU_ PSCM 1;
BA_ "GenMsgMinAcceptLength" BO_ 973 4;
BA_ "GenMsgILSupport" BO_ 973 1;
BA_ "GenMsgCycleTime" BO_ 973 10;
BA_ "GenMsgSendType" BO_ 973 0;
BA_ "GenMsgMinAcceptLength" BO_ 845 5;
BA_ "GenMsgILSupport" BO_ 845 1;
BA_ "GenMsgCycleTime" BO_ 845 20;
BA_ "GenMsgSendType" BO_ 845 0;
BA_ "GenMsgMinAcceptLength" BO_ 904 5;
BA_ "GenMsgILSupport" BO_ 904 1;
BA_ "GenMsgCycleTime" BO_ 904 40;
BA_ "GenMsgSendType" BO_ 904 0;
BA_ "GenMsgMinAcceptLength" BO_ 1042 8;
BA_ "GenMsgILSupport" BO_ 1042 1;
BA_ "GenMsgCycleTime" BO_ 1042 50;
BA_ "GenMsgSendType" BO_ 1042 0;
BA_ "GenMsgMinAcceptLength" BO_ 840 6;
BA_ "GenMsgCycleTime" BO_ 840 20;
BA_ "GenMsgILSupport" BO_ 840 1;
BA_ "GenMsgSendType" BO_ 840 0;
BA_ "GenMsgMinAcceptLength" BO_ 520 6;
BA_ "GenMsgCycleTime" BO_ 520 10;
BA_ "GenMsgILSupport" BO_ 520 1;
BA_ "GenMsgSendType" BO_ 520 0;
BA_ "GenMsgMinAcceptLength" BO_ 909 6;
BA_ "GenMsgCycleTime" BO_ 909 40;
BA_ "GenMsgSendType" BO_ 909 0;
VAL_ 840 ENGINE_COMMAND_STATE 7 "RESERVED" 6 "DegradedGO" 5 "GO" 4 "Stopped" 3 "Running" 2 "Starting" 1 "Cut" 0 "Locked" ;
; #############################################################################
; ############################### HS2 VAL #####################################
; #############################################################################

VAL_ 525 ANTILOCK_BRAKE_REGULATION 0 "Not in regulation" 1 "In regulation";
VAL_ 525 PARTICLE_FILTER_CONTROL_STRATEGY_ACTIVATION 0 "PFC_inactive" 1 "PFC_hold" 2 "PFC_active" 3 "Reserved";
VAL_ 551 DEGRADED_ENERGY_MODE 0 "no degraded mode" 1 "degraded mode in progress";
VAL_ 551 VALID_SHIFT_LEVER_POSITION_HYB_POWERTRAIN 0 "reserved" 1 "reverse" 2 "neutral" 3 "automatic" 4 "manual" 5 "reserved" 6 "reserved" 7 "reserved";
VAL_ 551 HYBRID_ACCEL_REQUEST_STATE 0 "IVC negative" 1 "IVC positive";
VAL_ 551 ACQUISITION_ASR_MSR 0 "Dialogue problem" 1 "Dialogue ok";
VAL_ 551 HYBRID_REAR_MOTOR_ROTATION_DIRECTION 0 "undetermined" 1 "forward" 2 "reverse" 3 "invalid";
VAL_ 551 HYBRID_REAR_ASR_MSR_ACQUISITION 0 "dialogue problem" 1 "dialogue ok";
VAL_ 551 HYBRID_REAR_GEAR_CHANGE_IN_PROGRESS 0 "no gear change in progress" 1 "gear change in progress";
VAL_ 551 HYBRID_REAR_COUPLING_STATE 0 "disengaged" 1 "engaged";
VAL_ 552 ENGINE_SPEED_OVERFLOW_INDICATOR 0 "unfiltered engine speed below threshold" 1 "reserved" 2 "unfiltered engine speed above threshold" 3 "Unavailable";
VAL_ 552 SECURITY_HARD_POINT 0 "Hard point not reached" 1 "Hard point reached";
VAL_ 552 AVAILABLE_HILL_ASSIST_TORQUE 0 "Torque unavailable" 1 "Torque available";
VAL_ 552 PRECISE_ENGINE_TORQUE 0 "Imprecise torque" 1 "Precise torque";
VAL_ 552 EASY_MOVE_TORQUE_UNCERTAIN 0 "Easy move torque guaranteed with required accuracy" 1 "Easy move torque not guaranteed with required accuracy" 2 "Reserved" 3 "Reserved";
VAL_ 552 DRAG_REDUCTION_AUTHORIZATION 0 "Drag reduction not authorized" 1 "Drag reduction authorized";
VAL_ 552 FREEWHEELING_REQUEST 0 "No intervention" 1 "FreeWheeling at Neutral requested" 2 "FreeWheeling depowered requested" 3 "Not used";
VAL_ 557 HYBRID_REAR_TORQUE_INHIBIT_REQUEST 0 "No request" 1 "Rear torque inhibition requested";
VAL_ 557 HYBRID_REAR_COUPLING_LOCK_REQUEST 0 "No request" 1 "Lock request";
VAL_ 557 HYBRID_REAR_TORQUE_OPEN_REQUEST 0 "No request" 1 "Open request";
VAL_ 557 HYBRID_COUPLE_DISTRIBUTION_LOCK_REQUEST 0 "No request" 1 "Lock request";
VAL_ 557 HYBRID_REAR_ESP_TORQUE_CONTROL_TYPE 0 "No torque action" 1 "Forbidden" 2 "Forbidden" 3 "Forbidden" 4 "Forbidden" 5 "Reduction command (ASR)" 6 "Increase command (MSR)" 7 "Forbidden";
VAL_ 584 POWERTRAIN_CLEARANCE_PASSAGE_STATUS 0 "Detection inactive" 1 "Detection in progress" 2 "Detection effective" 3 "Detection end";
VAL_ 653 HYBRID_REAR_TORQUE_INHIBIT_REQUEST 0 "No request" 1 "Rear torque inhibition requested";
VAL_ 653 HYBRID_COUPLE_DISTRIBUTION_LOCK_REQUEST 0 "No request" 1 "Lock request";
VAL_ 653 HYBRID_REAR_ASR_PREREGULATION 0 "No pre-regulation" 1 "Pre-regulation in progress";
VAL_ 653 EMPTY_STOP_AUTHORIZATION_HYBRID 0 "No stop authorization" 1 "Stop authorized";
VAL_ 653 HYBRID_EMPTY_START_REQUEST 0 "No request" 1 "Start request";
VAL_ 653 HYBRID_REAR_COUPLING_LOCK_REQUEST 0 "No request" 1 "Lock request";
VAL_ 653 HYBRID_REAR_TORQUE_OPEN_REQUEST 0 "No request" 1 "Open request";
VAL_ 653 HYBRID_REAR_ESP_TORQUE_CONTROL_TYPE 0 "No torque action" 1 "Forbidden" 2 "Forbidden" 3 "Forbidden" 4 "Forbidden" 5 "Reduction command (ASR)" 6 "Increase command (MSR)" 7 "Forbidden";
VAL_ 664 REGENERATIVE_BRAKING_STATE 0 "OK" 1 "NOK";
VAL_ 690 MULTIPLEX_DIAGNOSTIC_ON 0 "No communication diagnostic" 1 "Active communication diagnostic";
VAL_ 690 CRUISE_OR_SPEED_LIMITER_STATE 0 "RVV waiting / LVV waiting - LVV not effective" 1 "Accelerator pedal recovery RVV / Accelerator pedal recovery LVV" 2 "RVV active / LVV effective" 3 "RVV inhibited / LVV inhibited";
VAL_ 690 ENGINE_STATE 0 "Locked" 1 "Cut" 2 "Starting" 3 "Running" 4 "Stopped" 5 "Driven restart" 6 "Degraded restart" 7 "Preparing" 8 "Reserved" 9 "Reserved" 10 "Autonomous start" 11 "Reserved" 12 "Reserved" 13 "Autonomous restart" 14 "Reserved" 15 "Invalid";
VAL_ 694 GEAR_TYPE 0 "Downshift" 1 "Upshift";
VAL_ 694 REQUEST_ACTIVATE_WHEEL_TORQUE_POTENTIAL 0 "Not requested" 1 "Requested in GMP mode" 2 "Requested in Brake mode" 3 "Not used";
VAL_ 694 ACC_STATE 0 "Initialization" 1 "OFF" 2 "Inhibited" 3 "Waiting" 4 "Active" 5 "Suspended" 6 "Brake only" 7 "Waiting ramp" 8 "Reserved" 9 "Reserved" 10 "Reserved" 11 "Reserved" 12 "Reserved" 13 "Reserved" 14 "Reserved" 15 "Fault";
VAL_ 694 REQUEST_ACTIVATE_WHEEL_TORQUE 0 "Not requested" 1 "High range requested" 2 "Low range requested" 3 "Not used";
VAL_ 694 AUTOMATIC_BRAKE_STATE 0 "Unavailable" 1 "Initialization" 2 "Not used" 3 "Inhibited" 4 "Not used" 5 "Waiting" 6 "Active" 7 "Fault";
VAL_ 694 MDD_DECELERATION_TYPE 0 "No braking" 1 "ACC" 2 "FA_HV (high-speed automatic braking) / AFUi braking" 3 "FA_BV (low-speed automatic braking) / FARC2 braking";
VAL_ 694 REQUEST_PILOT_MDD_DECELERATION 0 "No pilot request UCF" 1 "Pilot request UCF";
VAL_ 694 PREFILL_REQUEST 0 "No prefill request" 1 "Prefill request";
VAL_ 728 ACC_CMM_STATE 0 "Stop" 1 "Initialization" 2 "Inhibited" 3 "Waiting" 4 "Active not effective" 5 "Active effective" 6 "Reserved" 7 "Fault";
VAL_ 728 ACC_INHIBITION_ON_REGIME 0 "No inhibition" 1 "Inhibition requested";
VAL_ 744 POWERTRAIN_MIN_GEAR 0 "Low fallback value" 1 "1st gear" 2 "2nd gear" 3 "3rd gear" 4 "4th gear" 5 "5th gear" 6 "6th gear" 7 "7th gear" 8 "8th gear" 9 "Reserved" 10 "Reserved" 11 "Reserved" 12 "Reserved" 13 "Reserved" 14 "Reserved" 15 "High fallback value";
VAL_ 744 POWERTRAIN_MAX_GEAR 0 "Low fallback value" 1 "1st gear" 2 "2nd gear" 3 "3rd gear" 4 "4th gear" 5 "5th gear" 6 "6th gear" 7 "7th gear" 8 "8th gear" 9 "Reserved" 10 "Reserved" 11 "Reserved" 12 "Reserved" 13 "Reserved" 14 "Reserved" 15 "High fallback value";
VAL_ 744 CURRENT_GEARBOX_DYNAMIC_MODE 0 "Normal" 1 "Sport" 2 "Eco" 3 "Snow";
VAL_ 744 POWERTRAIN_TORQUE_CONTROL_ACTIVE 0 "False" 1 "True";
VAL_ 744 POWERTRAIN_PILOTED_TRANSMISSION_STATUS 0 "No pilot request" 1 "Pilot requested or requested mode 1" 2 "Pilot requested in Fullpass mode or requested mode 2" 3 "Reserved or requested mode 3";
VAL_ 744 ENGINE_STATE_START_STOP 0 "Init" 1 "Active" 2 "Stop preparation" 3 "Stop in progress" 4 "Engine stopped" 5 "Redem under MEL" 6 "Autonomous restart" 7 "Engine ready to provide torque" 8 "Cut" 9 "Stalled" 10 "Reserved" 11 "Reserved" 12 "Reserved" 13 "Reserved" 14 "Reserved" 15 "Reserved";
VAL_ 758 DETECTED_TARGET 0 "initialization or no target detected" 1 "target detected";
VAL_ 758 RECOVERY_CONDITION_REQUEST 0 "No request" 1 "Non-critical request" 2 "Critical request" 3 "Invalid";
VAL_ 758 BLIND_SENSOR 0 "False" 1 "True";
VAL_ 758 COLLISION_VISUAL_ALERT_REQUEST 0 "no visual alert request" 1 "visual alert request";
VAL_ 758 COLLISION_AUDIO_ALERT_REQUEST 0 "no sound alert request" 1 "sound alert request";
VAL_ 758 COLLISION_HAPTIC_ALERT_REQUEST 0 "no haptic alert request" 1 "haptic alert request";
VAL_ 758 ARC_STATE 0 "unavailable" 1 "Not used" 2 "Not used" 3 "initialization" 4 "Not used" 5 "Not used" 6 "inhibited" 7 "Not used" 8 "Not used" 9 "Not used" 10 "waiting" 11 "Not used" 12 "active" 13 "Not used" 14 "Not used" 15 "fault";
VAL_ 758 BRAKE_INFO_IN_PROGRESS 0 "no braking in progress" 1 "braking in progress";
VAL_ 758 AUTOMATIC_EMERGENCY_BRAKING_ENABLED 0 "FALSE" 1 "TRUE";
VAL_ 758 DRIVE_AWAY_REQUEST 0 "No drive away required" 1 "Drive away required";
VAL_ 758 REQUEST_PILOT_MDD_DECELERATION 0 "No pilot request UCF" 1 "Pilot request UCF";
VAL_ 758 AUTOMATIC_BRAKE_STATE 0 "unavailable" 1 "initialization" 2 "not used" 3 "inhibited" 4 "not used" 5 "waiting" 6 "active" 7 "fault";
VAL_ 758 TARGET_POSITION 0 "POS1" 1 "POS2" 2 "POS3" 3 "POS4" 4 "POS5" 5 "POS6" 6 "POS7" 7 "Invalid";
VAL_ 761 INTERNAL_ERROR_RB 0 "No internal processing error detected" 1 "Internal processing error detected";
VAL_ 761 UNDER_OVER_VOLTAGE_RB 0 "No under voltage / Overvoltage detected" 1 "Under voltage / Overvoltage detected";
VAL_ 761 RAW_YAW_RATE_STATUS_RB 0 "Signal within measurement range" 1 "Temporary error" 2 "Permanent error" 3 "Sensor initializing";
VAL_ 761 RAW_LATERAL_ACCELERATION_STATUS_RB 0 "Signal within measurement range" 1 "Temporary error" 2 "Permanent error" 3 "Sensor initializing";
VAL_ 761 RAW_LONGITUDINAL_ACCELERATION_STATUS_RB 0 "Signal within measurement range" 1 "Temporary error" 2 "Permanent error" 3 "Sensor initializing";
VAL_ 792 BV_ENGAGED_CRAWL_FUNCTION_AVAILABLE 0 "Inactive" 1 "Active";
VAL_ 792 DISP_XVV_GMP_ACTIF 0 "Inactive" 1 "Active";
VAL_ 792 CPLE_ACC_EFFECTIF 0 "Torque requested by MDD not realized (Driver torque realized)" 1 "Torque requested by MDD realized";
VAL_ 792 DISP_XVV_CDT_FERMEE 0 "Inactive" 1 "Active";
VAL_ 802 EBDIAGACTIVE 0 "iBooster diagnostic inactive" 1 "iBooster diagnostic active";
VAL_ 802 EBB_BRAKE_PDLE_STATE 0 "Unavailable" 1 "Brake pedal released" 2 "Brake pedal pressed" 3 "Invalid";
VAL_ 802 CDA_REQUEST 0 "No_CDA_request" 1 "CDA_function_request";
VAL_ 802 RESIDUAL_PRESSURE_STRATEGY 0 "RPR_Passive" 1 "RPR_Preload" 2 "RPR_Hold" 3 "RPR_Suction" 4 "RPR_HoldLowPressure" 5 "RPR_Abort" 6 "Reserved" 7 "Reserved";
VAL_ 809 EXTENDED_STOP_AUTHORIZATION_BV 0 "Indefinite prohibition" 1 "Authorization" 2 "Medium duration prohibition" 3 "Long duration prohibition";
VAL_ 809 RESTART_AUTHORIZATION_BV 0 "Restart prohibited" 1 "Restart authorized";
VAL_ 809 STT_GEARBOX_FAULT 0 "Nominal" 1 "STT-identified gearbox fault";
VAL_ 809 RESTART_REQUEST_BV 0 "No restart needed" 1 "Restart requested";
VAL_ 809 STOP_AUTHORIZATION_BV 0 "No stop authorization" 1 "Stop authorization";
VAL_ 809 GEARBOX_STATE_STT 0 "normal operation" 1 "preparation for engine stop" 2 "engine stopping in progress" 3 "Stop" 4 "cranking" 5 "start" 6 "torque transmission" 7 "Reserved";
VAL_ 809 STOP_INHIBITION_BV 0 "No engine stop inhibition" 1 "Engine stop inhibited";
VAL_ 809 PADDLES_STATE 0 "No paddle action" 1 "Paddle + action" 2 "Paddle - action" 3 "Both paddles simultaneously";
VAL_ 809 POSITION_LEVER_P_N 0 "Reserved" 1 "Position N (Neutral) or P (Park)" 2 "Out of position N (Neutral) or P (Park)" 3 "Lever position sensor out of service or unavailable";
VAL_ 813 VALID_YAW_RATE_INFORMATION 0 "Valid information" 1 "Invalid information";
VAL_ 813 BRAKING_EFFORT 0 "No braking effort generated" 1 "Braking effort generated";
VAL_ 813 AUTOMATIC_BRAKE_DECELERATION_STATE 0 "Inhibited" 1 "Waiting" 2 "Active" 3 "Fault";
VAL_ 813 RECONSTRUCTED_BRAKE_INPUT 0 "Reconstructed brake input fault" 1 "No brake pedal press" 2 "Brake pedal pressed" 3 "Reserved";
VAL_ 813 PREFILL_EN_COURS 0 "False" 1 "True";
VAL_ 813 ACC_DECELERATION_STATE 0 "Inhibited" 1 "Waiting" 2 "Active" 3 "Fault";
VAL_ 813 VEHICLE_STANDSTILL 0 "NO_VEHICLE_STANDSTILL" 1 "VEHICLE_STANDSTILL";
VAL_ 813 DYNAMIC_BRAKING_IN_PROGRESS 0 "No dynamic braking in progress" 1 "Dynamic braking in progress";
VAL_ 813 BRAKE_RELEASED_FAILSAFE 0 "No release due to skid" 1 "ESC released brakes due to skid detection";
VAL_ 813 ERRONEOUS_BRAKING_EFFORT 0 "No erroneous braking effort" 1 "Erroneous braking effort";
VAL_ 813 VEHICLE_HOLD_BY_ADAS 0 "No vehicle hold by ADAS" 1 "Vehicle hold for comfort function" 2 "Vehicle hold for safety function" 3 "Reserved";
VAL_ 813 ACC_FAULT_FROM_BRAKE 0 "No ACC fault from brake perspective" 1 "ACC fault from brake perspective";
VAL_ 845 ESP_TORQUE_CONTROL_TYPE 0 "No torque action" 1 "Reserved" 2 "Reserved" 3 "Reserved" 4 "Reserved" 5 "Reduction command (ASR)" 6 "Increase command (MSR)" 7 "Reserved";
VAL_ 845 ASR_DISCONNECTED 0 "Connected by driver" 1 "Disconnected by driver";
VAL_ 845 ESP_FAULT_LAMP_REQUEST 0 "No request" 1 "Lighting request";
VAL_ 845 VDC_GEARBOX_LAW_REQUEST 0 "No request" 1 "VDC law request";
VAL_ 845 ESP_REGULATION 0 "Not in regulation" 1 "In regulation";
VAL_ 845 ESP_DISCONNECTED 0 "Connected by driver" 1 "Disconnected by driver";
VAL_ 845 SHIFT_AUTHORIZATION 0 "Shift forbidden" 1 "Downshift allowed" 2 "Upshift allowed" 3 "Downshift or upshift allowed";
VAL_ 845 PREFILL_EN_COURS 0 "False" 1 "True";
VAL_ 845 AUTOMATIC_BRAKE_DECELERATION_STATE 0 "Inhibited" 1 "Waiting" 2 "Active" 3 "Fault";
VAL_ 845 ASR_PLUS_STATE 0 "ASR+ in ESP OFF mode" 1 "ASR+ in Normal mode" 2 "ASR+ in Snow mode" 3 "ASR+ in Mud mode" 4 "ASR+ in Sand mode" 5 "Reserved" 6 "ASR+ selector fault" 7 "ESP ASR+ fault";
VAL_ 845 HILL_ASSIST_FUNCTION_STATE 0 "No hill assist hold in progress" 1 "Hill assist hold in progress" 2 "Reserved" 3 "Fault";
VAL_ 845 BASR_REGULATION 0 "Not in regulation" 1 "In regulation";
VAL_ 845 ASR_REGULATION 0 "Not in regulation" 1 "In regulation";
VAL_ 845 MSR_REGULATION 0 "Not in regulation" 1 "In regulation";
VAL_ 845 ESP_ONLY_REGULATION 0 "Not in regulation" 1 "In regulation";
VAL_ 845 AFU_REGULATION 0 "Not in regulation" 1 "In regulation";
VAL_ 845 ASR_ESP_REGULATION_LAMP_REQUEST 0 "No request" 1 "Lighting request";
VAL_ 909 VEHICLE_MOVEMENT 0 "Invalid" 1 "Vehicle moving" 2 "Vehicle stationary" 3 "Invalid";
VAL_ 909 VEHICLE_SPEED_INFO_VALIDITY 0 "Invalid" 1 "Speed information available" 2 "Speed information unavailable" 3 "Invalid";
VAL_ 909 DIRECTION_OF_TRAVEL 0 "Undetermined" 1 "Forward" 2 "Reverse" 3 "Invalid";
VAL_ 909 HILL_STOP_AUTHORIZATION_STT 0 "Hill Assist not ready for stop" 1 "Hill Assist ready for stop";
VAL_ 909 WARNING_LAMP_REQUEST 0 "No request" 1 "Lighting request";
VAL_ 909 HADC_FAULTY 0 "Nominal" 1 "Minor severity" 2 "Severe" 3 "Reserved";
VAL_ 909 HADC_STATUS 0 "HADC not selected" 1 "HADC waiting" 2 "HADC active" 3 "HADC in hydraulic braking regulation";
VAL_ 909 HADC_SPEED_CONDITION 0 "HADC speed condition not ok" 1 "HADC speed condition ok";
VAL_ 909 HADC_CLUTCH_CONDITION 0 "No clutch condition" 1 "Possible clutch function" 2 "Clutch function active" 3 "Reserved";
VAL_ 952 COASTING_STATE_CDT_OPTIPMI 0 "Without optiPMI" 1 "OptiPMI";
VAL_ 952 COASTING_STATE_CDT_DPT 0 "Without FreeWheeling depowered CdT" 1 "FreeWheeling depowered CdT";
VAL_ 952 COASTING_STATE_CDT_OPEN 0 "Without FreeWheeling open CdT" 1 "FreeWheeling open CdT";
VAL_ 952 COASTING_STATE 0 "No coasting state" 1 "Sailing" 2 "FreeWheeling open CdT" 4 "FreeWheeling depowered CdT" 8 "OptiPMI" 16 "Reserved" 32 "Reserved" 64 "Reserved" 128 "Reserved";
VAL_ 952 COASTING_STATE_SAILING 0 "Without sailing" 1 "Sailing";
VAL_ 952 CURRENT_PWT_DYN_CAPABILITY 0 "Eco mode and sport mode available" 1 "Eco mode available" 2 "Sport mode available" 3 "No mode available";
VAL_ 952 COASTING_STATE_RES_7 0 "Reserved inactive" 1 "Reserved active";
VAL_ 952 COASTING_STATE_RES_6 0 "Reserved inactive" 1 "Reserved active";
VAL_ 952 COASTING_STATE_RES_5 0 "Reserved inactive" 1 "Reserved active";
VAL_ 952 COASTING_STATE_RES_4 0 "Reserved inactive" 1 "Reserved active";
VAL_ 968 NEUTRAL_STATE 0 "Reserved" 1 "Not in neutral" 2 "Neutral" 3 "Invalid";
VAL_ 968 ENGINE_STOP_IN_PROGRESS 0 "No engine stopping in progress" 1 "Engine stopping in progress";
VAL_ 968 RESTART_TYPE 0 "Classic restart" 1 "Soft restart";
VAL_ 968 OPEN_CDT_REQUEST 0 "No request" 1 "CDT open request for stop" 2 "Reserved" 3 "Reserved";
VAL_ 1032 ABORT_CRITICITY_FOR_CPK 0 "Comfort" 1 "Urgent";
VAL_ 1032 PWT_STATUS_FOR_CPK 0 "Unavailable" 1 "Waiting" 2 "Active" 3 "Reserved";
VAL_ 1069 DYNAMIC_SLOPE_ACCURACY 0 "Good" 1 "Medium" 2 "Low" 3 "Undefined";
VAL_ 1069 STOP_LIGHTS_ACT_REQ 0 "FALSE" 1 "TRUE";
VAL_ 1070 ESP_MODE_REQUEST 0 "Normal" 1 "Snow" 2 "Mud" 3 "Sand" 4 "Reserved" 5 "Reserved" 6 "Reserved" 7 "Reserved";
VAL_ 973 LATERAL_ACCELERATION 32767 "Invalid" ;
VAL_ 845 ESP_FAULT_LAMP_REQUEST 1 "Request On" 0 "No Request" ;
VAL_ 845 ESP_REGULATION 1 "Active Regulation" 0 "No Regulation" ;
VAL_ 845 ESP_DISCONNECTED 1 "Disconnected" 0 "Connected" ;
VAL_ 904 VEHICLE_SPEED_BV 65535 "Invalid" ;
VAL_ 1042 DA_MODE_REQUEST 3 "Reserved" 2 "Adjustable Mode Request" 1 "Dynamic Mode Request" 0 "Normal Mode Request" ;
VAL_ 840 ENGINE_STATE 15 "Invalid" 13 "Autonomous Restart" 10 "Autonomous Starting" 7 "Engine Preparing" 6 "Degraded Restart" 5 "Driven Restart" 4 "Stopped" 3 "Running" 2 "Starting" 1 "Cut" 0 "Locked" ;
VAL_ 520 SCOM_DIAGNOSTICS 1 "Enable SCom Diagnostics" 0 "Disable SCom Diagnostics" ;
VAL_ 909 WHEEL_BASED_VEHICLE_SPEED 65535 "Invalid" ;
